VERSION "HNNBNNNYNNNNNNNNNNNNNNNNNNNNNNNNNNNNNNNNNN/4/%%%/4/'%**4NNN///"

NS_ :

BS_:

BU_: BMS_PlugIn CCU_VW526 GPM_PAG_PF Ladegeraet_PAG_PF LEH_PlugIn Motor_MED17_SIMOS8_PlugIn_PAG_PF Tester_DEV_PAG

BO_ 151 BMS_HYB_02: 8 BMS_PlugIn
 SG_ BMS_HYB_02_CHK : 0|8@1+ (1,0) [0|255] ""  Ladegeraet_PAG_PF,LEH_PlugIn,Motor_MED17_SIMOS8_PlugIn_PAG_PF
 SG_ BMS_HYB_02_BZ : 8|4@1+ (1,0) [0|15] ""  Ladegeraet_PAG_PF,LEH_PlugIn,Motor_MED17_SIMOS8_PlugIn_PAG_PF
 SG_ BMS_IstStrom : 12|12@1+ (0.25,-511) [-511|512.25] "Unit_Amper"  Ladegeraet_PAG_PF,LEH_PlugIn,Motor_MED17_SIMOS8_PlugIn_PAG_PF
 SG_ BMS_IstSpannung : 24|12@1+ (0.25,0) [0|1023.25] "Unit_Volt"  Ladegeraet_PAG_PF,LEH_PlugIn,Motor_MED17_SIMOS8_PlugIn_PAG_PF
 SG_ BMS_IstModus : 36|3@1+ (1,0) [0|7] ""  Ladegeraet_PAG_PF,LEH_PlugIn,Motor_MED17_SIMOS8_PlugIn_PAG_PF
 SG_ BMS_SleepInd : 39|1@1+ (1,0) [0|1] ""  Motor_MED17_SIMOS8_PlugIn_PAG_PF
 SG_ BMS_IsoMessungAktiv : 40|1@1+ (1,0) [0|1] ""  Ladegeraet_PAG_PF,LEH_PlugIn,Motor_MED17_SIMOS8_PlugIn_PAG_PF
 SG_ BMS_Init_abgeschlossen : 41|1@1+ (1,0) [0|1] ""  Ladegeraet_PAG_PF,LEH_PlugIn,Motor_MED17_SIMOS8_PlugIn_PAG_PF
 SG_ BMS_Status_Spgfreiheit : 42|2@1+ (1,0) [0|3] "" Vector__XXX
 SG_ BMS_Fehler_Notabschaltung_Crash : 49|1@1+ (1,0) [0|1] ""  Ladegeraet_PAG_PF,LEH_PlugIn,Motor_MED17_SIMOS8_PlugIn_PAG_PF
 SG_ BMS_Fehler_Notabschaltung_Pilot : 50|1@1+ (1,0) [0|1] ""  Ladegeraet_PAG_PF,LEH_PlugIn,Motor_MED17_SIMOS8_PlugIn_PAG_PF
 SG_ BMS_Fehler_HVBattAbschaltung_Anf : 51|1@1+ (1,0) [0|1] ""  Ladegeraet_PAG_PF,LEH_PlugIn,Motor_MED17_SIMOS8_PlugIn_PAG_PF
 SG_ BMS_Fehler_HVBattAbschaltung : 52|1@1+ (1,0) [0|1] ""  Ladegeraet_PAG_PF,LEH_PlugIn,Motor_MED17_SIMOS8_PlugIn_PAG_PF
 SG_ BMS_Fehler_HS_verschweisst : 53|1@1+ (1,0) [0|1] ""  Ladegeraet_PAG_PF,LEH_PlugIn,Motor_MED17_SIMOS8_PlugIn_PAG_PF
 SG_ BMS_Fehler_HS_offen : 54|1@1+ (1,0) [0|1] ""  Ladegeraet_PAG_PF
 SG_ BMS_Fehler_Leistungsred : 55|1@1+ (1,0) [0|1] ""  Ladegeraet_PAG_PF,LEH_PlugIn,Motor_MED17_SIMOS8_PlugIn_PAG_PF
 SG_ BMS_Fehler_Isolation : 56|1@1+ (1,0) [0|1] ""  Ladegeraet_PAG_PF,LEH_PlugIn,Motor_MED17_SIMOS8_PlugIn_PAG_PF
 SG_ BMS_Fehler_Kaltstartleistung : 57|1@1+ (1,0) [0|1] ""  Motor_MED17_SIMOS8_PlugIn_PAG_PF
 SG_ BMS_Fehler_Pilot : 58|1@1+ (1,0) [0|1] ""  Ladegeraet_PAG_PF
 SG_ BMS_Fehler_Sicherung : 59|1@1+ (1,0) [0|1] ""  Ladegeraet_PAG_PF
 SG_ BMS_Status_ServiceDisconnect : 60|1@1+ (1,0) [0|1] "" Vector__XXX
 SG_ BMS_Status_Spannungsfreiheit : 61|2@1+ (1,0) [0|3] "" Vector__XXX
 SG_ BMS_Notfallkuehlung : 63|1@1+ (1,0) [0|1] "" Vector__XXX

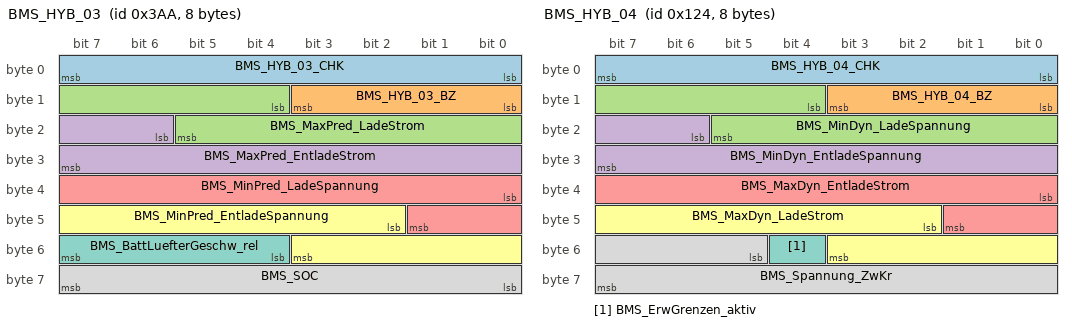
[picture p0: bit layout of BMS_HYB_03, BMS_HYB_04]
BO_ 938 BMS_HYB_03: 8 BMS_PlugIn
 SG_ BMS_HYB_03_CHK : 0|8@1+ (1,0) [0|255] ""  Ladegeraet_PAG_PF,LEH_PlugIn,Motor_MED17_SIMOS8_PlugIn_PAG_PF
 SG_ BMS_HYB_03_BZ : 8|4@1+ (1,0) [0|15] ""  Ladegeraet_PAG_PF,LEH_PlugIn,Motor_MED17_SIMOS8_PlugIn_PAG_PF
 SG_ BMS_MaxPred_LadeStrom : 12|10@1+ (1,0) [0|1022] "Unit_Amper"  Ladegeraet_PAG_PF,LEH_PlugIn,Motor_MED17_SIMOS8_PlugIn_PAG_PF
 SG_ BMS_MaxPred_EntladeStrom : 22|10@1+ (1,0) [0|1022] "Unit_Amper"  LEH_PlugIn,Motor_MED17_SIMOS8_PlugIn_PAG_PF
 SG_ BMS_MinPred_LadeSpannung : 32|10@1+ (1,0) [0|1022] "Unit_Volt"  LEH_PlugIn,Motor_MED17_SIMOS8_PlugIn_PAG_PF
 SG_ BMS_MinPred_EntladeSpannung : 42|10@1+ (1,0) [0|1022] "Unit_Volt"  LEH_PlugIn,Motor_MED17_SIMOS8_PlugIn_PAG_PF
 SG_ BMS_BattLuefterGeschw_rel : 52|4@1+ (10,0) [0|100] "Unit_PerCent"  LEH_PlugIn,Motor_MED17_SIMOS8_PlugIn_PAG_PF
 SG_ BMS_SOC : 56|8@1+ (0.4,0) [0|100] "Unit_PerCent"  Ladegeraet_PAG_PF,LEH_PlugIn,Motor_MED17_SIMOS8_PlugIn_PAG_PF

BO_ 292 BMS_HYB_04: 8 BMS_PlugIn
 SG_ BMS_HYB_04_CHK : 0|8@1+ (1,0) [0|255] ""  Ladegeraet_PAG_PF,LEH_PlugIn,Motor_MED17_SIMOS8_PlugIn_PAG_PF
 SG_ BMS_HYB_04_BZ : 8|4@1+ (1,0) [0|15] ""  Ladegeraet_PAG_PF,LEH_PlugIn,Motor_MED17_SIMOS8_PlugIn_PAG_PF
 SG_ BMS_MinDyn_LadeSpannung : 12|10@1+ (1,0) [0|1022] "Unit_Volt"  Ladegeraet_PAG_PF,LEH_PlugIn,Motor_MED17_SIMOS8_PlugIn_PAG_PF
 SG_ BMS_MinDyn_EntladeSpannung : 22|10@1+ (1,0) [0|1022] "Unit_Volt"  LEH_PlugIn,Motor_MED17_SIMOS8_PlugIn_PAG_PF
 SG_ BMS_MaxDyn_EntladeStrom : 32|10@1+ (1,0) [0|1022] "Unit_Amper"  LEH_PlugIn,Motor_MED17_SIMOS8_PlugIn_PAG_PF
 SG_ BMS_MaxDyn_LadeStrom : 42|10@1+ (1,0) [0|1022] "Unit_Amper"  Ladegeraet_PAG_PF,LEH_PlugIn,Motor_MED17_SIMOS8_PlugIn_PAG_PF
 SG_ BMS_ErwGrenzen_aktiv : 52|1@1+ (1,0) [0|1] ""  LEH_PlugIn,Motor_MED17_SIMOS8_PlugIn_PAG_PF
 SG_ BMS_Spannung_ZwKr : 53|11@1+ (0.5,0) [0|1022.5] "Unit_Volt" Vector__XXX

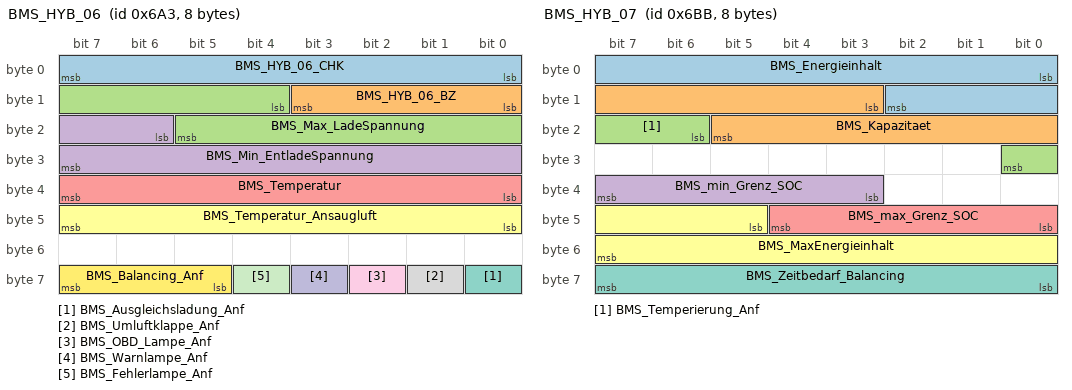
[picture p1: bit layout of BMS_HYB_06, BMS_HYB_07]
BO_ 1699 BMS_HYB_06: 8 BMS_PlugIn
 SG_ BMS_HYB_06_CHK : 0|8@1+ (1,0) [0|255] ""  Ladegeraet_PAG_PF,LEH_PlugIn,Motor_MED17_SIMOS8_PlugIn_PAG_PF
 SG_ BMS_HYB_06_BZ : 8|4@1+ (1,0) [0|15] ""  Ladegeraet_PAG_PF,LEH_PlugIn,Motor_MED17_SIMOS8_PlugIn_PAG_PF
 SG_ BMS_Max_LadeSpannung : 12|10@1+ (1,0) [0|1021] "Unit_Volt"  Ladegeraet_PAG_PF,LEH_PlugIn,Motor_MED17_SIMOS8_PlugIn_PAG_PF
 SG_ BMS_Min_EntladeSpannung : 22|10@1+ (1,0) [0|1021] "Unit_Volt"  Ladegeraet_PAG_PF,LEH_PlugIn,Motor_MED17_SIMOS8_PlugIn_PAG_PF
 SG_ BMS_Temperatur : 32|8@1+ (0.5,-40) [-40|86.5] "Unit_DegreCelsi"  Ladegeraet_PAG_PF,LEH_PlugIn,Motor_MED17_SIMOS8_PlugIn_PAG_PF
 SG_ BMS_Temperatur_Ansaugluft : 40|8@1+ (0.5,-40) [-40|86.5] "Unit_DegreCelsi"  LEH_PlugIn,Motor_MED17_SIMOS8_PlugIn_PAG_PF
 SG_ BMS_Ausgleichsladung_Anf : 56|1@1+ (1,0) [0|1] ""  Ladegeraet_PAG_PF,LEH_PlugIn,Motor_MED17_SIMOS8_PlugIn_PAG_PF
 SG_ BMS_Umluftklappe_Anf : 57|1@1+ (1,0) [0|1] ""  LEH_PlugIn,Motor_MED17_SIMOS8_PlugIn_PAG_PF
 SG_ BMS_OBD_Lampe_Anf : 58|1@1+ (1,0) [0|1] ""  LEH_PlugIn,Motor_MED17_SIMOS8_PlugIn_PAG_PF
 SG_ BMS_Warnlampe_Anf : 59|1@1+ (1,0) [0|1] ""  LEH_PlugIn,Motor_MED17_SIMOS8_PlugIn_PAG_PF
 SG_ BMS_Fehlerlampe_Anf : 60|1@1+ (1,0) [0|1] ""  LEH_PlugIn,Motor_MED17_SIMOS8_PlugIn_PAG_PF
 SG_ BMS_Balancing_Anf : 61|3@1+ (1,0) [0|7] "" Vector__XXX

BO_ 1723 BMS_HYB_07: 8 BMS_PlugIn
 SG_ BMS_Energieinhalt : 0|11@1+ (50,0) [0|102250] "Unit_WattHour"  Ladegeraet_PAG_PF,Motor_MED17_SIMOS8_PlugIn_PAG_PF
 SG_ BMS_Kapazitaet : 11|11@1+ (0.1,0) [0|204.6] "Unit_AmperHour"  Ladegeraet_PAG_PF,Motor_MED17_SIMOS8_PlugIn_PAG_PF
 SG_ BMS_Temperierung_Anf : 22|3@1+ (1,0) [0|7] ""  Ladegeraet_PAG_PF,Motor_MED17_SIMOS8_PlugIn_PAG_PF
 SG_ BMS_min_Grenz_SOC : 35|5@1+ (1,0) [0|30] "Unit_PerCent" Vector__XXX
 SG_ BMS_max_Grenz_SOC : 40|5@1+ (1,70) [70|100] "Unit_PerCent" Vector__XXX
 SG_ BMS_MaxEnergieinhalt : 45|11@1+ (50,0) [0|102250] "" Vector__XXX
 SG_ BMS_Zeitbedarf_Balancing : 56|8@1+ (1,0) [0|250] "Unit_Minut" Vector__XXX

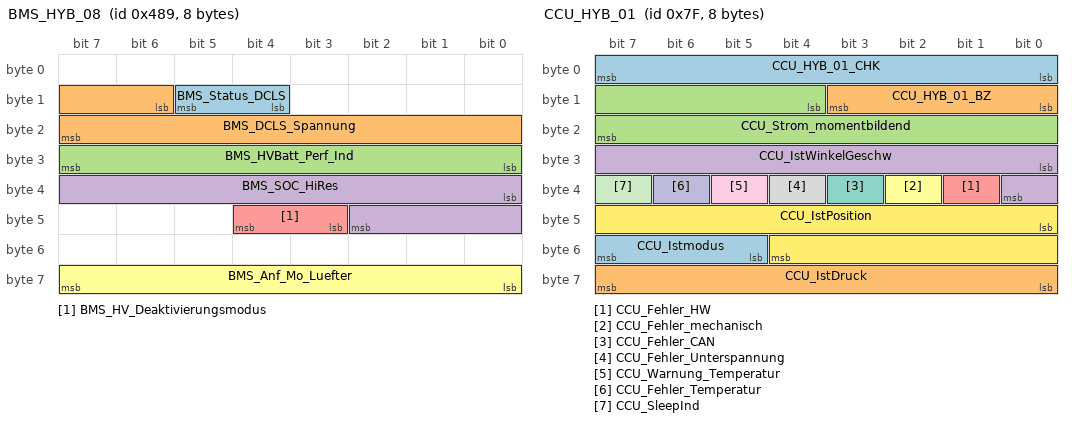
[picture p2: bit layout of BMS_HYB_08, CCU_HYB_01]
BO_ 1161 BMS_HYB_08: 8 BMS_PlugIn
 SG_ BMS_Status_DCLS : 12|2@1+ (1,0) [0|3] ""  Ladegeraet_PAG_PF
 SG_ BMS_DCLS_Spannung : 14|10@1+ (1,0) [0|1021] "Unit_Volt"  Ladegeraet_PAG_PF
 SG_ BMS_HVBatt_Perf_Ind : 24|8@1+ (0.4,0) [0|100] "Unit_PerCent"  Motor_MED17_SIMOS8_PlugIn_PAG_PF
 SG_ BMS_SOC_HiRes : 32|11@1+ (0.05,0) [0|100] "Unit_PerCent"  Motor_MED17_SIMOS8_PlugIn_PAG_PF
 SG_ BMS_HV_Deaktivierungsmodus : 43|2@1+ (1,0) [0|3] "" Vector__XXX
 SG_ BMS_Anf_Mo_Luefter : 56|8@1+ (0.4,0) [0|101.2] "Unit_PerCent"  Motor_MED17_SIMOS8_PlugIn_PAG_PF

BO_ 2617236992 CCP_BMS_CRO_01: 8 Tester_DEV_PAG
 SG_ CCP_BMS_CRO_01_Data : 0|64@1+ (1,0) [0|1] ""  BMS_PlugIn

BO_ 2281692672 CCP_BMS_CRO_02: 8 Tester_DEV_PAG
 SG_ CCP_BMS_CRO_02_Data : 0|64@1+ (1,0) [0|1] ""  BMS_PlugIn

BO_ 2617236993 CCP_BMS_DTO_01: 8 BMS_PlugIn
 SG_ CCP_BMS_DTO_01_Data : 0|64@1+ (1,0) [0|1] ""  Tester_DEV_PAG

BO_ 2281692673 CCP_BMS_DTO_02: 8 BMS_PlugIn
 SG_ CCP_BMS_DTO_02_Data : 0|64@1+ (1,0) [0|1] ""  Tester_DEV_PAG

BO_ 2617239041 CCP_EMotor_01_DTO_01: 8 LEH_PlugIn
 SG_ CCP_LE_DTO_01_Data : 0|64@1+ (1,0) [0|1] ""  Tester_DEV_PAG

BO_ 2566690560 CCP_GPM_CRO_01: 8 Tester_DEV_PAG
 SG_ CCP_GPM_CRO_01_Data : 0|64@1+ (1,0) [0|1] ""  GPM_PAG_PF

BO_ 2566690561 CCP_GPM_DTO_01: 8 GPM_PAG_PF
 SG_ CCP_GPM_DTO_01_Data : 0|64@1+ (1,0) [0|1] ""  Tester_DEV_PAG

BO_ 2617124352 CCP_Ladegeraet_CRO_01: 8 Tester_DEV_PAG
 SG_ CCP_Ladegeraet_CRO_01_Data : 0|64@1+ (1,0) [0|1.84467440737096E+019] ""  Ladegeraet_PAG_PF

BO_ 2617124353 CCP_Ladegeraet_DTO_01: 8 Ladegeraet_PAG_PF
 SG_ CCP_Ladegeraet_DTO_01_Data : 0|64@1+ (1,0) [0|1.84467440737096E+019] ""  Tester_DEV_PAG

BO_ 1666 CCP_LE_CRO_01: 8 Tester_DEV_PAG
 SG_ CCP_LE_CRO_01_Data : 0|64@1+ (1,0) [0|1] ""  LEH_PlugIn

BO_ 127 CCU_HYB_01: 8 CCU_VW526
 SG_ CCU_HYB_01_CHK : 0|8@1+ (1,0) [0|255] ""  Motor_MED17_SIMOS8_PlugIn_PAG_PF
 SG_ CCU_HYB_01_BZ : 8|4@1+ (1,0) [0|15] ""  Motor_MED17_SIMOS8_PlugIn_PAG_PF
 SG_ CCU_Strom_momentbildend : 12|12@1+ (0.25,-511) [-511|512.25] "Unit_Amper"  Motor_MED17_SIMOS8_PlugIn_PAG_PF
 SG_ CCU_IstWinkelGeschw : 24|9@1+ (200,-51000) [-51000|50800] "Unit_DegreOfArcPerSecon"  Motor_MED17_SIMOS8_PlugIn_PAG_PF
 SG_ CCU_Fehler_HW : 33|1@1+ (1,0) [0|1] ""  Motor_MED17_SIMOS8_PlugIn_PAG_PF
 SG_ CCU_Fehler_mechanisch : 34|1@1+ (1,0) [0|1] ""  Motor_MED17_SIMOS8_PlugIn_PAG_PF
 SG_ CCU_Fehler_CAN : 35|1@1+ (1,0) [0|1] ""  Motor_MED17_SIMOS8_PlugIn_PAG_PF
 SG_ CCU_Fehler_Unterspannung : 36|1@1+ (1,0) [0|1] ""  Motor_MED17_SIMOS8_PlugIn_PAG_PF
 SG_ CCU_Warnung_Temperatur : 37|1@1+ (1,0) [0|1] ""  Motor_MED17_SIMOS8_PlugIn_PAG_PF
 SG_ CCU_Fehler_Temperatur : 38|1@1+ (1,0) [0|1] ""  Motor_MED17_SIMOS8_PlugIn_PAG_PF
 SG_ CCU_SleepInd : 39|1@1+ (1,0) [0|1] ""  Motor_MED17_SIMOS8_PlugIn_PAG_PF
 SG_ CCU_IstPosition : 40|13@1+ (1,0) [0|6945] "Unit_DegreOfArc"  Motor_MED17_SIMOS8_PlugIn_PAG_PF
 SG_ CCU_Istmodus : 53|3@1+ (1,0) [0|7] ""  Motor_MED17_SIMOS8_PlugIn_PAG_PF
 SG_ CCU_IstDruck : 56|8@1+ (0.2,0) [0|50.6] "Unit_Bar"  Motor_MED17_SIMOS8_PlugIn_PAG_PF

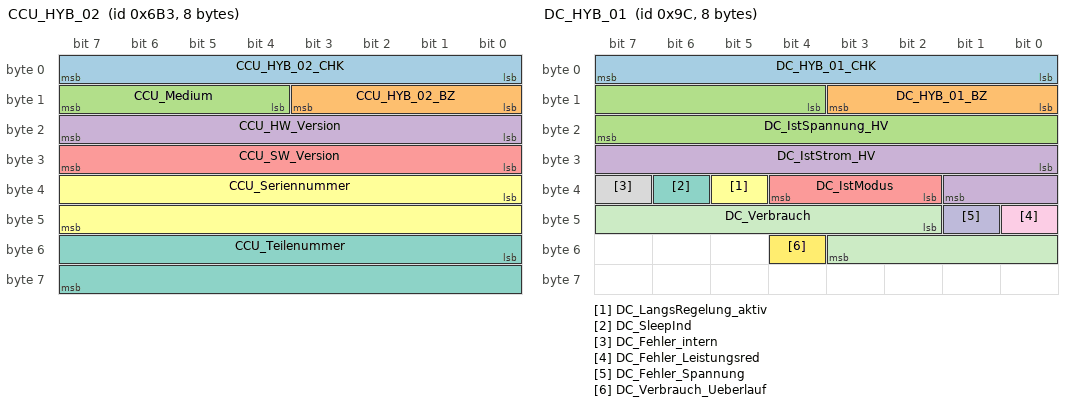
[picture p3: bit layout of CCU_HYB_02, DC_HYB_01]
BO_ 1715 CCU_HYB_02: 8 CCU_VW526
 SG_ CCU_HYB_02_CHK : 0|8@1+ (1,0) [0|255] ""  Motor_MED17_SIMOS8_PlugIn_PAG_PF
 SG_ CCU_HYB_02_BZ : 8|4@1+ (1,0) [0|15] ""  Motor_MED17_SIMOS8_PlugIn_PAG_PF
 SG_ CCU_Medium : 12|4@1+ (1,0) [0|15] ""  Motor_MED17_SIMOS8_PlugIn_PAG_PF
 SG_ CCU_HW_Version : 16|8@1+ (1,0) [0|255] ""  Motor_MED17_SIMOS8_PlugIn_PAG_PF
 SG_ CCU_SW_Version : 24|8@1+ (1,0) [0|255] ""  Motor_MED17_SIMOS8_PlugIn_PAG_PF
 SG_ CCU_Seriennummer : 32|16@1+ (1,0) [0|65535] ""  Motor_MED17_SIMOS8_PlugIn_PAG_PF
 SG_ CCU_Teilenummer : 48|16@1+ (1,0) [0|65535] ""  Motor_MED17_SIMOS8_PlugIn_PAG_PF

BO_ 156 DC_HYB_01: 8 LEH_PlugIn
 SG_ DC_HYB_01_CHK : 0|8@1+ (1,0) [0|255] ""  Motor_MED17_SIMOS8_PlugIn_PAG_PF
 SG_ DC_HYB_01_BZ : 8|4@1+ (1,0) [0|15] ""  Motor_MED17_SIMOS8_PlugIn_PAG_PF
 SG_ DC_IstSpannung_HV : 12|12@1+ (0.25,0) [0|1023.25] "Unit_Volt"  BMS_PlugIn,Motor_MED17_SIMOS8_PlugIn_PAG_PF
 SG_ DC_IstStrom_HV : 24|10@1+ (0.1,-51.1) [-51.1|51] "Unit_Amper"  BMS_PlugIn,Ladegeraet_PAG_PF,Motor_MED17_SIMOS8_PlugIn_PAG_PF
 SG_ DC_IstModus : 34|3@1+ (1,0) [0|7] ""  Motor_MED17_SIMOS8_PlugIn_PAG_PF
 SG_ DC_LangsRegelung_aktiv : 37|1@1+ (1,0) [0|1] ""  Motor_MED17_SIMOS8_PlugIn_PAG_PF
 SG_ DC_SleepInd : 38|1@1+ (1,0) [0|1] ""  Motor_MED17_SIMOS8_PlugIn_PAG_PF
 SG_ DC_Fehler_intern : 39|1@1+ (1,0) [0|1] ""  Motor_MED17_SIMOS8_PlugIn_PAG_PF
 SG_ DC_Fehler_Leistungsred : 40|1@1+ (1,0) [0|1] ""  Motor_MED17_SIMOS8_PlugIn_PAG_PF
 SG_ DC_Fehler_Spannung : 41|1@1+ (1,0) [0|1] ""  Motor_MED17_SIMOS8_PlugIn_PAG_PF
 SG_ DC_Verbrauch : 42|10@1+ (1,0) [0|1023] "Unit_WattSecond" Vector__XXX
 SG_ DC_Verbrauch_Ueberlauf : 52|1@1+ (1,0) [0|1] "" Vector__XXX

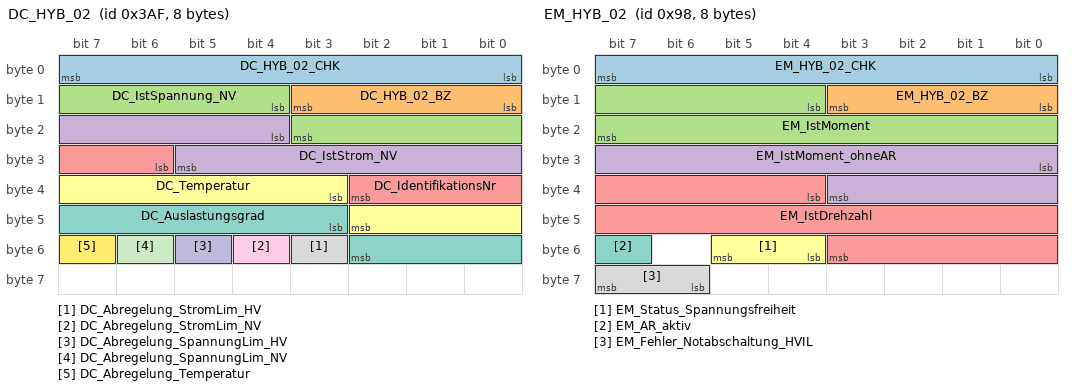
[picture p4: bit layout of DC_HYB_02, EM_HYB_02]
BO_ 943 DC_HYB_02: 8 LEH_PlugIn
 SG_ DC_HYB_02_CHK : 0|8@1+ (1,0) [0|255] ""  Motor_MED17_SIMOS8_PlugIn_PAG_PF
 SG_ DC_HYB_02_BZ : 8|4@1+ (1,0) [0|15] ""  Motor_MED17_SIMOS8_PlugIn_PAG_PF
 SG_ DC_IstSpannung_NV : 12|8@1+ (0.1,0) [0|25.3] "Unit_Volt"  Motor_MED17_SIMOS8_PlugIn_PAG_PF
 SG_ DC_IstStrom_NV : 20|10@1+ (1,-511) [-511|510] "Unit_Amper"  Motor_MED17_SIMOS8_PlugIn_PAG_PF
 SG_ DC_IdentifikationsNr : 30|5@1+ (1,0) [0|31] ""  Motor_MED17_SIMOS8_PlugIn_PAG_PF
 SG_ DC_Temperatur : 35|8@1+ (1,-40) [-40|213] "Unit_DegreCelsi"  Motor_MED17_SIMOS8_PlugIn_PAG_PF
 SG_ DC_Auslastungsgrad : 43|8@1+ (0.4,0) [0|101.6] "Unit_PerCent"  Motor_MED17_SIMOS8_PlugIn_PAG_PF
 SG_ DC_Abregelung_StromLim_HV : 51|1@1+ (1,0) [0|1] ""  Motor_MED17_SIMOS8_PlugIn_PAG_PF
 SG_ DC_Abregelung_StromLim_NV : 52|1@1+ (1,0) [0|1] ""  Motor_MED17_SIMOS8_PlugIn_PAG_PF
 SG_ DC_Abregelung_SpannungLim_HV : 53|1@1+ (1,0) [0|1] ""  Motor_MED17_SIMOS8_PlugIn_PAG_PF
 SG_ DC_Abregelung_SpannungLim_NV : 54|1@1+ (1,0) [0|1] ""  Motor_MED17_SIMOS8_PlugIn_PAG_PF
 SG_ DC_Abregelung_Temperatur : 55|1@1+ (1,0) [0|1] ""  Motor_MED17_SIMOS8_PlugIn_PAG_PF

BO_ 2617235968 DEV_BMS_Resp_00: 8 BMS_PlugIn
 SG_ DEV_BMS_Resp_00_Data : 0|64@1+ (1,0) [0|1.84467440737096E+019] ""  Tester_DEV_PAG

BO_ 2617235969 DEV_BMS_Resp_01: 8 BMS_PlugIn
 SG_ DEV_BMS_Resp_01_Data : 0|64@1+ (1,0) [0|1.84467440737096E+019] ""  Tester_DEV_PAG

BO_ 2617235970 DEV_BMS_Resp_02: 8 BMS_PlugIn
 SG_ DEV_BMS_Resp_02_Data : 0|64@1+ (1,0) [0|1.84467440737096E+019] ""  Tester_DEV_PAG

BO_ 2617235971 DEV_BMS_Resp_03: 8 BMS_PlugIn
 SG_ DEV_BMS_Resp_03_Data : 0|64@1+ (1,0) [0|1.84467440737096E+019] ""  Tester_DEV_PAG

BO_ 2617235972 DEV_BMS_Resp_04: 8 BMS_PlugIn
 SG_ DEV_BMS_Resp_04_Data : 0|64@1+ (1,0) [0|1.84467440737096E+019] ""  Tester_DEV_PAG

BO_ 2617235973 DEV_BMS_Resp_05: 8 BMS_PlugIn
 SG_ DEV_BMS_Resp_05_Data : 0|64@1+ (1,0) [0|1.84467440737096E+019] ""  Tester_DEV_PAG

BO_ 2617235974 DEV_BMS_Resp_06: 8 BMS_PlugIn
 SG_ DEV_BMS_Resp_06_Data : 0|64@1+ (1,0) [0|1.84467440737096E+019] ""  Tester_DEV_PAG

BO_ 2617235975 DEV_BMS_Resp_07: 8 BMS_PlugIn
 SG_ DEV_BMS_Resp_07_Data : 0|64@1+ (1,0) [0|1.84467440737096E+019] ""  Tester_DEV_PAG

BO_ 2566821632 DEV_GPM_Func_Req: 8 Tester_DEV_PAG
 SG_ DEV_GPM_Func_Req_Data : 0|64@1+ (1,0) [0|1.84467440737096E+019] ""  GPM_PAG_PF

BO_ 2566821633 DEV_GPM_Req_01: 8 Tester_DEV_PAG
 SG_ DEV_GPM_Req_01_Data : 0|64@1+ (1,0) [0|1.84467440737096E+019] ""  GPM_PAG_PF

BO_ 2566821634 DEV_GPM_Resp_01: 8 GPM_PAG_PF
 SG_ DEV_GPM_Resp_01_Data : 0|64@1+ (1,0) [0|1.84467440737096E+019] ""  Tester_DEV_PAG

BO_ 2617123328 DEV_Ladegeraet_Req_01: 8 Tester_DEV_PAG
 SG_ DEV_Ladegeraet_Req_01_Data : 0|64@1+ (1,0) [0|1.84467440737096E+019] ""  Ladegeraet_PAG_PF

BO_ 2617123329 DEV_Ladegeraet_Resp_01: 8 Ladegeraet_PAG_PF
 SG_ DEV_Ladegeraet_Resp_01_Data : 0|64@1+ (1,0) [0|1.84467440737096E+019] ""  Tester_DEV_PAG

BO_ 2617123330 DEV_Ladegeraet_Resp_02: 8 Ladegeraet_PAG_PF
 SG_ DEV_Ladegeraet_Resp_02_Data : 0|64@1+ (1,0) [0|1.84467440737096E+019] ""  Tester_DEV_PAG

BO_ 2617123331 DEV_Ladegeraet_Resp_03: 8 Ladegeraet_PAG_PF
 SG_ DEV_Ladegeraet_Resp_03_Data : 0|64@1+ (1,0) [0|1.84467440737096E+019] ""  Tester_DEV_PAG

BO_ 2617123332 DEV_Ladegeraet_Resp_04: 8 Ladegeraet_PAG_PF
 SG_ DEV_Ladegeraet_Resp_04_Data : 0|64@1+ (1,0) [0|1.84467440737096E+019] ""  Tester_DEV_PAG

BO_ 2617123333 DEV_Ladegeraet_Resp_05: 8 Ladegeraet_PAG_PF
 SG_ DEV_Ladegeraet_Resp_05_Data : 0|64@1+ (1,0) [0|1.84467440737096E+019] ""  Tester_DEV_PAG

BO_ 2617123334 DEV_Ladegeraet_Resp_06: 8 Ladegeraet_PAG_PF
 SG_ DEV_Ladegeraet_Resp_06_Data : 0|64@1+ (1,0) [0|1.84467440737096E+019] ""  Tester_DEV_PAG

BO_ 152 EM_HYB_02: 8 LEH_PlugIn
 SG_ EM_HYB_02_CHK : 0|8@1+ (1,0) [0|255] ""  Motor_MED17_SIMOS8_PlugIn_PAG_PF
 SG_ EM_HYB_02_BZ : 8|4@1+ (1,0) [0|15] ""  Motor_MED17_SIMOS8_PlugIn_PAG_PF
 SG_ EM_IstMoment : 12|12@1+ (0.25,-511) [-511|512.25] "Unit_NewtoMeter"  Motor_MED17_SIMOS8_PlugIn_PAG_PF
 SG_ EM_IstMoment_ohneAR : 24|12@1+ (0.25,-511) [-511|512.25] "Unit_NewtoMeter"  Motor_MED17_SIMOS8_PlugIn_PAG_PF
 SG_ EM_IstDrehzahl : 36|16@1+ (0.5,-10000) [-10000|22766.5] "Unit_MinutInver"  Motor_MED17_SIMOS8_PlugIn_PAG_PF
 SG_ EM_Status_Spannungsfreiheit : 52|2@1+ (1,0) [0|3] "" Vector__XXX
 SG_ EM_AR_aktiv : 55|1@1+ (1,0) [0|1] ""  Motor_MED17_SIMOS8_PlugIn_PAG_PF
 SG_ EM_Fehler_Notabschaltung_HVIL : 62|2@1+ (1,0) [0|3] "" Vector__XXX

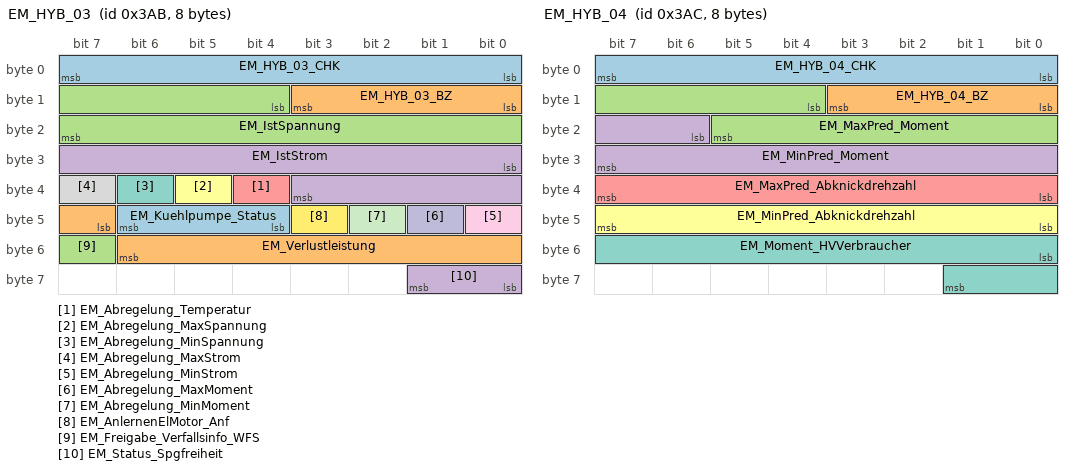
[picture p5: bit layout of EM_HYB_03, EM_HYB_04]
BO_ 939 EM_HYB_03: 8 LEH_PlugIn
 SG_ EM_HYB_03_CHK : 0|8@1+ (1,0) [0|255] ""  BMS_PlugIn,Motor_MED17_SIMOS8_PlugIn_PAG_PF
 SG_ EM_HYB_03_BZ : 8|4@1+ (1,0) [0|15] ""  BMS_PlugIn,Motor_MED17_SIMOS8_PlugIn_PAG_PF
 SG_ EM_IstSpannung : 12|12@1+ (0.25,0) [0|1023.25] "Unit_Volt"  BMS_PlugIn,Motor_MED17_SIMOS8_PlugIn_PAG_PF
 SG_ EM_IstStrom : 24|12@1+ (0.25,-511) [-511|512.25] "Unit_Amper"  Motor_MED17_SIMOS8_PlugIn_PAG_PF
 SG_ EM_Abregelung_Temperatur : 36|1@1+ (1,0) [0|1] ""  Motor_MED17_SIMOS8_PlugIn_PAG_PF
 SG_ EM_Abregelung_MaxSpannung : 37|1@1+ (1,0) [0|1] ""  Motor_MED17_SIMOS8_PlugIn_PAG_PF
 SG_ EM_Abregelung_MinSpannung : 38|1@1+ (1,0) [0|1] ""  Motor_MED17_SIMOS8_PlugIn_PAG_PF
 SG_ EM_Abregelung_MaxStrom : 39|1@1+ (1,0) [0|1] ""  Motor_MED17_SIMOS8_PlugIn_PAG_PF
 SG_ EM_Abregelung_MinStrom : 40|1@1+ (1,0) [0|1] ""  Motor_MED17_SIMOS8_PlugIn_PAG_PF
 SG_ EM_Abregelung_MaxMoment : 41|1@1+ (1,0) [0|1] ""  Motor_MED17_SIMOS8_PlugIn_PAG_PF
 SG_ EM_Abregelung_MinMoment : 42|1@1+ (1,0) [0|1] ""  Motor_MED17_SIMOS8_PlugIn_PAG_PF
 SG_ EM_AnlernenElMotor_Anf : 43|1@1+ (1,0) [0|1] ""  Motor_MED17_SIMOS8_PlugIn_PAG_PF
 SG_ EM_Kuehlpumpe_Status : 44|3@1+ (1,0) [0|7] "" Vector__XXX
 SG_ EM_Verlustleistung : 47|8@1+ (20,0) [0|5000] "Unit_Watt" Vector__XXX
 SG_ EM_Freigabe_Verfallsinfo_WFS : 55|1@1+ (1,0) [0|1] "" Vector__XXX
 SG_ EM_Status_Spgfreiheit : 56|2@1+ (1,0) [0|3] ""  BMS_PlugIn

BO_ 940 EM_HYB_04: 8 LEH_PlugIn
 SG_ EM_HYB_04_CHK : 0|8@1+ (1,0) [0|255] ""  Motor_MED17_SIMOS8_PlugIn_PAG_PF
 SG_ EM_HYB_04_BZ : 8|4@1+ (1,0) [0|15] ""  Motor_MED17_SIMOS8_PlugIn_PAG_PF
 SG_ EM_MaxPred_Moment : 12|10@1+ (1,-511) [-511|511] "Unit_NewtoMeter"  Motor_MED17_SIMOS8_PlugIn_PAG_PF
 SG_ EM_MinPred_Moment : 22|10@1+ (1,-511) [-511|511] "Unit_NewtoMeter"  Motor_MED17_SIMOS8_PlugIn_PAG_PF
 SG_ EM_MaxPred_Abknickdrehzahl : 32|8@1+ (50,0) [0|12700] "Unit_MinutInver"  Motor_MED17_SIMOS8_PlugIn_PAG_PF
 SG_ EM_MinPred_Abknickdrehzahl : 40|8@1+ (50,0) [0|12700] "Unit_MinutInver"  Motor_MED17_SIMOS8_PlugIn_PAG_PF
 SG_ EM_Moment_HVVerbraucher : 48|10@1+ (1,-511) [-511|511] "Unit_NewtoMeter"  Motor_MED17_SIMOS8_PlugIn_PAG_PF

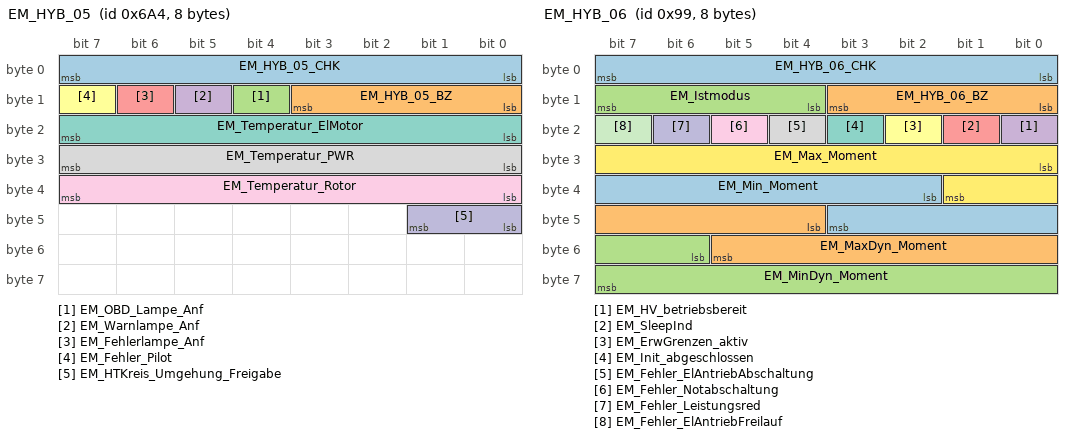
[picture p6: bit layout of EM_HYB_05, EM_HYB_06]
BO_ 1700 EM_HYB_05: 8 LEH_PlugIn
 SG_ EM_HYB_05_CHK : 0|8@1+ (1,0) [0|255] ""  Motor_MED17_SIMOS8_PlugIn_PAG_PF
 SG_ EM_HYB_05_BZ : 8|4@1+ (1,0) [0|15] ""  Motor_MED17_SIMOS8_PlugIn_PAG_PF
 SG_ EM_OBD_Lampe_Anf : 12|1@1+ (1,0) [0|1] ""  Motor_MED17_SIMOS8_PlugIn_PAG_PF
 SG_ EM_Warnlampe_Anf : 13|1@1+ (1,0) [0|1] ""  Motor_MED17_SIMOS8_PlugIn_PAG_PF
 SG_ EM_Fehlerlampe_Anf : 14|1@1+ (1,0) [0|1] ""  Motor_MED17_SIMOS8_PlugIn_PAG_PF
 SG_ EM_Fehler_Pilot : 15|1@1+ (1,0) [0|1] "" Vector__XXX
 SG_ EM_Temperatur_ElMotor : 16|8@1+ (1,-40) [-40|213] "Unit_DegreCelsi"  Motor_MED17_SIMOS8_PlugIn_PAG_PF
 SG_ EM_Temperatur_PWR : 24|8@1+ (1,-40) [-40|213] "Unit_DegreCelsi"  Motor_MED17_SIMOS8_PlugIn_PAG_PF
 SG_ EM_Temperatur_Rotor : 32|8@1+ (1,-40) [-40|213] "Unit_DegreCelsi"  Motor_MED17_SIMOS8_PlugIn_PAG_PF
 SG_ EM_HTKreis_Umgehung_Freigabe : 40|2@1+ (1,0) [0|3] ""  Motor_MED17_SIMOS8_PlugIn_PAG_PF

BO_ 153 EM_HYB_06: 8 LEH_PlugIn
 SG_ EM_HYB_06_CHK : 0|8@1+ (1,0) [0|255] ""  Motor_MED17_SIMOS8_PlugIn_PAG_PF
 SG_ EM_HYB_06_BZ : 8|4@1+ (1,0) [0|15] ""  Motor_MED17_SIMOS8_PlugIn_PAG_PF
 SG_ EM_Istmodus : 12|4@1+ (1,0) [0|15] ""  Motor_MED17_SIMOS8_PlugIn_PAG_PF
 SG_ EM_HV_betriebsbereit : 16|1@1+ (1,0) [0|1] ""  Motor_MED17_SIMOS8_PlugIn_PAG_PF
 SG_ EM_SleepInd : 17|1@1+ (1,0) [0|1] ""  Motor_MED17_SIMOS8_PlugIn_PAG_PF
 SG_ EM_ErwGrenzen_aktiv : 18|1@1+ (1,0) [0|1] ""  Motor_MED17_SIMOS8_PlugIn_PAG_PF
 SG_ EM_Init_abgeschlossen : 19|1@1+ (1,0) [0|1] ""  Motor_MED17_SIMOS8_PlugIn_PAG_PF
 SG_ EM_Fehler_ElAntriebAbschaltung : 20|1@1+ (1,0) [0|1] ""  Motor_MED17_SIMOS8_PlugIn_PAG_PF
 SG_ EM_Fehler_Notabschaltung : 21|1@1+ (1,0) [0|1] ""  Motor_MED17_SIMOS8_PlugIn_PAG_PF
 SG_ EM_Fehler_Leistungsred : 22|1@1+ (1,0) [0|1] ""  Motor_MED17_SIMOS8_PlugIn_PAG_PF
 SG_ EM_Fehler_ElAntriebFreilauf : 23|1@1+ (1,0) [0|1] ""  Motor_MED17_SIMOS8_PlugIn_PAG_PF
 SG_ EM_Max_Moment : 24|10@1+ (1,-511) [-511|511] "Unit_NewtoMeter"  Motor_MED17_SIMOS8_PlugIn_PAG_PF
 SG_ EM_Min_Moment : 34|10@1+ (1,-511) [-511|511] "Unit_NewtoMeter"  Motor_MED17_SIMOS8_PlugIn_PAG_PF
 SG_ EM_MaxDyn_Moment : 44|10@1+ (1,-511) [-511|511] "Unit_NewtoMeter"  Motor_MED17_SIMOS8_PlugIn_PAG_PF
 SG_ EM_MinDyn_Moment : 54|10@1+ (1,-511) [-511|511] "Unit_NewtoMeter"  Motor_MED17_SIMOS8_PlugIn_PAG_PF

BO_ 81 EM_HYB_07: 2 LEH_PlugIn
 SG_ EM_IstDrehzahl : 0|16@1+ (0.5,-10000) [-10000|22766.5] "Unit_MinutInver"  Motor_MED17_SIMOS8_PlugIn_PAG_PF

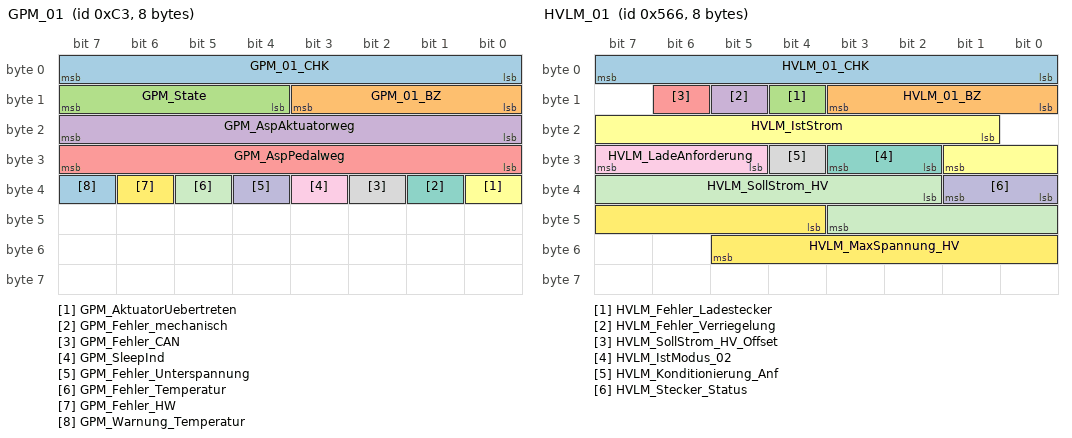
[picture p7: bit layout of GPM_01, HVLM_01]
BO_ 195 GPM_01: 8 GPM_PAG_PF
 SG_ GPM_01_CHK : 0|8@1+ (1,0) [0|255] ""  Motor_MED17_SIMOS8_PlugIn_PAG_PF
 SG_ GPM_01_BZ : 8|4@1+ (1,0) [0|15] ""  Motor_MED17_SIMOS8_PlugIn_PAG_PF
 SG_ GPM_State : 12|4@1+ (1,0) [0|15] ""  Motor_MED17_SIMOS8_PlugIn_PAG_PF
 SG_ GPM_AspAktuatorweg : 16|8@1+ (1,0) [0|100] "Unit_PerCent"  Motor_MED17_SIMOS8_PlugIn_PAG_PF
 SG_ GPM_AspPedalweg : 24|8@1+ (1,0) [0|100] "Unit_PerCent"  Motor_MED17_SIMOS8_PlugIn_PAG_PF
 SG_ GPM_AktuatorUebertreten : 32|1@1+ (1,0) [0|1] ""  Motor_MED17_SIMOS8_PlugIn_PAG_PF
 SG_ GPM_Fehler_mechanisch : 33|1@1+ (1,0) [0|1] ""  Motor_MED17_SIMOS8_PlugIn_PAG_PF
 SG_ GPM_Fehler_CAN : 34|1@1+ (1,0) [0|1] ""  Motor_MED17_SIMOS8_PlugIn_PAG_PF
 SG_ GPM_SleepInd : 35|1@1+ (1,0) [0|1] ""  Motor_MED17_SIMOS8_PlugIn_PAG_PF
 SG_ GPM_Fehler_Unterspannung : 36|1@1+ (1,0) [0|1] ""  Motor_MED17_SIMOS8_PlugIn_PAG_PF
 SG_ GPM_Fehler_Temperatur : 37|1@1+ (1,0) [0|1] ""  Motor_MED17_SIMOS8_PlugIn_PAG_PF
 SG_ GPM_Fehler_HW : 38|1@1+ (1,0) [0|1] ""  Motor_MED17_SIMOS8_PlugIn_PAG_PF
 SG_ GPM_Warnung_Temperatur : 39|1@1+ (1,0) [0|1] ""  Motor_MED17_SIMOS8_PlugIn_PAG_PF

BO_ 1705 GPM_02: 8 GPM_PAG_PF
 SG_ GPM_TeileNr_Mux M : 0|4@1+ (1,0) [0|15] ""  Motor_MED17_SIMOS8_PlugIn_PAG_PF
 SG_ GPM_TeileNr_Word_01 m0 : 16|16@1+ (1,0) [0|65535] ""  Motor_MED17_SIMOS8_PlugIn_PAG_PF
 SG_ GPM_TeileNr_Word_02 m1 : 16|16@1+ (1,0) [0|65535] ""  Motor_MED17_SIMOS8_PlugIn_PAG_PF
 SG_ GPM_TeileNr_Word_03 m2 : 16|16@1+ (1,0) [0|65535] ""  Motor_MED17_SIMOS8_PlugIn_PAG_PF
 SG_ GPM_TeileNr_Word_04 m3 : 16|16@1+ (1,0) [0|65535] ""  Motor_MED17_SIMOS8_PlugIn_PAG_PF
 SG_ GPM_TeileNr_Word_05 m4 : 16|16@1+ (1,0) [0|65535] ""  Motor_MED17_SIMOS8_PlugIn_PAG_PF
 SG_ GPM_TeileNr_Word_06 m5 : 16|16@1+ (1,0) [0|65535] ""  Motor_MED17_SIMOS8_PlugIn_PAG_PF
 SG_ GPM_TeileNr_Word_07 m6 : 16|16@1+ (1,0) [0|65535] ""  Motor_MED17_SIMOS8_PlugIn_PAG_PF
 SG_ GPM_TeileNr_Word_08 m7 : 16|16@1+ (1,0) [0|65535] ""  Motor_MED17_SIMOS8_PlugIn_PAG_PF
 SG_ GPM_TeileNr_Word_09 m8 : 16|16@1+ (1,0) [0|65535] ""  Motor_MED17_SIMOS8_PlugIn_PAG_PF
 SG_ GPM_TeileNr_Word_10 m9 : 16|16@1+ (1,0) [0|65535] ""  Motor_MED17_SIMOS8_PlugIn_PAG_PF
 SG_ GPM_TeileNr_Word_11 m10 : 16|16@1+ (1,0) [0|65535] ""  Motor_MED17_SIMOS8_PlugIn_PAG_PF
 SG_ GPM_TeileNr_Word_12 m11 : 16|16@1+ (1,0) [0|65535] ""  Motor_MED17_SIMOS8_PlugIn_PAG_PF
 SG_ GPM_TeileNr_Word_13 m12 : 16|16@1+ (1,0) [0|65535] ""  Motor_MED17_SIMOS8_PlugIn_PAG_PF
 SG_ GPM_TeileNr_Word_14 m13 : 16|16@1+ (1,0) [0|65535] ""  Motor_MED17_SIMOS8_PlugIn_PAG_PF
 SG_ GPM_TeileNr_Word_15 m14 : 16|16@1+ (1,0) [0|65535] ""  Motor_MED17_SIMOS8_PlugIn_PAG_PF
 SG_ GPM_TeileNr_Word_16 m15 : 16|16@1+ (1,0) [0|65535] ""  Motor_MED17_SIMOS8_PlugIn_PAG_PF
 SG_ GPM_Seriennummer : 32|16@1+ (1,0) [0|65535] ""  Motor_MED17_SIMOS8_PlugIn_PAG_PF
 SG_ GPM_HW_Version : 48|8@1+ (1,0) [0|255] ""  Motor_MED17_SIMOS8_PlugIn_PAG_PF
 SG_ GPM_SW_Version : 56|8@1+ (1,0) [0|255] ""  Motor_MED17_SIMOS8_PlugIn_PAG_PF

BO_ 1382 HVLM_01: 8 Ladegeraet_PAG_PF
 SG_ HVLM_01_CHK : 0|8@1+ (1,0) [0|255] ""  BMS_PlugIn,Motor_MED17_SIMOS8_PlugIn_PAG_PF
 SG_ HVLM_01_BZ : 8|4@1+ (1,0) [0|15] ""  BMS_PlugIn,Motor_MED17_SIMOS8_PlugIn_PAG_PF
 SG_ HVLM_Fehler_Ladestecker : 12|1@1+ (1,0) [0|1] "" Vector__XXX
 SG_ HVLM_Fehler_Verriegelung : 13|1@1+ (1,0) [0|1] "" Vector__XXX
 SG_ HVLM_SollStrom_HV_Offset : 14|1@1+ (1,0) [0|1] "" Vector__XXX
 SG_ HVLM_IstStrom : 17|9@1+ (1,-255) [-255|254] "Unit_Amper"  Motor_MED17_SIMOS8_PlugIn_PAG_PF
 SG_ HVLM_IstModus_02 : 26|2@1+ (1,0) [0|3] ""  Motor_MED17_SIMOS8_PlugIn_PAG_PF
 SG_ HVLM_Konditionierung_Anf : 28|1@1+ (1,0) [0|1] ""  Motor_MED17_SIMOS8_PlugIn_PAG_PF
 SG_ HVLM_LadeAnforderung : 29|3@1+ (1,0) [0|7] ""  Motor_MED17_SIMOS8_PlugIn_PAG_PF
 SG_ HVLM_Stecker_Status : 32|2@1+ (1,0) [0|3] ""  BMS_PlugIn,Motor_MED17_SIMOS8_PlugIn_PAG_PF
 SG_ HVLM_SollStrom_HV : 34|10@1+ (0.2,-102) [-102|102.2] "Unit_Amper" Vector__XXX
 SG_ HVLM_MaxSpannung_HV : 44|10@1+ (1,0) [0|1021] "Unit_Volt" Vector__XXX

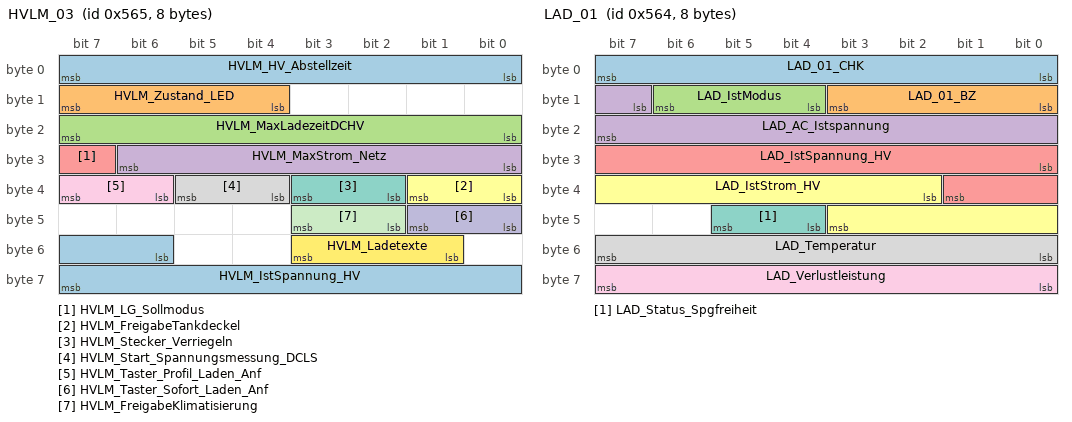
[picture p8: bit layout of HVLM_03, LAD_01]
BO_ 1381 HVLM_03: 8 Ladegeraet_PAG_PF
 SG_ HVLM_HV_Abstellzeit : 0|8@1+ (4,0) [0|1012] "Unit_Minut" Vector__XXX
 SG_ HVLM_Zustand_LED : 12|4@1+ (1,0) [0|15] "" Vector__XXX
 SG_ HVLM_MaxLadezeitDCHV : 16|8@1+ (10,0) [0|2530] "Unit_Minut" Vector__XXX
 SG_ HVLM_MaxStrom_Netz : 24|7@1+ (0.5,0) [0|62.5] "Unit_Amper" Vector__XXX
 SG_ HVLM_LG_Sollmodus : 31|1@1+ (1,0) [0|1] "" Vector__XXX
 SG_ HVLM_FreigabeTankdeckel : 32|2@1+ (1,0) [0|3] "" Vector__XXX
 SG_ HVLM_Stecker_Verriegeln : 34|2@1+ (1,0) [0|3] "" Vector__XXX
 SG_ HVLM_Start_Spannungsmessung_DCLS : 36|2@1+ (1,0) [0|3] ""  BMS_PlugIn
 SG_ HVLM_Taster_Profil_Laden_Anf : 38|2@1+ (1,0) [0|3] "" Vector__XXX
 SG_ HVLM_Taster_Sofort_Laden_Anf : 40|2@1+ (1,0) [0|3] "" Vector__XXX
 SG_ HVLM_FreigabeKlimatisierung : 42|2@1+ (1,0) [0|3] "" Vector__XXX
 SG_ HVLM_Ladetexte : 49|3@1+ (1,0) [0|7] "" Vector__XXX
 SG_ HVLM_IstSpannung_HV : 54|10@1+ (1,0) [0|1021] "Unit_Volt" Vector__XXX

BO_ 1380 LAD_01: 8 Ladegeraet_PAG_PF
 SG_ LAD_01_CHK : 0|8@1+ (1,0) [0|255] ""  BMS_PlugIn
 SG_ LAD_01_BZ : 8|4@1+ (1,0) [0|15] ""  BMS_PlugIn
 SG_ LAD_IstModus : 12|3@1+ (1,0) [0|7] "" Vector__XXX
 SG_ LAD_AC_Istspannung : 15|9@1+ (1,0) [0|509] "Unit_Volt" Vector__XXX
 SG_ LAD_IstSpannung_HV : 24|10@1+ (1,0) [0|1021] "Unit_Volt"  BMS_PlugIn
 SG_ LAD_IstStrom_HV : 34|10@1+ (0.2,-102) [-102|102.2] "Unit_Amper" Vector__XXX
 SG_ LAD_Status_Spgfreiheit : 44|2@1+ (1,0) [0|3] ""  BMS_PlugIn
 SG_ LAD_Temperatur : 48|8@1+ (1,-40) [-40|213] "Unit_DegreCelsi" Vector__XXX
 SG_ LAD_Verlustleistung : 56|8@1+ (20,0) [0|5060] "Unit_Watt" Vector__XXX

BO_ 1662 LAD_02: 8 Ladegeraet_PAG_PF
 SG_ LAD_02_CHK : 0|8@1+ (1,0) [0|255] "" Vector__XXX
 SG_ LAD_02_BZ : 8|4@1+ (1,0) [0|15] "" Vector__XXX
 SG_ LAD_Abregelung_Temperatur : 12|1@1+ (1,0) [0|1] "" Vector__XXX
 SG_ LAD_Abregelung_IU_Ein_Aus : 13|1@1+ (1,0) [0|1] "" Vector__XXX
 SG_ LAD_Abregelung_BuchseTemp : 14|1@1+ (1,0) [0|1] "" Vector__XXX
 SG_ LAD_Warnlampe_Anf : 15|1@1+ (1,0) [0|1] "" Vector__XXX
 SG_ LAD_MaxLadLeistung_HV : 16|9@1+ (100,0) [0|50900] "Unit_Watt" Vector__XXX
 SG_ LAD_CP_Stromlimit : 25|7@1+ (0.5,0) [0|62.5] "Unit_Amper" Vector__XXX
 SG_ LAD_PRX_Stromlimit : 32|3@1+ (1,0) [0|7] "" Vector__XXX
 SG_ LAD_CP_Erkennung : 35|1@1+ (1,0) [0|1] "" Vector__XXX
 SG_ LAD_Stecker_Verriegelt : 36|1@1+ (1,0) [0|1] "" Vector__XXX
 SG_ LAD_Stecker_Gesteckt : 37|1@1+ (1,0) [0|1] "" Vector__XXX
 SG_ LAD_Kuehlbedarf : 38|2@1+ (1,0) [0|3] ""  BMS_PlugIn
 SG_ LAD_MaxLadLeistung_HV_Offset : 57|2@1+ (1,0) [0|3] "" Vector__XXX
 SG_ LAD_Fehlerstatus : 59|3@1+ (1,0) [0|7] "" Vector__XXX
 SG_ LAD_Warnzustand : 62|1@1+ (1,0) [0|1] "" Vector__XXX
 SG_ LAD_Fehlerzustand : 63|1@1+ (1,0) [0|1] "" Vector__XXX

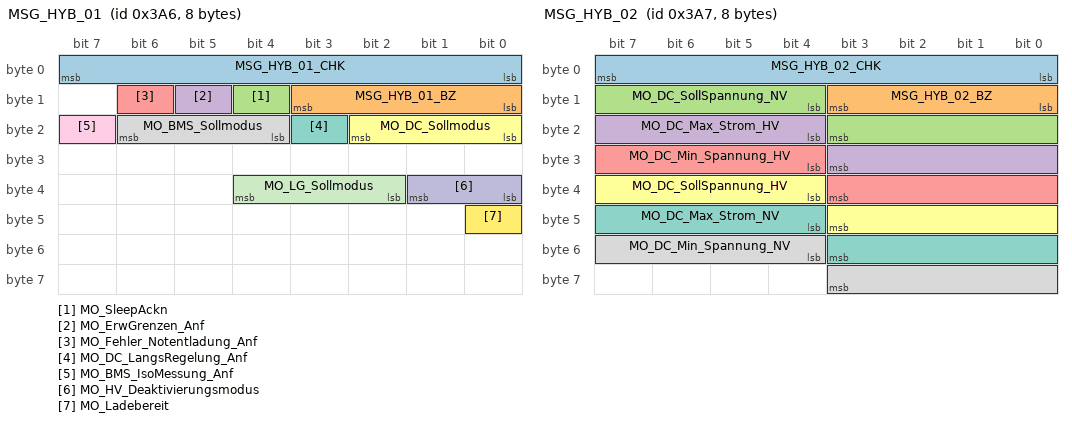
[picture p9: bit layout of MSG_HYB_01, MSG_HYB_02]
BO_ 934 MSG_HYB_01: 8 Motor_MED17_SIMOS8_PlugIn_PAG_PF
 SG_ MSG_HYB_01_CHK : 0|8@1+ (1,0) [0|255] ""  BMS_PlugIn,CCU_VW526,Ladegeraet_PAG_PF,LEH_PlugIn
 SG_ MSG_HYB_01_BZ : 8|4@1+ (1,0) [0|15] ""  BMS_PlugIn,CCU_VW526,Ladegeraet_PAG_PF,LEH_PlugIn
 SG_ MO_SleepAckn : 12|1@1+ (1,0) [0|1] ""  CCU_VW526,LEH_PlugIn
 SG_ MO_ErwGrenzen_Anf : 13|1@1+ (1,0) [0|1] ""  BMS_PlugIn,LEH_PlugIn
 SG_ MO_Fehler_Notentladung_Anf : 14|1@1+ (1,0) [0|1] ""  BMS_PlugIn,Ladegeraet_PAG_PF,LEH_PlugIn
 SG_ MO_DC_Sollmodus : 16|3@1+ (1,0) [0|7] ""  LEH_PlugIn
 SG_ MO_DC_LangsRegelung_Anf : 19|1@1+ (1,0) [0|1] ""  LEH_PlugIn
 SG_ MO_BMS_Sollmodus : 20|3@1+ (1,0) [0|7] ""  BMS_PlugIn
 SG_ MO_BMS_IsoMessung_Anf : 23|1@1+ (1,0) [0|1] ""  BMS_PlugIn
 SG_ MO_HV_Deaktivierungsmodus : 32|2@1+ (1,0) [0|3] "" Vector__XXX
 SG_ MO_LG_Sollmodus : 34|3@1+ (1,0) [0|7] ""  Ladegeraet_PAG_PF
 SG_ MO_Ladebereit : 40|1@1+ (1,0) [0|1] ""  Ladegeraet_PAG_PF

BO_ 935 MSG_HYB_02: 8 Motor_MED17_SIMOS8_PlugIn_PAG_PF
 SG_ MSG_HYB_02_CHK : 0|8@1+ (1,0) [0|255] ""  LEH_PlugIn
 SG_ MSG_HYB_02_BZ : 8|4@1+ (1,0) [0|15] ""  LEH_PlugIn
 SG_ MO_DC_SollSpannung_NV : 12|8@1+ (0.1,0) [0|25.4] "Unit_Volt"  LEH_PlugIn
 SG_ MO_DC_Max_Strom_HV : 20|8@1+ (0.2,0) [0|50.8] "Unit_Amper"  LEH_PlugIn
 SG_ MO_DC_Min_Spannung_HV : 28|8@1+ (2,0) [0|508] "Unit_Volt"  LEH_PlugIn
 SG_ MO_DC_SollSpannung_HV : 36|8@1+ (2,0) [0|508] "Unit_Volt"  LEH_PlugIn
 SG_ MO_DC_Max_Strom_NV : 44|8@1+ (2,0) [0|508] "Unit_Amper"  LEH_PlugIn
 SG_ MO_DC_Min_Spannung_NV : 52|8@1+ (0.1,0) [0|25.4] "Unit_Volt"  LEH_PlugIn

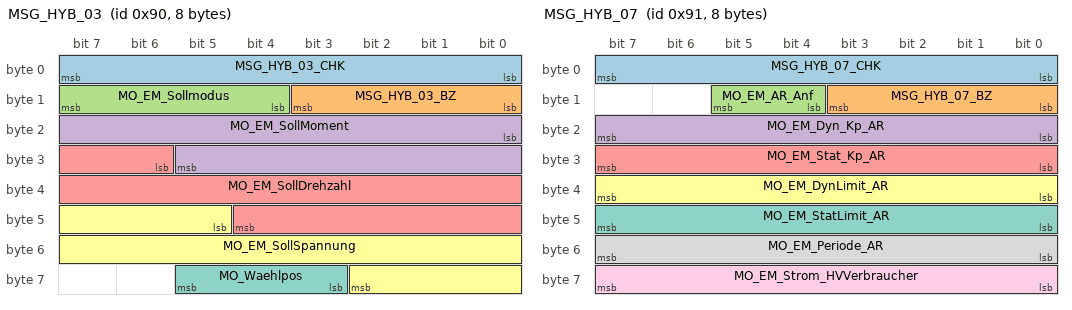
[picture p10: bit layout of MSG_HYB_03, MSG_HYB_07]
BO_ 144 MSG_HYB_03: 8 Motor_MED17_SIMOS8_PlugIn_PAG_PF
 SG_ MSG_HYB_03_CHK : 0|8@1+ (1,0) [0|255] ""  LEH_PlugIn
 SG_ MSG_HYB_03_BZ : 8|4@1+ (1,0) [0|15] ""  LEH_PlugIn
 SG_ MO_EM_Sollmodus : 12|4@1+ (1,0) [0|15] ""  LEH_PlugIn
 SG_ MO_EM_SollMoment : 16|14@1+ (0.1,-819.1) [-819.1|819.1] "Unit_NewtoMeter"  LEH_PlugIn
 SG_ MO_EM_SollDrehzahl : 30|15@1+ (1,-10000) [-10000|22766] "Unit_MinutInver"  LEH_PlugIn
 SG_ MO_EM_SollSpannung : 45|14@1+ (0.1,0) [0|1638.2] "Unit_Volt"  LEH_PlugIn
 SG_ MO_Waehlpos : 59|3@1+ (1,0) [0|7] "" Vector__XXX

BO_ 145 MSG_HYB_07: 8 Motor_MED17_SIMOS8_PlugIn_PAG_PF
 SG_ MSG_HYB_07_CHK : 0|8@1+ (1,0) [0|255] ""  LEH_PlugIn
 SG_ MSG_HYB_07_BZ : 8|4@1+ (1,0) [0|15] ""  LEH_PlugIn
 SG_ MO_EM_AR_Anf : 12|2@1+ (1,0) [0|3] ""  LEH_PlugIn
 SG_ MO_EM_Dyn_Kp_AR : 16|8@1+ (0.03125,0) [0|7.9375] "Unit_NewtoMeterPerRPM"  LEH_PlugIn
 SG_ MO_EM_Stat_Kp_AR : 24|8@1+ (0.03125,0) [0|7.9375] "Unit_NewtoMeterPerRPM"  LEH_PlugIn
 SG_ MO_EM_DynLimit_AR : 32|8@1+ (1,0) [0|254] "Unit_NewtoMeter"  LEH_PlugIn
 SG_ MO_EM_StatLimit_AR : 40|8@1+ (1,0) [0|254] "Unit_NewtoMeter"  LEH_PlugIn
 SG_ MO_EM_Periode_AR : 48|8@1+ (0.001953125,0) [0|0.49609375] "Unit_Secon"  LEH_PlugIn
 SG_ MO_EM_Strom_HVVerbraucher : 56|8@1+ (0.5,-63.5) [-63.5|63.5] "Unit_Amper"  LEH_PlugIn

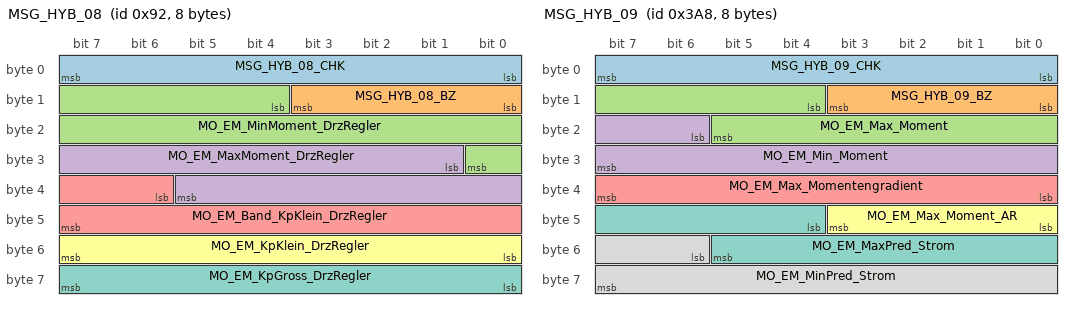
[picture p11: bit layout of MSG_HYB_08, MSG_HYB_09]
BO_ 146 MSG_HYB_08: 8 Motor_MED17_SIMOS8_PlugIn_PAG_PF
 SG_ MSG_HYB_08_CHK : 0|8@1+ (1,0) [0|255] ""  LEH_PlugIn
 SG_ MSG_HYB_08_BZ : 8|4@1+ (1,0) [0|15] ""  LEH_PlugIn
 SG_ MO_EM_MinMoment_DrzRegler : 12|13@1+ (0.2,-819) [-819|818.8] "Unit_NewtoMeter"  LEH_PlugIn
 SG_ MO_EM_MaxMoment_DrzRegler : 25|13@1+ (0.2,-819) [-819|818.8] "Unit_NewtoMeter"  LEH_PlugIn
 SG_ MO_EM_Band_KpKlein_DrzRegler : 38|10@1+ (1,0) [0|1022] "Unit_MinutInver"  LEH_PlugIn
 SG_ MO_EM_KpKlein_DrzRegler : 48|8@1+ (0.04,0) [0|10] "Unit_None"  LEH_PlugIn
 SG_ MO_EM_KpGross_DrzRegler : 56|8@1+ (0.04,0) [0|10] "Unit_None"  LEH_PlugIn

BO_ 936 MSG_HYB_09: 8 Motor_MED17_SIMOS8_PlugIn_PAG_PF
 SG_ MSG_HYB_09_CHK : 0|8@1+ (1,0) [0|255] ""  LEH_PlugIn
 SG_ MSG_HYB_09_BZ : 8|4@1+ (1,0) [0|15] ""  LEH_PlugIn
 SG_ MO_EM_Max_Moment : 12|10@1+ (1,-511) [-511|511] "Unit_NewtoMeter"  LEH_PlugIn
 SG_ MO_EM_Min_Moment : 22|10@1+ (1,-511) [-511|511] "Unit_NewtoMeter"  LEH_PlugIn
 SG_ MO_EM_Max_Momentengradient : 32|8@1+ (100,0) [0|25400] "Unit_NewtoMeterPerSecon"  LEH_PlugIn
 SG_ MO_EM_Max_Moment_AR : 40|4@1+ (15,0) [0|225] "Unit_NewtoMeter"  LEH_PlugIn
 SG_ MO_EM_MaxPred_Strom : 44|10@1+ (1,-511) [-511|511] "Unit_Amper" Vector__XXX
 SG_ MO_EM_MinPred_Strom : 54|10@1+ (1,-511) [-511|511] "Unit_Amper" Vector__XXX

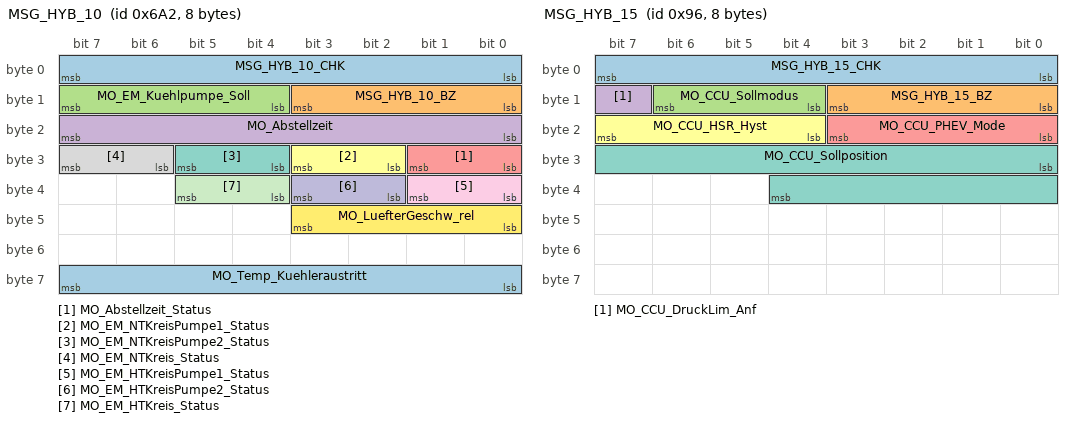
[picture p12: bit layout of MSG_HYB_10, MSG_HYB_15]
BO_ 1698 MSG_HYB_10: 8 Motor_MED17_SIMOS8_PlugIn_PAG_PF
 SG_ MSG_HYB_10_CHK : 0|8@1+ (1,0) [0|255] ""  BMS_PlugIn,LEH_PlugIn
 SG_ MSG_HYB_10_BZ : 8|4@1+ (1,0) [0|15] ""  BMS_PlugIn,LEH_PlugIn
 SG_ MO_EM_Kuehlpumpe_Soll : 12|4@1+ (10,0) [0|100] "Unit_PerCent" Vector__XXX
 SG_ MO_Abstellzeit : 16|8@1+ (8,0) [0|2024] "Unit_Minut"  BMS_PlugIn,LEH_PlugIn
 SG_ MO_Abstellzeit_Status : 24|2@1+ (1,0) [0|3] ""  BMS_PlugIn,LEH_PlugIn
 SG_ MO_EM_NTKreisPumpe1_Status : 26|2@1+ (1,0) [0|3] ""  LEH_PlugIn
 SG_ MO_EM_NTKreisPumpe2_Status : 28|2@1+ (1,0) [0|3] ""  LEH_PlugIn
 SG_ MO_EM_NTKreis_Status : 30|2@1+ (1,0) [0|3] ""  LEH_PlugIn
 SG_ MO_EM_HTKreisPumpe1_Status : 32|2@1+ (1,0) [0|3] ""  LEH_PlugIn
 SG_ MO_EM_HTKreisPumpe2_Status : 34|2@1+ (1,0) [0|3] ""  LEH_PlugIn
 SG_ MO_EM_HTKreis_Status : 36|2@1+ (1,0) [0|3] ""  LEH_PlugIn
 SG_ MO_LuefterGeschw_rel : 40|4@1+ (10,0) [0|100] "Unit_PerCent"  LEH_PlugIn
 SG_ MO_Temp_Kuehleraustritt : 56|8@1+ (0.75,-48) [-47.25|141.75] "Unit_DegreCelsi"  LEH_PlugIn

BO_ 150 MSG_HYB_15: 8 Motor_MED17_SIMOS8_PlugIn_PAG_PF
 SG_ MSG_HYB_15_CHK : 0|8@1+ (1,0) [0|255] ""  CCU_VW526
 SG_ MSG_HYB_15_BZ : 8|4@1+ (1,0) [0|15] ""  CCU_VW526
 SG_ MO_CCU_Sollmodus : 12|3@1+ (1,0) [0|7] ""  CCU_VW526
 SG_ MO_CCU_DruckLim_Anf : 15|1@1+ (1,0) [0|1] ""  CCU_VW526
 SG_ MO_CCU_PHEV_Mode : 16|4@1+ (1,0) [0|15] ""  CCU_VW526
 SG_ MO_CCU_HSR_Hyst : 20|4@1+ (1,0) [0|15] "Unit_DegreOfArc"  CCU_VW526
 SG_ MO_CCU_Sollposition : 24|13@1+ (1,0) [0|6945] "Unit_DegreOfArc"  CCU_VW526

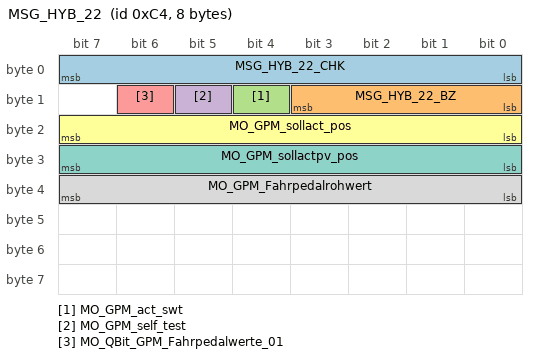
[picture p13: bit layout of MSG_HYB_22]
BO_ 196 MSG_HYB_22: 8 Motor_MED17_SIMOS8_PlugIn_PAG_PF
 SG_ MSG_HYB_22_CHK : 0|8@1+ (1,0) [0|255] ""  GPM_PAG_PF
 SG_ MSG_HYB_22_BZ : 8|4@1+ (1,0) [0|15] ""  GPM_PAG_PF
 SG_ MO_GPM_act_swt : 12|1@1+ (1,0) [0|1] ""  GPM_PAG_PF
 SG_ MO_GPM_self_test : 13|1@1+ (1,0) [0|1] ""  GPM_PAG_PF
 SG_ MO_QBit_GPM_Fahrpedalwerte_01 : 14|1@1+ (1,0) [0|1] ""  GPM_PAG_PF
 SG_ MO_GPM_sollact_pos : 16|8@1+ (1,0) [0|100] "Unit_PerCent"  GPM_PAG_PF
 SG_ MO_GPM_sollactpv_pos : 24|8@1+ (1,0) [0|100] "Unit_PerCent"  GPM_PAG_PF
 SG_ MO_GPM_Fahrpedalrohwert : 32|8@1+ (0.4,0) [0|101.6] "Unit_PerCent"  GPM_PAG_PF

CM_ "PAG_Plattform_CAN_Hybrid_0.0.1 Generated by BUSNETNG 8.4.2";
CM_ BU_ CCU_VW526 "Colorado NF";
CM_ BU_ LEH_PlugIn "Leistungselektronik Hybrid
Antriebs-CAN:	LEH_Hybrid
Hybrid-SubCAN:	DC_Hybrid + EM_Hybrid

Das Steuergerät fasst die beiden Komponenten DC/DC-Wandler (DC) und Elektromotor (EM) zusammen. Zur größeren Transparenz der Sender-Empfänger Beziehungen auf dem";
CM_ BU_ Motor_MED17_SIMOS8_PlugIn_PAG_PF "PlugIn Motoren";
CM_ SG_ 151 BMS_HYB_02_CHK "Berechnung siehe Konzern-Lastenheft A-CAN V4.2a
Checksummenendwert = 0x00";
CM_ SG_ 151 BMS_HYB_02_BZ "freilaufender Botschaftszähler";
CM_ SG_ 151 BMS_IstStrom "actual current of the battery / Momentanwert: Batteriestrom
Stromrichtung: ein Ladestrom wird mit positiven, ein Entladestrom mit negativen Werten angegeben";
CM_ SG_ 151 BMS_IstSpannung "actual voltage of the battery / Momentanwert: Batteriespannung";
CM_ SG_ 151 BMS_IstModus "actual state of the battery / momentaner Status der Batterie
0: Standby; Kommunikation aktiv
1: Hauptschütze geschlossen / HV-Netz aktiviert / normaler Fahrbetrieb
2: Hauptschütze geschlossen / Balancing-Modus aktiviert
3: externes Laden über Ladegerä";
CM_ SG_ 151 BMS_SleepInd "Die Sleep-Bereitschaft des BMS wird nach Rücknahme Klemme 15 durch Setzen dieses Bits signalisiert";
CM_ SG_ 151 BMS_IsoMessungAktiv "Isolationsmessung
0: inaktiv
1: aktiv";
CM_ SG_ 151 BMS_Init_abgeschlossen "Status BMS:
0: BMS befindet sich in Init- oder Nachlaufphase; CAN-Signalwerte entsprechen den Init-Werten (während Init-Phase), den physikalischen Werten (während Nachlauf-Phase)
1: BMS befindet sich im aktiven Zustand außerhalb Init- oder Nachlaufphase";
CM_ SG_ 151 BMS_Status_Spgfreiheit "0=Init (ohne Funktion)
1=BMS Zwischenkreis spannungsfrei (U_Zwkr < 20V)
2=BMS Zwischenkreis nicht spannungsfrei (U_Zwkr >/= 25V, Hysterese)
3=Fehler (z.B. Fehler in der Sensorik)";
CM_ SG_ 151 BMS_Fehler_Notabschaltung_Crash "Fehler: Sicherheitskritischer Fehler (Crash-Erkennung)
Batterieschütze sind bereits geöffnet / werden sofort geöffnet
Signal wird direkt vom EMS gelesen und initiiert einen AKS des PWR und eine aktive Entladung des Zwischenkreises";
CM_ SG_ 151 BMS_Fehler_Notabschaltung_Pilot "Fehler: Sicherheitskritischer Fehler (Abriss Pilotlinie / Deckel offen)
Batterieschütze sind bereits geöffnet / werden sofort geöffnet
Signal wird direkt vom EMS gelesen und initiiert einen AKS des PWR und eine aktive Entladung des Zwischenkreises";
CM_ SG_ 151 BMS_Fehler_HVBattAbschaltung_Anf "Fehler: Fehlerzustand, erfordert das Öffnen der Batterieschütze
interner Batteriefehler; Vorankündigung eines bevorstehenden Öffnens der Batterieschütze durch das BMS";
CM_ SG_ 151 BMS_Fehler_HVBattAbschaltung "Fehler: Fehlerzustand, erfordert das Öffnen der Batterieschütze
interner Batteriefehler, Batterieschütze ohne Vorankündigung durch das BMS geöffnet";
CM_ SG_ 151 BMS_Fehler_HS_verschweisst "Fehler: Hauptschütz(e) verschweißt";
CM_ SG_ 151 BMS_Fehler_HS_offen "Fehler: Hauptschütze schließen nicht / HV-Batterie nicht verfügbar
kann HV-Netz nicht aktivieren (z.B. defekte Schütze, Sicherung, Vorlade-Fehler)";
CM_ SG_ 151 BMS_Fehler_Leistungsred "Fehler: Leistungsfähigkeit der Batterie ist eingeschränkt (z.B. aufgrund des Ausfalls von Sensoren oder des Lüfters)";
CM_ SG_ 151 BMS_Fehler_Isolation "Fehler: Isolationsüberwachung";
CM_ SG_ 151 BMS_Fehler_Kaltstartleistung "Signalisiert, dass die Leistungsreserve der HV-Batterie für Kaltstart erschöpft ist, Indiz für Aktivierung Fremdladung";
CM_ SG_ 151 BMS_Fehler_Pilot "Signalisiert den Status der Pilotlinie BMS.";
CM_ SG_ 151 BMS_Fehler_Sicherung "Signalisiert den Zustand der im Service-Plug integrierten Hochvolt-Sicherung im BMS";
CM_ SG_ 151 BMS_Status_ServiceDisconnect "Status des Service Disconnect, ob dieser gesteckt oder gezogen ist.
Abhängigkeiten zu anderen Signalen: BMS_Fehler_Sicherung und BMS_Fehler_Pilot";
CM_ SG_ 151 BMS_Status_Spannungsfreiheit "Status der Spannungsfreiheit des BMS im Zwischenkreis. 
Abhängigkeiten zu anderen Signalen: BMS_Spannung_Zwkr";
CM_ SG_ 151 BMS_Notfallkuehlung "Anforderung der maximalen Kühlleistung im Notfall.";
CM_ SG_ 938 BMS_HYB_03_CHK "Berechnung siehe Konzern-Lastenheft A-CAN V4.2a
Checksummenendwert = 0x00";
CM_ SG_ 938 BMS_HYB_03_BZ "freilaufender Botschaftszähler";
CM_ SG_ 938 BMS_MaxPred_LadeStrom "dynamic el. limit, max. current (charge) for the specified time (~10s), and the voltage limit (only for prediction)  / rechnerischer Wert: quasistationärer, für eine Dauer von ~10s garantierter maximaler Ladestrom,
EV / PlugIn:
externes Laden (BMS_IstMo";
CM_ SG_ 938 BMS_MaxPred_EntladeStrom "dynamic el. limit, max. current (discharge) for the specified time (~10s): and the voltage limit (only for prediction) / rechnerischer Wert: quasistationärer, für eine Dauer von ~10s garantierter maximaler Entladestrom";
CM_ SG_ 938 BMS_MinPred_LadeSpannung "static el. limit, min. battery voltage (~10s) during current MaxPred_LadeStrom resp. iChPredMax / rechnerischer Wert: minimales, für eine Dauer von ~10s garantiertes Spannungsniveau, das unter Belastung mit MaxPred_LadeStrom bzw. iChPredMax nicht untersch";
CM_ SG_ 938 BMS_MinPred_EntladeSpannung "static el. limit, min. battery voltage (~10s) during current MaxPred_EntladeStrom resp iDisChPredMax / rechnerischer Wert: minimales, für eine Dauer von 10s garantiertes Spannungsniveau, das unter Belastung mit MaxPred_EntladeStrom bzw. iDisChPredMax nich";
CM_ SG_ 938 BMS_BattLuefterGeschw_rel "Relativwert der Batterielüfter-Ansteuerung bezogen auf Maximalwert";
CM_ SG_ 938 BMS_SOC "State of Charge / aktueller Ladezustand der Batterie";
CM_ SG_ 292 BMS_HYB_04_CHK "Berechnung siehe Konzern-Lastenheft A-CAN V4.2a
Checksummenendwert = 0x00";
CM_ SG_ 292 BMS_HYB_04_BZ "freilaufender Botschaftszähler";
CM_ SG_ 292 BMS_MinDyn_LadeSpannung "min. voltage during charge with current MaxDyn_LadeStrom resp. iChMax / rechnerischer Wert: minimales, für eine Dauer von ~1s garantiertes Spannungsniveau, das unter Belastung mit MaxDyn_LadeStrom bzw. iChMax nicht unterschritten werden würde
";
CM_ SG_ 292 BMS_MinDyn_EntladeSpannung "min. voltage during discharge with current MaxDyn_EntladeStrom resp. iDisChMax / rechnerischer Wert: minimales, für eine Dauer von ~1s garantiertes Spannungsniveau, das unter Belastung mit MaxDyn_EntladeStrom bzw. iDisChMax nicht unterschritten werden wür";
CM_ SG_ 292 BMS_MaxDyn_EntladeStrom "max current (discharge)  / maximal zulässiger Entladestrom (zwingend einzuhaltender Grenzwert); Wert ist für eine Dauer von 1s garantiert
";
CM_ SG_ 292 BMS_MaxDyn_LadeStrom "max current (charge) / maximal zulässiger Ladestrom (zwingend einzuhaltender Grenzwert); Wert ist für eine Dauer von 1s garantiert
(Im Balancing-Mode wird über diesen Wert der Ladestrom-Sollwert angegeben)
";
CM_ SG_ 292 BMS_ErwGrenzen_aktiv "die aktuellen Stromgrenzen der HV-Batterie sind zum Start des Verbrennungsmotors aufgeweitet / Bestätigung der Anforderung";
CM_ SG_ 292 BMS_Spannung_ZwKr "Momentanwert: 
Spannung an den Batterie-HV-Anschlüssen";
CM_ BO_ 1699 "MLB";
CM_ SG_ 1699 BMS_HYB_06_CHK "Berechnung siehe Konzern-Lastenheft A-CAN V4.2a
Checksummenendwert = 0x00";
CM_ SG_ 1699 BMS_HYB_06_BZ "freilaufender Botschaftszähler";
CM_ SG_ 1699 BMS_Max_LadeSpannung "max. voltage / maximal erlaubte Batteriespannung (zwingend einzuhaltender Grenzwert)";
CM_ SG_ 1699 BMS_Min_EntladeSpannung "min. voltage / minimal erlaubte Batteriespannung (zwingend einzuhaltender Grenzwert)";
CM_ SG_ 1699 BMS_Temperatur "battery temperature / Momentanwert: Temperatur der Traktionsbatterie";
CM_ SG_ 1699 BMS_Temperatur_Ansaugluft "Temperature of inlet air / Momentanwert: Ansauglufttemperatur der Batteriekühlung";
CM_ SG_ 1699 BMS_Ausgleichsladung_Anf "BMS wünscht eine Ausgleichsladung
Flag derzeit ungenutzt, da BalancingModus im Detail noch nicht geklärt.";
CM_ SG_ 1699 BMS_Umluftklappe_Anf "BMS fordert bei Climatronic die Öffnung der Umluftklappe an; Signal muss vom MSG auf den A-CAN gegated werden";
CM_ SG_ 1699 BMS_OBD_Lampe_Anf "Anforderung MIL (MalfunctionIndicationLamp) von BMS (Motorsteuergerät reicht diese Info an Kombi weiter).";
CM_ SG_ 1699 BMS_Warnlampe_Anf "Anforderung der gelben Hybrid-Warnlampe im Kombi";
CM_ SG_ 1699 BMS_Fehlerlampe_Anf "Anforderung der roten Hybrid-Warnlampe im Kombi";
CM_ SG_ 1699 BMS_Balancing_Anf "Mitteilung des BMS an den Lademanager/(Gateway) in welchem Balancing Status sich das BMS befindet.";
CM_ SG_ 1723 BMS_Energieinhalt "aktuell nutzbarer Energieinhalt der HV-Batterie
(bezogen auf ein definiertes mittleres Belastungsprofil)";
CM_ SG_ 1723 BMS_Kapazitaet "Gesamtenergiekapazitaet der HV-Batterie unter Berücksichtigung der Alterung";
CM_ SG_ 1723 BMS_Temperierung_Anf "Temperierungsbedarf der HV-Batterie";
CM_ SG_ 1723 BMS_min_Grenz_SOC "unterer Grenz SOC - Betriebsstrategie";
CM_ SG_ 1723 BMS_max_Grenz_SOC "oberer Grenz SOC - Betriebsstrategie";
CM_ SG_ 1723 BMS_MaxEnergieinhalt "maximaler nutzbarer Energieinhalt der HV-Batterie (bezogen auf Last KBI_RWDS_Lastprofil bei SOC=100%)
Abhängig von KBI_RWDS_Lastprofil";
CM_ SG_ 1723 BMS_Zeitbedarf_Balancing "Enthält die geschätzte Restzeitdauer um Ladungsdifferenzen zwischen den Zellen auszugleichen.";
CM_ SG_ 1161 BMS_Status_DCLS "Status der Spannungsüberwachung an der DC-Ladeschnittstelle";
CM_ SG_ 1161 BMS_DCLS_Spannung "DC-Spannung der Ladesäule.
Messung zwischen den DC HV-Leitungen.";
CM_ SG_ 1161 BMS_HVBatt_Perf_Ind "Leistungsindikation (Leistungsabgabe).
Prozentualer Wert der unter Berücksichtigung der Belastungshistorie und des Betriebspunktes die über die Dauerleistung der Batterie hinausgehende Leistungsreserve angibt (z. B. für Überholvorgänge).";
CM_ SG_ 1161 BMS_SOC_HiRes "State of Charge / aktueller Ladezustand der Batterie (höhere Auflösung)";
CM_ SG_ 1161 BMS_HV_Deaktivierungsmodus "Das Signal beschreibt ob das BMS mittels VAS-Tester deaktiviert wurde. In diesem Fall ist kein Zuschalten der Schütze mehr möglich.";
CM_ SG_ 1161 BMS_Anf_Mo_Luefter "Anforderung des Motorluefters bie Kuehlung ueber den NT-Kuehler";
CM_ BO_ 1666 "CCP in Serie mit 11Bit - Empfangskanal";
CM_ BO_ 127 "MLB";
CM_ SG_ 127 CCU_HYB_01_CHK "Berechnung siehe Konzern-Lastenheft A-CAN V4.2a
Checksummenendwert = 0x00";
CM_ SG_ 127 CCU_HYB_01_BZ "freilaufender Botschaftszaehler";
CM_ SG_ 127 CCU_Strom_momentbildend "Drehmomentbildender Strom Aktuator";
CM_ SG_ 127 CCU_IstWinkelGeschw "Winkelgeschwindigkeit Aktuator";
CM_ SG_ 127 CCU_Fehler_HW "HW Fehler im Aktuator festgestellt";
CM_ SG_ 127 CCU_Fehler_mechanisch "Systemdruckniveau Aktuator in Nullposition > erlaubter Schwelle";
CM_ SG_ 127 CCU_Fehler_CAN "CAN Fehler Aktuator festgestellt";
CM_ SG_ 127 CCU_Fehler_Unterspannung "Unterspannung Aktuator festgestellt";
CM_ SG_ 127 CCU_Warnung_Temperatur "Erhoehte CPU Temperatur bzw. erhoehtes Motor Stromintegral Aktuator festgestellt";
CM_ SG_ 127 CCU_Fehler_Temperatur "Kritische CPU Temperatur bzw. kritisches Motor Stromintegral Aktuator festgestellt";
CM_ SG_ 127 CCU_SleepInd "Die Sleep-Bereitschaft wird nach Rücknahme von Klemme 15 durch Setzen dieses Bits signalisiert";
CM_ SG_ 127 CCU_IstPosition "Position Aktuator";
CM_ SG_ 127 CCU_Istmodus "Modus Aktuator
0: Init Mode
1: Secure_Mode 
2: Operation_Mode
3: RemovingAir_Mode
4: Filling_Mode
5...6: reserve
7: Initialisierung
Anmerkung: bei PL71 initialisiert die CCU noch mit '0'";
CM_ SG_ 127 CCU_IstDruck "Systemdruck Aktuator";
CM_ BO_ 1715 "MLB";
CM_ SG_ 1715 CCU_HYB_02_CHK "Berechnung siehe Konzern-Lastenheft A-CAN V4.2a
Checksummenendwert = 0x00";
CM_ SG_ 1715 CCU_HYB_02_BZ "freilaufender Botschaftszaehler";
CM_ SG_ 1715 CCU_Medium "Verwendetes Medium Aktuator
4: Mineraloel_Pentosin
7: Bremsfluessigkeit";
CM_ SG_ 1715 CCU_HW_Version "Hardware Stand Aktuator
0: A0_Muster
1: A1_Muster
2: A2_Muster
3: B0_Muster
4: B1_Muster
5: B2_Muster
6: B3_Muster
7: C0_Muster
8: C1_Muster
9: C2_Muster
10: Nullserie
255: Zwischenstand";
CM_ SG_ 1715 CCU_SW_Version "Software Stand Aktuator
105: v105
106: v106
107: v107
108: v108
109: v109";
CM_ SG_ 1715 CCU_Seriennummer "Laufende Nummer Aktuator";
CM_ SG_ 1715 CCU_Teilenummer "OEM spezifische Teilenummer Aktuator";
CM_ BO_ 156 "MLB
Berechnung siehe Konzern-Lastenheft A-CAN V4.2a
Checksummenendwert = 0x00";
CM_ SG_ 156 DC_HYB_01_CHK "Berechnung siehe Konzern-Lastenheft A-CAN V4.2a
Checksummenendwert = 0x00";
CM_ SG_ 156 DC_HYB_01_BZ "freilaufender Botschaftszähler";
CM_ SG_ 156 DC_IstSpannung_HV "Momentanwert:  Hochspannung am DC/DC Wandler";
CM_ SG_ 156 DC_IstStrom_HV "Momentanwert:  Strom aus dem Traktionsnetz in den DC/DC Wandler";
CM_ SG_ 156 DC_IstModus "aktuelle Betriebsart des DC/DC Wandlers;
0: Standby; Kommunikation aktiv
1: Tiefsetzen_1 (HV --> BN 14,4V)
    Sollwertvorgabe projektabhängig vom BSG/BCM über Lin/BSS oder vom MSG über 'MO_DC_SollSpannung_NV' bzw. 'MY2_DC_uSetPLV'
    (PQ35/PL71: Sol";
CM_ SG_ 156 DC_LangsRegelung_aktiv "aktueller Regelmode des DC/DC-Wandlers:
1: langsame Regelung
0: normale Regelung";
CM_ SG_ 156 DC_SleepInd "Die Sleep-Bereitschaft wird nach Rücknahme von Klemme 15 durch Setzen dieses Bits signalisiert";
CM_ SG_ 156 DC_Fehler_intern "Fehler: DC/DC-Wandler ist aufgrund eines internen Hardware-Fehlers abgeschaltet";
CM_ SG_ 156 DC_Fehler_Leistungsred "Fehler: eingeschränkte Leistungsfähigkeit des DC/DC-Wandlers aufgrund eines internen Fehlers";
CM_ SG_ 156 DC_Fehler_Spannung "Abschaltung aufgrund Unter-/Überspannung auf der Ein- / Ausgangsseite";
CM_ SG_ 156 DC_Verbrauch "Energieverbrauch vom DCDC für Versorgung 12V-Bordnetz inkl. seines eigenen Wirkungsgrads (bspw.: HV_Strom*HV_Spannung*t)";
CM_ SG_ 156 DC_Verbrauch_Ueberlauf "Überlauf-Bit für das Signal DC_Verbrauch";
CM_ BO_ 943 "MLB
Berechnung siehe Konzern-Lastenheft A-CAN V4.2a
Checksummenendwert = 0x00";
CM_ SG_ 943 DC_HYB_02_CHK "Berechnung siehe Konzern-Lastenheft A-CAN V4.2a
Checksummenendwert = 0x00";
CM_ SG_ 943 DC_HYB_02_BZ "freilaufender Botschaftszähler";
CM_ SG_ 943 DC_IstSpannung_NV "Momentanwert: Bordnetzspannung am DC/DC Wandler";
CM_ SG_ 943 DC_IstStrom_NV "Momentanwert: Strom vom DC/DC in das Bordnetz
Tiefsetzen - positiv
Hochsetzen - negativ";
CM_ SG_ 943 DC_IdentifikationsNr "Code Nr. zur Kennzeichnung der Leistungsfähigkeit der Komponente";
CM_ SG_ 943 DC_Temperatur "Momentanwert: Temperatur des DC/DC Wandlers";
CM_ SG_ 943 DC_Auslastungsgrad "Momentanwert: Auslastung DC/DC (DFM Signal), entspricht I_akt / I_max";
CM_ SG_ 943 DC_Abregelung_StromLim_HV "Abregelung aufgrund Überschreitung der Strombegrenzung auf der Hochvoltseite (Tiefsetzbetrieb)
(Signal wird in PQ35/PL71 nicht bedient)";
CM_ SG_ 943 DC_Abregelung_StromLim_NV "Abregelung aufgrund Überschreitung der Strombegrenzung auf der Bordnetzseite (Hochsetzbetrieb)
(Signal wird in PQ35/PL71 nicht bedient)";
CM_ SG_ 943 DC_Abregelung_SpannungLim_HV "Abregelung aufgrund Unterschreitung der Spannungsbegrenzung auf der Hochvoltseite (Tiefsetzbetrieb)
(Signal wird in PQ35/PL71 nicht bedient)";
CM_ SG_ 943 DC_Abregelung_SpannungLim_NV "Abregelung aufgrund Unterschreitung der Spannungsbegrenzung auf der Bordnetzseite (Hochsetzbetrieb)
(Signal wird in PQ35/PL71 nicht bedient)";
CM_ SG_ 943 DC_Abregelung_Temperatur "Abregelung aufgrund Übertemperatur im Leistungsteil (Hochtemperatur-Abregelung)";
CM_ SG_ 152 EM_HYB_02_CHK "Berechnung siehe Konzern-Lastenheft A-CAN V4.2a
Checksummenendwert = 0x00";
CM_ SG_ 152 EM_HYB_02_BZ "freilaufender Botschaftszähler";
CM_ SG_ 152 EM_IstMoment "Momentanwert: E-Maschinen Moment";
CM_ SG_ 152 EM_IstMoment_ohneAR "Momentanwert: E-Maschinen Moment ohne Anteil der Ruckeldämpfung";
CM_ SG_ 152 EM_IstDrehzahl "Momentanwert: E-Maschinen Drehzahl";
CM_ SG_ 152 EM_Status_Spannungsfreiheit "Status der Spannungsfreiheit der LE im Zwischenkreis.
Abhängigkeiten zu anderen Signalen: EM_Spannung_Zwkr";
CM_ SG_ 152 EM_AR_aktiv "Ruckeldämpfer aktiv";
CM_ SG_ 152 EM_Fehler_Notabschaltung_HVIL "Fehler: Sicherheitskritischer Fehler Pilotkontakt / Deckel offen";
CM_ SG_ 939 EM_HYB_03_CHK "Berechnung siehe Konzern-Lastenheft A-CAN V4.2a
Checksummenendwert = 0x00";
CM_ SG_ 939 EM_HYB_03_BZ "freilaufender Botschaftszähler";
CM_ SG_ 939 EM_IstSpannung "Momentanwert: HV-Spannung am PWR";
CM_ SG_ 939 EM_IstStrom "Momentanwert: Strom über PWR";
CM_ SG_ 939 EM_Abregelung_Temperatur "Leistungsbegrenzung aufgrund Übertemperatur der E-Maschine / des PWR";
CM_ SG_ 939 EM_Abregelung_MaxSpannung "Begrenzung aufgrund Überschreitung der zulässigen Maximalspannung im HV-Zwischenkreis";
CM_ SG_ 939 EM_Abregelung_MinSpannung "Begrenzung aufgrund Unterschreitung der zulässigen Minimalspannung  im HV-Zwischenkreis";
CM_ SG_ 939 EM_Abregelung_MaxStrom "Begrenzung aufgrund Überschreitung des maximal zulässigen Stroms (motorisch)
aus interner Strombegrenzung (PWR/EM) oder Überwachung des zulässigen Stroms der Traktionsbatterie";
CM_ SG_ 939 EM_Abregelung_MinStrom "Begrenzung aufgrund Überschreitung des maximal zulässigen Stroms (generatorisch)
aus interner Strombegrenzung (PWR/EM) oder Überwachung des zulässigen Stroms der Traktionsbatterie";
CM_ SG_ 939 EM_Abregelung_MaxMoment "Begrenzung aufgrund Überschreitung des maximal zulässigen Moments (motorisch)
aus interner Momentenbegrenzung (PWR/EM) oder externer durch das MSG (Spannungs- oder Drehzahlmodus)";
CM_ SG_ 939 EM_Abregelung_MinMoment "Begrenzung aufgrund Überschreitung des maximal zulässigen Moments (generatorisch)
aus interner Momentenbegrenzung (PWR/EM) oder externer durch das MSG (Spannungs- oder Drehzahlmodus)";
CM_ SG_ 939 EM_AnlernenElMotor_Anf "Diagnoseanforderung von E-Maschine/PWR: Hybrid-Controller schaltet über MO_EM_Sollmodus=6 bzw. MY3_EM_modeReq=6 E-Maschine/PWR aktiv in den Kalibriermodus (Strategie muss sicherstellen, dass kein Moment bei der EM angefordert wird.)";
CM_ SG_ 939 EM_Kuehlpumpe_Status "Interne Diagnose Kühlwasserpumpe Niedertemperaturkreis Leistungselektronik";
CM_ SG_ 939 EM_Verlustleistung "Momentane Verlustleistung Pulswechselrichter und DCDC-Wandler";
CM_ SG_ 939 EM_Freigabe_Verfallsinfo_WFS "WFS";
CM_ SG_ 939 EM_Status_Spgfreiheit "0 = Init (ohne Funktion)
1 = Leistungselektronik HV-Komponenten spannungsfrei (U_Zwkr < 20V)
2 = Leistungselektronik HV_Komponenten nicht spannungsfrei (U_Zwkr >= 20V)
3 = Fehler (z. B. Fehler in der Sensorik)";
CM_ SG_ 940 EM_HYB_04_CHK "Berechnung siehe Konzern-Lastenheft A-CAN V4.2a
Checksummenendwert = 0x00";
CM_ SG_ 940 EM_HYB_04_BZ "freilaufender Botschaftszähler";
CM_ SG_ 940 EM_MaxPred_Moment "rechnerischer Wert: maximales quasistationäres, für eine Dauer von ~10s verfügbares Moment (maximales positives Moment; drehzahlunabhängig; i.A. positiv, daher Max)";
CM_ SG_ 940 EM_MinPred_Moment "rechnerischer Wert: minimales quasistationäres, für eine Dauer von ~10s verfügbares Moment (maximales negatives Moment; drehzahlunabhängig; i.A. negativ, daher Min)";
CM_ SG_ 940 EM_MaxPred_Abknickdrehzahl "rechnerischer Wert: Abknickdrehzahl (für maximales quasistationäres (~10s) motorisches Moment) unter Berücksichtigung der Spannungsvorgaben der Batterie";
CM_ SG_ 940 EM_MinPred_Abknickdrehzahl "rechnerischer Wert: Abknickdrehzahl (für minimales quasistationäres (~10s) generatorisches Moment) unter Berücksichtigung der Spannungsvorgaben der Batterie";
CM_ SG_ 940 EM_Moment_HVVerbraucher "rechnerisch benötigtes Generator-Moment, um den Bedarf der el. Nebenverbraucher incl. Batterieladung abzudecken";
CM_ SG_ 1700 EM_HYB_05_CHK "Berechnung siehe Konzern-Lastenheft A-CAN V4.2a
Checksummenendwert = 0x00";
CM_ SG_ 1700 EM_HYB_05_BZ "freilaufender Botschaftszähler";
CM_ SG_ 1700 EM_OBD_Lampe_Anf "Anforderung MIL (MalfunctionIndicationLamp) von LEH (Motorsteuergerät reicht diese Info an Kombi weiter).";
CM_ SG_ 1700 EM_Warnlampe_Anf "Anforderung der gelben Hybrid-Warnlampe im Kombi";
CM_ SG_ 1700 EM_Fehlerlampe_Anf "Anforderung der roten Hybrid-Warnlampe im Kombi";
CM_ SG_ 1700 EM_Fehler_Pilot "Signalisiert den Status der Pilotlinie in der Leistungselektronik";
CM_ SG_ 1700 EM_Temperatur_ElMotor "temperature of EM / Momentanwert: Temperatur der E-Maschine";
CM_ SG_ 1700 EM_Temperatur_PWR "temperature of inverter / Momentanwert: Temperatur des PWR";
CM_ SG_ 1700 EM_Temperatur_Rotor "temperature of rotor / Momentanwert: Temperatur des Rotors";
CM_ SG_ 1700 EM_HTKreis_Umgehung_Freigabe "Freigabe zur Umgehung des Kühlkreislaufs der elektr. Maschine (Das Motorsteuergerät 
steuert bei Bedarf ein Ventil zur Umgehung des Kühlkreislaufs der elektr. Maschine an, um zu Beginn eines Fahrzyklus genügend Heizleistung erzeugen zu können.)

(Init ";
CM_ SG_ 153 EM_HYB_06_CHK "Berechnung siehe Konzern-Lastenheft A-CAN V4.2a
Checksummenendwert = 0x00";
CM_ SG_ 153 EM_HYB_06_BZ "freilaufender Botschaftszähler";
CM_ SG_ 153 EM_Istmodus "aktuelle Betriebsart der E-Maschine...
0: Standby; Kommunikation aktiv; aktiver Kurzschluss
1: Momentenreglung
2: Drezahlregeung (interner Regelkreis)
3: Spannungsregelung
4: Drehzahlregelung (externer Regelkreis)
5: interner Inverter Fehler; angefo";
CM_ SG_ 153 EM_HV_betriebsbereit "1: Ready_HV / 1: HV-Netz Spannung im Betriebsbereich";
CM_ SG_ 153 EM_SleepInd "Die Sleep-Bereitschaft wird nach Rücknahme von Klemme 15 durch Setzen dieses Bits signalisiert";
CM_ SG_ 153 EM_ErwGrenzen_aktiv "Die absoluten Momentengrenzen sind für die Durchführung eines VKM-Starts ggf. aufgeweitet";
CM_ SG_ 153 EM_Init_abgeschlossen "Status PWR-SG:
0: PWR-SG befindet sich in Init- oder Nachlaufphase; CAN-Signalwerte entsprechen den Init-Werten (Init), den physikalischen Werten (Nachlauf)
1: PWR-SG befindet sich im aktiven Zustand außerhalb Init oder Nachlauf; CAN-Signalwerte sind ph";
CM_ SG_ 153 EM_Fehler_ElAntriebAbschaltung "Fehler: PWR befindet sich im aktiven Kurzschluss
alle vom EMS gesendeten Max- und Min-Momente und das aktuelle EM-Moment nehmen in diesem Zustand den Wert des für die aktuelle Drehzahl entsprechenden Schleppmoments der E-Maschine an";
CM_ SG_ 153 EM_Fehler_Notabschaltung "Fehler: Leistungselektronik fordert Abschaltung des HV-Netzes wegen eines sicherheitskritischen Fehlers an";
CM_ SG_ 153 EM_Fehler_Leistungsred "Fehler: eingeschränkte Leistungsfähigkeit aufgrund eines internen Fehlers";
CM_ SG_ 153 EM_Fehler_ElAntriebFreilauf "Fehler: EM im Freilauf; Leistungselektronik fordert Begrenzung der maximalen Drehzahl an, um Überspannung im HV-Zwischenkreis zu vermeiden";
CM_ SG_ 153 EM_Max_Moment "maximal darstellbares Moment (maximal motorisch; incl. kurzzeitiger Überlastfähigkeit), unter Berücksichtigung der Leistungsfähigkeit von Batterie, PWR und E-Motor (i.A. positiv, daher Max)";
CM_ SG_ 153 EM_Min_Moment "minimal darstellbares Moment (maximal generatorisch; incl. kurzzeitiger Überlastfähigkeit), unter Berücksichtigung der Leistungsfähigkeit von Batterie, PWR und E-Motor (i.A. negativ, daher Min)";
CM_ SG_ 153 EM_MaxDyn_Moment "rechnerischer Wert: maximales dynamisches, für eine Dauer von ~1s verfügbares E-Maschinenmoment (maximales motorisches Moment; i.A. positiv, daher Max) unter Berücksichtigung von Batterie, PWR und EM Grenzen";
CM_ SG_ 153 EM_MinDyn_Moment "rechnerischer Wert: minimales dynamisches, für eine Dauer von ~1s verfügbares E-Maschinenmoment (maximales generatorisches Moment; i.A. negativ, daher Min) unter Berücksichtigung von Batterie, PWR und EM Grenzen";
CM_ SG_ 81 EM_IstDrehzahl "Momentanwert: E-Maschinen Drehzahl";
CM_ SG_ 195 GPM_01_CHK "Berechnung siehe Konzern-Lastenheft A-CAN V4.2a
Checksummenendwert = 0x00";
CM_ SG_ 195 GPM_01_BZ "freilaufender Botschaftszähler";
CM_ SG_ 195 GPM_State "Status aktives Gaspedal (ersetzt GPM_Fault_state)";
CM_ SG_ 195 GPM_AspAktuatorweg "Aktuelle Aktuatorschaltposition auf Aktuatorweg bezogen";
CM_ SG_ 195 GPM_AspPedalweg "Aktuelle Aktuatorschaltposition auf Pedalweg bezogen";
CM_ SG_ 195 GPM_AktuatorUebertreten "Status Aktuatorposition";
CM_ SG_ 195 GPM_Fehler_mechanisch "Gaspedalaktuator (GPM) meldet intern erkannten mechanischen Fehler (z. B. Blockieren) (Diagnosekonzept analog CCU über Motorsteuerung)";
CM_ SG_ 195 GPM_Fehler_CAN "Gaspedalaktuator (GPM) meldet erkannten CAN Kommunikation-Fehler (z. B. Timeout, BZ, CHK, DLC Fehler) (Diagnosekonzept analog CCU über Motorsteuerung)";
CM_ SG_ 195 GPM_SleepInd "Vorhalt für Weckkonzept Gaspedalaktuator (GPM): Die Sleep-Bereitschaft wird nach Rücknahme von Klemme 15 durch Setzen dieses Bits signalisiert (Konzept analog CCU)";
CM_ SG_ 195 GPM_Fehler_Unterspannung "Gaspedalaktuator (GPM) meldet erkannten Unterspannungs-Fehler (Diagnosekonzept analog CCU über Motorsteuerung)";
CM_ SG_ 195 GPM_Fehler_Temperatur "Gaspedalaktuator (GPM) meldet überkritische Betriebstemperatur (Diagnosekonzept analog CCU über Motorsteuerung)";
CM_ SG_ 195 GPM_Fehler_HW "Gaspedalaktuator (GPM) meldet intern erkannten Hardware Fehler (Diagnosekonzept analog CCU über Motorsteuerung)";
CM_ SG_ 195 GPM_Warnung_Temperatur "Gaspedalaktuator (GPM) meldet kritische Betriebstemperatur (Diagnosekonzept analog CCU über Motorsteuerung)";
CM_ SG_ 1705 GPM_TeileNr_Mux "Signalkommentar: Multiplexor zur Übertragung der Teilenummer

";
CM_ SG_ 1705 GPM_TeileNr_Word_01 "Word (2 Byte) 1 der GPM-Teilenummer in ASCII

";
CM_ SG_ 1705 GPM_TeileNr_Word_02 "Word (2 Byte) 2 der GPM-Teilenummer in ASCII

";
CM_ SG_ 1705 GPM_TeileNr_Word_03 "Word (2 Byte) 3 der GPM-Teilenummer in ASCII";
CM_ SG_ 1705 GPM_TeileNr_Word_04 "Word (2 Byte) 4 der GPM-Teilenummer in ASCII

";
CM_ SG_ 1705 GPM_TeileNr_Word_05 "Word (2 Byte) 5 der GPM-Teilenummer in ASCII

";
CM_ SG_ 1705 GPM_TeileNr_Word_06 "Word (2 Byte) 6 der GPM-Teilenummer in ASCII";
CM_ SG_ 1705 GPM_TeileNr_Word_07 "Word (2 Byte) 7 der GPM-Teilenummer in ASCII

";
CM_ SG_ 1705 GPM_TeileNr_Word_08 "Word (2 Byte) 8 der GPM-Teilenummer in ASCII";
CM_ SG_ 1705 GPM_TeileNr_Word_09 "Word (2 Byte) 9 der GPM-Teilenummer in ASCII

";
CM_ SG_ 1705 GPM_TeileNr_Word_10 "Word (2 Byte) 10 der GPM-Teilenummer in ASCII

";
CM_ SG_ 1705 GPM_TeileNr_Word_11 "Word (2 Byte) 11 der GPM-Teilenummer in ASCII

";
CM_ SG_ 1705 GPM_TeileNr_Word_12 "Word (2 Byte) 12 der GPM-Teilenummer in ASCII

";
CM_ SG_ 1705 GPM_TeileNr_Word_13 "Word (2 Byte) 13 der GPM-Teilenummer in ASCII

";
CM_ SG_ 1705 GPM_TeileNr_Word_14 "Word (2 Byte) 14 der GPM-Teilenummer in ASCII
";
CM_ SG_ 1705 GPM_TeileNr_Word_15 "Word (2 Byte) 15 der GPM-Teilenummer in ASCII


";
CM_ SG_ 1705 GPM_TeileNr_Word_16 "Word (2 Byte) 16 der GPM-Teilenummer in ASCII";
CM_ SG_ 1705 GPM_Seriennummer "GPM_Seriennummer (GPM): Laufende Nummer Aktuator (Konzept analog CCU)";
CM_ SG_ 1705 GPM_HW_Version "Hardware Version Gaspedalaktuator (GPM): Musterstand (Konzept analog CCU)";
CM_ SG_ 1705 GPM_SW_Version "Software Version Gaspedalaktuator (GPM): ausgerüsteter Softwarestand (Konzept analog CCU)";
CM_ SG_ 1382 HVLM_01_CHK "Berechnung siehe Konzern-Lastenheft A-CAN V4.2a
Checksummenendwert = 0x00";
CM_ SG_ 1382 HVLM_Fehler_Ladestecker "Fehler am Ladestecker erkannt";
CM_ SG_ 1382 HVLM_Fehler_Verriegelung "Fehler bei der Steckerverriegelung erkannt";
CM_ SG_ 1382 HVLM_SollStrom_HV_Offset "Das Signal HVLM_SollStrom_HV_Offset dient zur Ergänzung des Signals HVLM_SollStrom_HV und ermöglicht eine Auflösegenauigkeit von 0,1A anstatt 0,2A";
CM_ SG_ 1382 HVLM_IstStrom "Momentaner Ladestrom unabhängig vom Lademodus (AC oder DC)";
CM_ SG_ 1382 HVLM_IstModus_02 "aktueller Modus";
CM_ SG_ 1382 HVLM_Konditionierung_Anf "Anforderung HV-Netz für Batteriekonditionierung (Motorsteuergerät aktiviert HV-Netz).";
CM_ SG_ 1382 HVLM_LadeAnforderung "Mitteilung des Lademanagements an das MSG ob Stecker erkannt wurde, Laden gestartet, ein autonomer Betriebszustand aktiviert, eine Relaxing Phase für die Batterie angefordert werden soll";
CM_ SG_ 1382 HVLM_Stecker_Status "Status der Steckererkennung unabhängig vom Lademodus (AC oder DC)";
CM_ SG_ 1382 HVLM_SollStrom_HV "Sollstrom Ladegerät auf der HV-Seite";
CM_ SG_ 1382 HVLM_MaxSpannung_HV "maximale Ladespannung an das Ladegerät bzw. DC-Ladestation";
CM_ SG_ 1381 HVLM_HV_Abstellzeit "Zeitraum zwischen HV-Deaktiviert und HV-Aktiviert";
CM_ SG_ 1381 HVLM_Zustand_LED "Zustand der Lade-LED im Kombi und Dosenbeleuchtung";
CM_ SG_ 1381 HVLM_MaxLadezeitDCHV "maximale Ladezeit in Minuten für die Ladesäule";
CM_ SG_ 1381 HVLM_MaxStrom_Netz "maximal zulässiger Strom auf Primärseite (AC) des Ladegerätes
Minima aus
Vorgabe z.B. über
- intelligente Kommunikation
- Control Pilot Duty Cycle
- Widerstandskodierung Kabel (Proximity)
- Vorgabe MMI, o.ä.";
CM_ SG_ 1381 HVLM_LG_Sollmodus "Sollmodus AC Ladegerät";
CM_ SG_ 1381 HVLM_FreigabeTankdeckel "Tankdeckelfreigabe";
CM_ SG_ 1381 HVLM_Stecker_Verriegeln "Anforderung Steckerverriegelung";
CM_ SG_ 1381 HVLM_Start_Spannungsmessung_DCLS "Meldung an das BMS, dass an der DC-Ladesäule eine Messspannung aufgeschaltet wird.";
CM_ SG_ 1381 HVLM_Taster_Profil_Laden_Anf "SollZustand der Profil-Laden-Taste; LED an der Ladedose";
CM_ SG_ 1381 HVLM_Taster_Sofort_Laden_Anf "Sollzustand der Sofort-Laden-Taste; LED an der Ladedose";
CM_ SG_ 1381 HVLM_FreigabeKlimatisierung "Klimatisierung freigeben";
CM_ SG_ 1381 HVLM_Ladetexte "Anzeige, ob AC- oder DC-Laden nicht möglich ist";
CM_ SG_ 1381 HVLM_IstSpannung_HV "Ausgangsspannung des Ladegerätes und DC-Spannung der Ladesäule. Messung zwischen den DC HV-Leitungen. ";
CM_ SG_ 1380 LAD_01_CHK "Berechnung siehe Konzern-Lastenheft A-CAN V4.2a
Checksummenendwert = 0x00";
CM_ SG_ 1380 LAD_01_BZ "freilaufender Botschaftszähler";
CM_ SG_ 1380 LAD_IstModus "Betriebsmodus des Ladegerätes";
CM_ SG_ 1380 LAD_AC_Istspannung "Istwert AC-Netzspannung (RMS) ";
CM_ SG_ 1380 LAD_IstSpannung_HV "Ausgangsspannung Lader";
CM_ SG_ 1380 LAD_IstStrom_HV "Ausgangsstrom Lader";
CM_ SG_ 1380 LAD_Status_Spgfreiheit "0 = Init (ohne Funktion)
1 = Ladegerät HV-Komponenten spannungsfrei (U_Zwkr < 20V)
2 = Ladegerät HV_Komponenten nicht spannungsfrei (U_Zwkr >= 20V)
3 = Fehler (z. B. Fehler in der Sensorik)";
CM_ SG_ 1380 LAD_Temperatur "Momentanwert: Temperatur Ladegerät";
CM_ SG_ 1380 LAD_Verlustleistung "Momentanwert: Verlustleistung Ladegerät";
CM_ SG_ 1662 LAD_02_CHK "Berechnung siehe Konzern-Lastenheft A-CAN V4.2a
Checksummenendwert = 0x00";
CM_ SG_ 1662 LAD_02_BZ "freilaufender Botschaftszähler";
CM_ SG_ 1662 LAD_Abregelung_Temperatur "Abregelung aufgrund interner Übertemperatur im Ladegerät";
CM_ SG_ 1662 LAD_Abregelung_IU_Ein_Aus "Abregelung aufgrund Strom oder Spannung am Eingang oder Ausgang";
CM_ SG_ 1662 LAD_Abregelung_BuchseTemp "Reduzierung aufgrund zu hoher Temperatur der Ladebuchse";
CM_ SG_ 1662 LAD_Warnlampe_Anf "Anforderung der gelben Hybrid-Warnlampe im Kombi (Motorsteuergerät reicht diese Info an Kombi weiter).";
CM_ SG_ 1662 LAD_MaxLadLeistung_HV "Maximale Leistung Ladegerät bezogen auf die maximale Leistung Infrastruktur (Kabel, Ladestation) und Berücksichtigung des Ladegerät-Wirkungsgrades";
CM_ SG_ 1662 LAD_CP_Stromlimit "AC-Stromlimit aufgrund des CP Duty Cycles";
CM_ SG_ 1662 LAD_PRX_Stromlimit "AC-Stromlimit aufgrund der PRX Kabelkodierung";
CM_ SG_ 1662 LAD_CP_Erkennung "Status Control Pilot Überwachung (Erkennung des Control Pilot Duty-Cycles)";
CM_ SG_ 1662 LAD_Stecker_Verriegelt "Status Steckerverriegelung (Rücklesekontakt des Verrieglungsaktors)";
CM_ SG_ 1662 LAD_Stecker_Gesteckt "Status Steckererkennung";
CM_ SG_ 1662 LAD_Kuehlbedarf "Kühlbedarf des Ladegerätes";
CM_ SG_ 1662 LAD_MaxLadLeistung_HV_Offset "Signal kann in Ergänzung zu LAD_MaxLadLeistung_HV (100W Skalierung) genutzt werden, um die Auflösegenauigkeit auf 25W zu erweitern.";
CM_ SG_ 1662 LAD_Fehlerstatus "aktueller Fehlerstatus des Ladegerätes
0: Komponente IO (keine HVK relevanter Fehler)
1: Eingeschränkte_Komponentenfunktion AC Laden nicht möglich
2: Eingeschränkte_Komponentenfunktion DC Laden nicht möglich
3: Eingeschr_Komponentenfunktion aufgrund H";
CM_ SG_ 1662 LAD_Warnzustand "Sammelwarnung Ladegerät
0 keine Warnbedingung aktiv
1 Warnbedingung aktiv, evtl. eingeschränkte Leistungsfähigkeit";
CM_ SG_ 1662 LAD_Fehlerzustand "Sammelfehler Ladegerät - kein Laden möglich";
CM_ SG_ 934 MSG_HYB_01_CHK "Berechnung siehe Konzern-Lastenheft A-CAN V4.2a
Checksummenendwert = 0x00";
CM_ SG_ 934 MSG_HYB_01_BZ "freilaufender Botschaftszähler";
CM_ SG_ 934 MO_SleepAckn "Nach Empfang des 'Sleep Acknowledge' muss der Sendebetrieb sofort eingestellt werden; die CAN-Schnittstelle (empfangseitig) wird nach der Wartezeit (750 ms) komplett abgeschaltet";
CM_ SG_ 934 MO_ErwGrenzen_Anf "temporäre Anforderung erweiterter Leistungsgrenzen
0 = normaler Betrieb angefordert
1 = erweiterte Leistungsgrenzen angefordert
BMS und EMS liefern ggf. erweiterte Leistungsgrenzen, um VKM-Start auch unter schwierigen Bedingungen gewährleisten zu könne";
CM_ SG_ 934 MO_Fehler_Notentladung_Anf "Aufforderung zur schnellstmöglichen Entladeung des HV-Zwischenkreises aufgrund Crash-Erkennung / Abriss Pilotlinie";
CM_ SG_ 934 MO_DC_Sollmodus "angeforderte Soll-Betriebsart des DC/DC-Wandlers: 
0: Standby; Kommunikation aktiv
1: Tiefsetzen (HV --> BN 14,4V)
    Sollwertvorgabe projektabhängig vom BSG/BCM über Lin/BSS oder vom MSG über 'MO_DC_SollSpannung_NV' bzw. 'MY2_DC_uSetPLV'
    (PQ35/P";
CM_ SG_ 934 MO_DC_LangsRegelung_Anf "Anforderung Regelmodus für den DC/DC-Wandlers: 
0: normale Regelung
1: langsame Regelung";
CM_ SG_ 934 MO_BMS_Sollmodus "angeforderte Soll-Betriebsart der Batterie: 
0: Standby; Kommunikation aktiv
1: HV-Netz aktivieren / normaler Fahrbetrieb
2: Balancing-Modus
3:  HV-Netz aktivieren / externes_Laden_Fremdstart
4:  HV-Netz aktivieren / externes Laden_EV_PlugIn
5: nich";
CM_ SG_ 934 MO_BMS_IsoMessung_Anf "Anforderung einer Isolationsmessung. Das BMS prüft auf Anforderung das HV-Netz auf Isolationsfehler.";
CM_ SG_ 934 MO_HV_Deaktivierungsmodus "Das Signal beschreibt ob der HV-Koordinator das HV-System für den Werkstatt-Service aktiviert oder deaktiviert hat.
Der angezeigte Status bezieht sich nur auf die mittels VAS-Tester ausgelöste Aktivierung/Deaktivierung.";
CM_ SG_ 934 MO_LG_Sollmodus "Sollmodus Ladegerät
0: Standby
1: AC-Netzladung (gesteuert durch EV-Lademanagement)
2: Reserve
3: DC-Netzladung
4..6: Reserve
7: Init";
CM_ SG_ 934 MO_Ladebereit "Statusflag, ob Fahrzeug sicher abgestellt ist (Wählhebel in P, EPB / Handbremse, v <=0), erst dann darf Tankdeckel und/oder Steckerverriegelung aufgehoben werden.";
CM_ SG_ 935 MSG_HYB_02_CHK "Berechnung siehe Konzern-Lastenheft A-CAN V4.2a
Checksummenendwert = 0x00";
CM_ SG_ 935 MSG_HYB_02_BZ "freilaufender Botschaftszähler";
CM_ SG_ 935 MO_DC_SollSpannung_NV "Sollwert für die Bordnetzspannung im Tiefsetzbetrieb vom Traktionsnetz ins Bordnetz
vorgehaltenes Signal; wird derzeit in PQ35/PL71 nicht berücksichtigt";
CM_ SG_ 935 MO_DC_Max_Strom_HV "Abregelgrenze: maximal freigegebener Strom auf der Hochvolt-Seite im Tiefsetzbetrieb (Strom aus dem Traktionsnetz ins Bordnetz)";
CM_ SG_ 935 MO_DC_Min_Spannung_HV "Abregelgrenze: minimal erlaubte Spannung im Hochvoltnetz im Tiefsetzbetrieb
vorgehaltenes Signal; wird in PQ35/PL71 nicht berücksichtigt";
CM_ SG_ 935 MO_DC_SollSpannung_HV "Sollwert für die Traktionsnetzspannung im Hochsetzbetrieb vom Bordnetz ins Traktionsnetz
vorgehaltenes Signal; wird in PQ35/PL71 nicht berücksichtigt";
CM_ SG_ 935 MO_DC_Max_Strom_NV "Abregelgrenze: maximal freigegebener Strom auf der Bordnetzseite im Hochsetzbetrieb
vorgehaltenes Signal; wird in PQ35/PL71 nicht berücksichtigt";
CM_ SG_ 935 MO_DC_Min_Spannung_NV "Abregelgrenze: minimal erlaubte Bordnetzspannung im Hochsetzbetrieb
vorgehaltenes Signal; wird in PQ35/PL71 nicht berücksichtigt";
CM_ SG_ 144 MSG_HYB_03_CHK "Berechnung siehe Konzern-Lastenheft A-CAN V4.2a
Checksummenendwert = 0x00";
CM_ SG_ 144 MSG_HYB_03_BZ "freilaufender Botschaftszähler";
CM_ SG_ 144 MO_EM_Sollmodus "Werte:
  Anforderung der Betriebsart der E-Maschine
0: Standby; Kommunikation aktiv; aktiver Kurzschluss
1: Momentenregelung
2: Drehzahlregelung (interner Regelkreis)
3: Spannungsregelung
4: Drehzahlregelung (externer Regelkreis)
5: nicht verfügbar";
CM_ SG_ 144 MO_EM_SollMoment "E-Maschinen Soll-Moment vom Hybridcontroller";
CM_ SG_ 144 MO_EM_SollDrehzahl "E-Maschinen Soll-Drehzahl";
CM_ SG_ 144 MO_EM_SollSpannung "E-Maschinen Soll-Spannung";
CM_ SG_ 144 MO_Waehlpos "Wählhebelposition (im VW120/7 und MQB BEV ist der Wählhebel am HCAN mit Master Motor-SG angeschlossen)

(wenn das Signal zusätzlich in Botschaft MSG_HYB_03 verortet ist, gilt: Signal nur in der CAN-Welt PQ35/25 zu verwenden, da dort am ACAN die Wählhebe";
CM_ SG_ 145 MSG_HYB_07_CHK "Berechnung siehe Konzern-Lastenheft A-CAN V4.2a
Checksummenendwert = 0x00";
CM_ SG_ 145 MSG_HYB_07_BZ "freilaufender Botschaftszähler";
CM_ SG_ 145 MO_EM_AR_Anf "Anforderung der Anti-Ruckel Funktion auf der E-Maschine
0: aus
1: extern (nur externe Eingriffe vom Getriebe (PQ35))
2: ein (interne Regelung anhand Regelparameter (MSG_HYB_07) und externe Eingriffe vom Getriebe (PQ35))
    Getriebe-Eingriffe haben Pr";
CM_ SG_ 145 MO_EM_Dyn_Kp_AR "dynamischer Verstärkungsfaktor zur Umrechnung Drehzahlschwingung in Deltamoment";
CM_ SG_ 145 MO_EM_Stat_Kp_AR "stationärer Verstärkungsfaktor zur Umrechnung Drehzahlschwingung in Deltamoment";
CM_ SG_ 145 MO_EM_DynLimit_AR "Auslöseschwelle für dynamische Ruckeldämpfung";
CM_ SG_ 145 MO_EM_StatLimit_AR "Auslöseschwelle für stationäre Ruckeldämpfung";
CM_ SG_ 145 MO_EM_Periode_AR "Zeitkonstante (Periodendauer) der Ruckelschwingung (abhängig vom Gang und ggf. elektrischem/hybridischem Fahren) ";
CM_ SG_ 145 MO_EM_Strom_HVVerbraucher "aktueller Strombedarf der elektrischen Verbraucher im Hochspannungsnetz";
CM_ SG_ 146 MSG_HYB_08_CHK "Berechnung siehe Konzern-Lastenheft A-CAN V4.2a
Checksummenendwert = 0x00";
CM_ SG_ 146 MSG_HYB_08_BZ "freilaufender Botschaftszähler";
CM_ SG_ 146 MO_EM_MinMoment_DrzRegler "maximal erlaubtes negatives Moment für Eingriffe des Drehzahlreglers";
CM_ SG_ 146 MO_EM_MaxMoment_DrzRegler "maximal erlaubtes positives Moment für Eingriffe des Drehzahlreglers";
CM_ SG_ 146 MO_EM_Band_KpKlein_DrzRegler "Drehzahlgrenze";
CM_ SG_ 146 MO_EM_KpKlein_DrzRegler "P-Anteil Kleinsignalverstärkung";
CM_ SG_ 146 MO_EM_KpGross_DrzRegler "P-Anteil Großsignalverstärkung";
CM_ SG_ 936 MSG_HYB_09_CHK "Berechnung siehe Konzern-Lastenheft A-CAN V4.2a
Checksummenendwert = 0x00";
CM_ SG_ 936 MSG_HYB_09_BZ "freilaufender Botschaftszähler";
CM_ SG_ 936 MO_EM_Max_Moment "maximal erlaubtes positives (motorisches) Moment der E-Maschine aus Hybridstrategie
Anmerkung: Signal wird in der PL71/PQ35 zyklisch im 100ms-Raster gesendet, Sendemodus 'bei Änderung sofort' wird hier nicht unterstützt";
CM_ SG_ 936 MO_EM_Min_Moment "maximal erlaubtes negatives (generatorisches) Moment der E-Maschine aus Hybridstrategie
Anmerkung: Signal wird in der PL71/PQ35 zyklisch im 100ms-Raster gesendet, Sendemodus 'bei Änderung sofort' wird hier nicht unterstützt";
CM_ SG_ 936 MO_EM_Max_Momentengradient "maximale Änderung des E-Maschinen Moments (0xFF bedeutet keine Begrenzung)
Anmerkung: Signal wird in der PL71/PQ35 zyklisch im 100ms-Raster gesendet, Sendemodus 'bei Änderung sofort' wird hier nicht unterstützt";
CM_ SG_ 936 MO_EM_Max_Moment_AR "maximal zur Verfügung gestelltes Moment für eine aktive Triebstrang-Schwingungsdämpfung über die E-Maschine
Anmerkung: Signal wird in der PL71/PQ35 zyklisch im 100ms-Raster gesendet, Sendemodus 'bei Änderung sofort' wird hier nicht unterstützt";
CM_ SG_ 936 MO_EM_MaxPred_Strom "rechnerischer Wert für Momentenprädiktion: maximaler, für die Dauer von ~10s verfügbarer quasistationärer Strom (für maximales positives Moment; i.A. positiv, daher Max)";
CM_ SG_ 936 MO_EM_MinPred_Strom "rechnerischer Wert für Momentenprädiktion: minimaler, für die Dauer von ~10s verfügbarer quasistationärer Strom (für maximales negatives Moment; i.A. negativ, daher Min)";
CM_ SG_ 1698 MSG_HYB_10_CHK "Berechnung siehe Konzern-Lastenheft A-CAN V4.2a
Checksummenendwert = 0x00";
CM_ SG_ 1698 MSG_HYB_10_BZ "freilaufender Botschaftszähler";
CM_ SG_ 1698 MO_EM_Kuehlpumpe_Soll "Sollansteuerung Kühlwasserpumpe Niedertemperaturkreis Leistungselektronik";
CM_ SG_ 1698 MO_Abstellzeit "Abstelldauer nach letztem KL15 aus";
CM_ SG_ 1698 MO_Abstellzeit_Status "Statusinformation zur Abstellzeit
0: Die dem Status zugeordnete Variable konnte noch nicht berechnet werden. 
1: Die dem Status zugehörige Variable wurde korrekt berechnet. 
2: Der Wert der zugehörigen Variablen ist nur ein Minimalwert. 
3: Der Wert d";
CM_ SG_ 1698 MO_EM_NTKreisPumpe1_Status "Status Pumpe_1 Niedertemperatur-Kühlkreislauf:
0: Pumpe nicht angesteuert;
1: Pumpe geregelt angesteuert (Pumpleistung <100%)
2: Pumpe voll angesteuert (Pumpleistung 100%)
3: Pumpe angesteuert; keine Pumpleistung, da Pumpe defekt";
CM_ SG_ 1698 MO_EM_NTKreisPumpe2_Status "Status Pumpe_2 Niedertemperatur-Kühlkreislauf:
0: Pumpe nicht angesteuert;
1: Pumpe geregelt angesteuert (Pumpleistung <100%)
2: Pumpe voll angesteuert (Pumpleistung 100%)
3: Pumpe angesteuert; keine Pumpleistung, da Pumpe defekt";
CM_ SG_ 1698 MO_EM_NTKreis_Status "Status Kühlmittelfluss im Niedertemperatur-Kühlkreislauf:
0: kein Kühlmittelfluss; entspricht Sollvorgabe
1: normaler Kühlmittelfluss; entspricht Sollvorgabe
2: reduzierter Kühlmittelfluss; entspricht nicht Sollvorgabe; Fehler im Kühlkreislauf
3: kein";
CM_ SG_ 1698 MO_EM_HTKreisPumpe1_Status "Status Pumpe_1 Hochtemperatur-Kühlkreislauf:
0: Pumpe nicht angesteuert;
1: Pumpe geregelt angesteuert (Pumpleistung <100%)
2: Pumpe voll angesteuert (Pumpleistung 100%)
3: Pumpe angesteuert; keine Pumpleistung, da Pumpe defekt";
CM_ SG_ 1698 MO_EM_HTKreisPumpe2_Status "Status Pumpe_2 Hochtemperatur-Kühlkreislauf:
0: Pumpe nicht angesteuert;
1: Pumpe geregelt angesteuert (Pumpleistung <100%)
2: Pumpe voll angesteuert (Pumpleistung 100%)
3: Pumpe angesteuert; keine Pumpleistung, da Pumpe defekt";
CM_ SG_ 1698 MO_EM_HTKreis_Status "Status Kühlmittelfluss im Hochtemperatur-Kühlkreislauf:
0: kein Kühlmittelfluss; entspricht Sollvorgabe
1: normaler Kühlmittelfluss; entspricht Sollvorgabe
2: reduzierter Kühlmittelfluss; entspricht nicht Sollvorgabe; Fehler im Kühlkreislauf
3: kein K";
CM_ SG_ 1698 MO_LuefterGeschw_rel "Relativwert der Ansteuerung der Kühlerlüfter bezogen auf Maximalwert";
CM_ SG_ 1698 MO_Temp_Kuehleraustritt "Kühlmitteltemperatur nach Kühlerausgang (wird von LE zur Berechnung Rotortemperaturmodell benötigt)";
CM_ SG_ 150 MSG_HYB_15_CHK "Berechnung siehe Konzern-Lastenheft A-CAN V4.2a
Checksummenendwert = 0x00";
CM_ SG_ 150 MSG_HYB_15_BZ "Freilaufender Botschaftszaehler";
CM_ SG_ 150 MO_CCU_Sollmodus "Sollmodus Aktuator
1: Secure_Mode 
2: Operation_Mode
3: RemovingAir_Mode
4: Filling_Mode
5: Info_Mode (Ueber Info_Mode kann die zusaetzliche Botschaft CCU_HYB_02 angefordert werden)
6: reserve
7: MSG befindet sich in der Init-Phase; aktuelle Signal";
CM_ SG_ 150 MO_CCU_DruckLim_Anf "Druckbegrenzung aktivieren";
CM_ SG_ 150 MO_CCU_PHEV_Mode "Aktivierung Sonderfunktion Spindelaktuator";
CM_ SG_ 150 MO_CCU_HSR_Hyst "Vorgabe Lagereglerhysterese in Winkelgrad [°]";
CM_ SG_ 150 MO_CCU_Sollposition "Sollposition";
CM_ SG_ 196 MSG_HYB_22_CHK "Berechnung siehe Konzern-Lastenheft A-CAN V4.2a
Checksummenendwert = 0x00";
CM_ SG_ 196 MSG_HYB_22_BZ "freilaufender Botschaftszähler";
CM_ SG_ 196 MO_GPM_act_swt "Anforderung an Aktuatorposition";
CM_ SG_ 196 MO_GPM_self_test "Anforderung an Aktuator zur Durchführung eines Selbsttests";
CM_ SG_ 196 MO_QBit_GPM_Fahrpedalwerte_01 "QBit für beide Fahrpedalwerte des Motors (Fahrpedalrohsignal für GPM)";
CM_ SG_ 196 MO_GPM_sollact_pos "Vorgabe Sollaktuatorposition auf Aktuatorweg bezogen";
CM_ SG_ 196 MO_GPM_sollactpv_pos "Vorgabe Sollaktuatorposition auf Pedalweg bezogen";
CM_ SG_ 196 MO_GPM_Fahrpedalrohwert "Stellung des Fahrpedales (Rohwert, ohne Überlagerung durch GRA-Eingriffe etc.) für Gaspedalaktuator";
BA_DEF_  "DBName" STRING ;
BA_DEF_  "GenNWMApBusSleep" STRING ;
BA_DEF_  "GenNWMApCanNormal" STRING ;
BA_DEF_  "GenNWMApCanOff" STRING ;
BA_DEF_  "GenNWMApCanOn" STRING ;
BA_DEF_  "GenNWMApCanSleep" STRING ;
BA_DEF_  "GenNWMApCanWakeUp" STRING ;
BA_DEF_  "GenNWMGotoMode_Awake" STRING ;
BA_DEF_  "GenNWMGotoMode_BusSleep" STRING ;
BA_DEF_  "GenNWMSleepTime" INT 0 1000000;
BA_DEF_  "GenNWMTalkNM" STRING ;
BA_DEF_  "Manufacturer" STRING ;
BA_DEF_  "NmType" STRING ;
BA_DEF_  "VAGTP20_SetupMessageCount" INT 0 255;
BA_DEF_  "VAGTP20_SetupStartAddress" HEX 0 2047;
BA_DEF_  "VersionDay" INT 1 31;
BA_DEF_  "VersionMonth" INT 1 12;
BA_DEF_  "VersionWeek" INT 1 52;
BA_DEF_  "VersionYear" INT 0 99;
BA_DEF_  "VersionNumber" INT 0 65535;
BA_DEF_  "Baudrate" INT 0 1000000;
BA_DEF_  "SamplePointMin" INT 1 100;
BA_DEF_  "SamplePointMax" INT 1 100;
BA_DEF_  "SyncJumpWidthMin" INT 1 4;
BA_DEF_  "SyncJumpWidthMax" INT 1 4;
BA_DEF_ BU_  "GenNodAutoGenDsp" ENUM  "No","Yes";
BA_DEF_ BU_  "GenNodAutoGenSnd" ENUM  "No","Yes";
BA_DEF_ BU_  "GenNodSleepTime" INT 0 1000000;
BA_DEF_ BU_  "ILUsed" ENUM  "No","Yes";
BA_DEF_ BU_  "ECUVariantDefault" ENUM  "No","Yes";
BA_DEF_ BU_  "NodeLayerModules" STRING ;
BA_DEF_ BU_  "NmhNode" ENUM  "No","Yes";
BA_DEF_ BU_  "NmNode" ENUM  "No","Yes";
BA_DEF_ BO_  "DiagRequest" ENUM  "No","Yes";
BA_DEF_ BO_  "DiagResponse" ENUM  "No","Yes";
BA_DEF_ BO_  "DiagState" ENUM  "No","Yes";
BA_DEF_ BO_  "GenMsgChkConstant" HEX 0 4095;
BA_DEF_ BO_  "GenMsgCycleTime" INT 0 65535;
BA_DEF_ BO_  "GenMsgCycleTimeFast" INT 0 65535;
BA_DEF_ BO_  "GenMsgDelayTime" INT 0 100000;
BA_DEF_ BO_  "GenMsgILSupport" ENUM  "No","Yes";
BA_DEF_ BO_  "GenMsgNrOfRepetition" INT 0 100;
BA_DEF_ BO_  "GenMsgPDUConstants" STRING ;
BA_DEF_ BO_  "GenMsgSendType" ENUM  "Cyclic","not_used","not_used","not_used","not_used","not_used","not_used","IfActive","NoMsgSendType";
BA_DEF_ BO_  "GenMsgStartDelayTime" INT 0 100000;
BA_DEF_ BO_  "NmMessage" ENUM  "No","Yes";
BA_DEF_ BO_  "NmhMessage" ENUM  "No","Yes";
BA_DEF_ BO_  "MsgType" ENUM  "Application","NM ","NMH","TP2.0","ISO-TP ","BAP","EID";
BA_DEF_ BO_  "VAGTP20_API" HEX 0 255;
BA_DEF_ BO_  "VAGTP20_DynConnection" ENUM  "No","Yes";
BA_DEF_ BO_  "VAGTP20_DynSetup" ENUM  "No","Yes";
BA_DEF_ BO_  "VAGTP20_StatConnection" ENUM  "No","Yes";
BA_DEF_ SG_  "GenSigActiveRepetitions" INT -2147483648 2147483647;
BA_DEF_ SG_  "GenSigInactiveValue" INT -2147483648 2147483647;
BA_DEF_ SG_  "GenSigSendType" ENUM  "Cyclic","OnWrite","OnWriteWithRepetition","OnChange","OnChangeWithRepetition","IfActive","IfActiveWithRepetition","NoSigSendType","OnChangeAndIfActive","OnChangeAndIfActiveWithRepetition";
BA_DEF_ SG_  "GenSigStartValue" INT -2147483648 2147483647;
BA_DEF_ SG_  "NWM-WakeupAllowed" ENUM  "No","Yes";
BA_DEF_ SG_  "GenSigFuncType" ENUM  "NoFunction","MsgCounter","CRC-8","XOR","XOR-2","DatedBit","SW-Kl15","CHK","Constant","Protocol","CRC-8-SAE_J1850";
BA_DEF_ SG_  "GenSigSwitchedByIgnition" ENUM  "No","Yes";
BA_DEF_ SG_  "Fehlerwert" HEX 0 2147483647;
BA_DEF_ SG_  "GenSigMissingSourceValue" HEX 0 2147483647;
BA_DEF_REL_ BU_SG_REL_  "GenSigTimeoutTime" INT 0 65535;
BA_DEF_DEF_  "DBName" "";
BA_DEF_DEF_  "GenNWMApBusSleep" "";
BA_DEF_DEF_  "GenNWMApCanNormal" "";
BA_DEF_DEF_  "GenNWMApCanOff" "";
BA_DEF_DEF_  "GenNWMApCanOn" "";
BA_DEF_DEF_  "GenNWMApCanSleep" "";
BA_DEF_DEF_  "GenNWMApCanWakeUp" "";
BA_DEF_DEF_  "GenNWMGotoMode_Awake" "";
BA_DEF_DEF_  "GenNWMGotoMode_BusSleep" "";
BA_DEF_DEF_  "GenNWMSleepTime" 0;
BA_DEF_DEF_  "GenNWMTalkNM" "";
BA_DEF_DEF_  "Manufacturer" "";
BA_DEF_DEF_  "NmType" "None";
BA_DEF_DEF_  "VAGTP20_SetupMessageCount" 0;
BA_DEF_DEF_  "VAGTP20_SetupStartAddress" 0;
BA_DEF_DEF_  "VersionDay" 13;
BA_DEF_DEF_  "VersionMonth" 8;
BA_DEF_DEF_  "VersionWeek" 33;
BA_DEF_DEF_  "VersionYear" 12;
BA_DEF_DEF_  "VersionNumber" 0;
BA_DEF_DEF_  "Baudrate" 0;
BA_DEF_DEF_  "SamplePointMin" 1;
BA_DEF_DEF_  "SamplePointMax" 1;
BA_DEF_DEF_  "SyncJumpWidthMin" 1;
BA_DEF_DEF_  "SyncJumpWidthMax" 1;
BA_DEF_DEF_  "GenNodAutoGenDsp" "Yes";
BA_DEF_DEF_  "GenNodAutoGenSnd" "Yes";
BA_DEF_DEF_  "GenNodSleepTime" 0;
BA_DEF_DEF_  "ILUsed" "Yes";
BA_DEF_DEF_  "ECUVariantDefault" "Yes";
BA_DEF_DEF_  "NodeLayerModules" "";
BA_DEF_DEF_  "NmhNode" "Yes";
BA_DEF_DEF_  "NmNode" "No";
BA_DEF_DEF_  "DiagRequest" "No";
BA_DEF_DEF_  "DiagResponse" "No";
BA_DEF_DEF_  "DiagState" "No";
BA_DEF_DEF_  "GenMsgChkConstant" 0;
BA_DEF_DEF_  "GenMsgCycleTime" 0;
BA_DEF_DEF_  "GenMsgCycleTimeFast" 0;
BA_DEF_DEF_  "GenMsgDelayTime" 0;
BA_DEF_DEF_  "GenMsgILSupport" "No";
BA_DEF_DEF_  "GenMsgNrOfRepetition" 0;
BA_DEF_DEF_  "GenMsgPDUConstants" "";
BA_DEF_DEF_  "GenMsgSendType" "NoMsgSendType";
BA_DEF_DEF_  "GenMsgStartDelayTime" 0;
BA_DEF_DEF_  "NmMessage" "No";
BA_DEF_DEF_  "NmhMessage" "No";
BA_DEF_DEF_  "MsgType" "Application";
BA_DEF_DEF_  "VAGTP20_API" 0;
BA_DEF_DEF_  "VAGTP20_DynConnection" "No";
BA_DEF_DEF_  "VAGTP20_DynSetup" "No";
BA_DEF_DEF_  "VAGTP20_StatConnection" "No";
BA_DEF_DEF_  "GenSigActiveRepetitions" 0;
BA_DEF_DEF_  "GenSigInactiveValue" 0;
BA_DEF_DEF_  "GenSigSendType" "NoSigSendType";
BA_DEF_DEF_  "GenSigStartValue" 0;
BA_DEF_DEF_  "NWM-WakeupAllowed" "No";
BA_DEF_DEF_  "GenSigFuncType" "NoFunction";
BA_DEF_DEF_  "GenSigSwitchedByIgnition" "Yes";
BA_DEF_DEF_  "Fehlerwert" 0;
BA_DEF_DEF_  "GenSigMissingSourceValue" 0;
BA_DEF_DEF_REL_ "GenSigTimeoutTime" 0;
BA_ "SyncJumpWidthMax" 4;
BA_ "SyncJumpWidthMin" 2;
BA_ "SamplePointMax" 84;
BA_ "SamplePointMin" 80;
BA_ "Baudrate" 500000;
BA_ "VersionNumber" 1201;
BA_ "VersionWeek" 30;
BA_ "VersionMonth" 7;
BA_ "VersionDay" 27;
BA_ "VAGTP20_SetupStartAddress" 512;
BA_ "VAGTP20_SetupMessageCount" 128;
BA_ "Manufacturer" "PAG";
BA_ "GenNWMSleepTime" 4000;
BA_ "DBName" "PAG_Plattform_CAN_Hybrid";
BA_ "NmhNode" BU_ BMS_PlugIn 0;
BA_ "GenNodSleepTime" BU_ BMS_PlugIn 4000;
BA_ "NmhNode" BU_ CCU_VW526 0;
BA_ "GenNodSleepTime" BU_ CCU_VW526 4000;
BA_ "NmhNode" BU_ GPM_PAG_PF 0;
BA_ "GenNodSleepTime" BU_ GPM_PAG_PF 4000;
BA_ "NmhNode" BU_ Ladegeraet_PAG_PF 0;
BA_ "GenNodSleepTime" BU_ Ladegeraet_PAG_PF 4000;
BA_ "NmhNode" BU_ LEH_PlugIn 0;
BA_ "GenNodSleepTime" BU_ LEH_PlugIn 4000;
BA_ "NmhNode" BU_ Motor_MED17_SIMOS8_PlugIn_PAG_PF 0;
BA_ "GenNodSleepTime" BU_ Motor_MED17_SIMOS8_PlugIn_PAG_PF 4000;
BA_ "NmhNode" BU_ Tester_DEV_PAG 0;
BA_ "GenNodSleepTime" BU_ Tester_DEV_PAG 4000;
BA_ "GenMsgSendType" BO_ 151 0;
BA_ "GenMsgILSupport" BO_ 151 1;
BA_ "GenMsgCycleTime" BO_ 151 10;
BA_ "GenMsgSendType" BO_ 938 0;
BA_ "GenMsgILSupport" BO_ 938 1;
BA_ "GenMsgCycleTime" BO_ 938 100;
BA_ "GenMsgSendType" BO_ 292 0;
BA_ "GenMsgILSupport" BO_ 292 1;
BA_ "GenMsgCycleTime" BO_ 292 20;
BA_ "GenMsgSendType" BO_ 1699 0;
BA_ "GenMsgILSupport" BO_ 1699 1;
BA_ "GenMsgCycleTime" BO_ 1699 500;
BA_ "GenMsgSendType" BO_ 1723 0;
BA_ "GenMsgILSupport" BO_ 1723 1;
BA_ "GenMsgCycleTime" BO_ 1723 1000;
BA_ "GenMsgSendType" BO_ 1161 0;
BA_ "GenMsgILSupport" BO_ 1161 1;
BA_ "GenMsgCycleTime" BO_ 1161 100;
BA_ "MsgType" BO_ 2617236992 6;
BA_ "MsgType" BO_ 2281692672 6;
BA_ "MsgType" BO_ 2617236993 6;
BA_ "MsgType" BO_ 2281692673 6;
BA_ "MsgType" BO_ 2617239041 6;
BA_ "MsgType" BO_ 2566690560 6;
BA_ "MsgType" BO_ 2566690561 6;
BA_ "MsgType" BO_ 2617124352 6;
BA_ "MsgType" BO_ 2617124353 6;
BA_ "MsgType" BO_ 1666 6;
BA_ "GenMsgSendType" BO_ 127 0;
BA_ "GenMsgILSupport" BO_ 127 1;
BA_ "GenMsgCycleTime" BO_ 127 5;
BA_ "GenMsgILSupport" BO_ 1715 1;
BA_ "GenMsgDelayTime" BO_ 1715 1000;
BA_ "GenMsgSendType" BO_ 156 0;
BA_ "GenMsgILSupport" BO_ 156 1;
BA_ "GenMsgCycleTime" BO_ 156 10;
BA_ "GenMsgSendType" BO_ 943 0;
BA_ "GenMsgILSupport" BO_ 943 1;
BA_ "GenMsgCycleTime" BO_ 943 100;
BA_ "MsgType" BO_ 2617235968 6;
BA_ "MsgType" BO_ 2617235969 6;
BA_ "MsgType" BO_ 2617235970 6;
BA_ "MsgType" BO_ 2617235971 6;
BA_ "MsgType" BO_ 2617235972 6;
BA_ "MsgType" BO_ 2617235973 6;
BA_ "MsgType" BO_ 2617235974 6;
BA_ "MsgType" BO_ 2617235975 6;
BA_ "MsgType" BO_ 2566821632 6;
BA_ "MsgType" BO_ 2566821633 6;
BA_ "MsgType" BO_ 2566821634 6;
BA_ "MsgType" BO_ 2617123328 6;
BA_ "MsgType" BO_ 2617123329 6;
BA_ "MsgType" BO_ 2617123330 6;
BA_ "MsgType" BO_ 2617123331 6;
BA_ "MsgType" BO_ 2617123332 6;
BA_ "MsgType" BO_ 2617123333 6;
BA_ "MsgType" BO_ 2617123334 6;
BA_ "GenMsgSendType" BO_ 152 0;
BA_ "GenMsgILSupport" BO_ 152 1;
BA_ "GenMsgCycleTime" BO_ 152 10;
BA_ "GenMsgSendType" BO_ 939 0;
BA_ "GenMsgILSupport" BO_ 939 1;
BA_ "GenMsgDelayTime" BO_ 939 10;
BA_ "GenMsgCycleTime" BO_ 939 100;
BA_ "GenMsgSendType" BO_ 940 0;
BA_ "GenMsgILSupport" BO_ 940 1;
BA_ "GenMsgCycleTime" BO_ 940 100;
BA_ "GenMsgSendType" BO_ 1700 0;
BA_ "GenMsgILSupport" BO_ 1700 1;
BA_ "GenMsgCycleTime" BO_ 1700 500;
BA_ "GenMsgSendType" BO_ 153 0;
BA_ "GenMsgILSupport" BO_ 153 1;
BA_ "GenMsgCycleTime" BO_ 153 10;
BA_ "GenMsgSendType" BO_ 81 0;
BA_ "GenMsgILSupport" BO_ 81 1;
BA_ "GenMsgCycleTime" BO_ 81 2;
BA_ "GenMsgSendType" BO_ 195 0;
BA_ "GenMsgPDUConstants" BO_ 195 "0xc3,0xc3,0xc3,0xc3,0xc3,0xc3,0xc3,0xc3,0xc3,0xc3,0xc3,0xc3,0xc3,0xc3,0xc3,0xc3";
BA_ "GenMsgILSupport" BO_ 195 1;
BA_ "GenMsgCycleTime" BO_ 195 10;
BA_ "GenMsgChkConstant" BO_ 195 195;
BA_ "GenMsgSendType" BO_ 1705 0;
BA_ "GenMsgILSupport" BO_ 1705 1;
BA_ "GenMsgCycleTime" BO_ 1705 1000;
BA_ "GenMsgSendType" BO_ 1382 0;
BA_ "GenMsgILSupport" BO_ 1382 1;
BA_ "GenMsgCycleTime" BO_ 1382 100;
BA_ "GenMsgSendType" BO_ 1381 0;
BA_ "GenMsgILSupport" BO_ 1381 1;
BA_ "GenMsgDelayTime" BO_ 1381 50;
BA_ "GenMsgCycleTime" BO_ 1381 500;
BA_ "GenMsgSendType" BO_ 1380 0;
BA_ "GenMsgPDUConstants" BO_ 1380 "0x24,0x24,0x24,0x24,0x24,0x24,0x24,0x24,0x24,0x24,0x24,0x24,0x24,0x24,0x24,0x24";
BA_ "GenMsgNrOfRepetition" BO_ 1380 5;
BA_ "GenMsgILSupport" BO_ 1380 1;
BA_ "GenMsgDelayTime" BO_ 1380 100;
BA_ "GenMsgCycleTimeFast" BO_ 1380 100;
BA_ "GenMsgCycleTime" BO_ 1380 1000;
BA_ "GenMsgChkConstant" BO_ 1380 36;
BA_ "GenMsgSendType" BO_ 1662 0;
BA_ "GenMsgPDUConstants" BO_ 1662 "0x25,0x25,0x25,0x25,0x25,0x25,0x25,0x25,0x25,0x25,0x25,0x25,0x25,0x25,0x25,0x25";
BA_ "GenMsgILSupport" BO_ 1662 1;
BA_ "GenMsgDelayTime" BO_ 1662 50;
BA_ "GenMsgCycleTime" BO_ 1662 1000;
BA_ "GenMsgChkConstant" BO_ 1662 37;
BA_ "GenMsgSendType" BO_ 934 0;
BA_ "GenMsgILSupport" BO_ 934 1;
BA_ "GenMsgDelayTime" BO_ 934 10;
BA_ "GenMsgCycleTime" BO_ 934 100;
BA_ "GenMsgSendType" BO_ 935 0;
BA_ "GenMsgILSupport" BO_ 935 1;
BA_ "GenMsgCycleTime" BO_ 935 100;
BA_ "GenMsgSendType" BO_ 144 0;
BA_ "GenMsgILSupport" BO_ 144 1;
BA_ "GenMsgCycleTime" BO_ 144 10;
BA_ "GenMsgSendType" BO_ 145 0;
BA_ "GenMsgILSupport" BO_ 145 1;
BA_ "GenMsgCycleTime" BO_ 145 10;
BA_ "GenMsgSendType" BO_ 146 0;
BA_ "GenMsgILSupport" BO_ 146 1;
BA_ "GenMsgCycleTime" BO_ 146 10;
BA_ "GenMsgSendType" BO_ 936 0;
BA_ "GenMsgILSupport" BO_ 936 1;
BA_ "GenMsgDelayTime" BO_ 936 10;
BA_ "GenMsgCycleTime" BO_ 936 100;
BA_ "GenMsgSendType" BO_ 1698 0;
BA_ "GenMsgILSupport" BO_ 1698 1;
BA_ "GenMsgCycleTime" BO_ 1698 500;
BA_ "GenMsgSendType" BO_ 150 0;
BA_ "GenMsgILSupport" BO_ 150 1;
BA_ "GenMsgCycleTime" BO_ 150 10;
BA_ "GenMsgSendType" BO_ 196 0;
BA_ "GenMsgILSupport" BO_ 196 1;
BA_ "GenMsgCycleTime" BO_ 196 10;
BA_ "GenSigSwitchedByIgnition" SG_ 151 BMS_HYB_02_CHK 0;
BA_ "GenSigFuncType" SG_ 151 BMS_HYB_02_CHK 4;
BA_ "GenSigSendType" SG_ 151 BMS_HYB_02_CHK 0;
BA_ "GenSigSwitchedByIgnition" SG_ 151 BMS_HYB_02_BZ 0;
BA_ "GenSigFuncType" SG_ 151 BMS_HYB_02_BZ 1;
BA_ "GenSigSendType" SG_ 151 BMS_HYB_02_BZ 0;
BA_ "Fehlerwert" SG_ 151 BMS_IstStrom 4095;
BA_ "GenSigSwitchedByIgnition" SG_ 151 BMS_IstStrom 0;
BA_ "GenSigStartValue" SG_ 151 BMS_IstStrom 4094;
BA_ "GenSigSendType" SG_ 151 BMS_IstStrom 0;
BA_ "Fehlerwert" SG_ 151 BMS_IstSpannung 4095;
BA_ "GenSigSwitchedByIgnition" SG_ 151 BMS_IstSpannung 0;
BA_ "GenSigStartValue" SG_ 151 BMS_IstSpannung 4094;
BA_ "GenSigSendType" SG_ 151 BMS_IstSpannung 0;
BA_ "GenSigSwitchedByIgnition" SG_ 151 BMS_IstModus 0;
BA_ "GenSigStartValue" SG_ 151 BMS_IstModus 7;
BA_ "GenSigSendType" SG_ 151 BMS_IstModus 0;
BA_ "GenSigSwitchedByIgnition" SG_ 151 BMS_SleepInd 0;
BA_ "GenSigSendType" SG_ 151 BMS_SleepInd 0;
BA_ "GenSigSwitchedByIgnition" SG_ 151 BMS_IsoMessungAktiv 0;
BA_ "GenSigSendType" SG_ 151 BMS_IsoMessungAktiv 0;
BA_ "GenSigSwitchedByIgnition" SG_ 151 BMS_Init_abgeschlossen 0;
BA_ "GenSigSendType" SG_ 151 BMS_Init_abgeschlossen 0;
BA_ "GenSigSwitchedByIgnition" SG_ 151 BMS_Status_Spgfreiheit 0;
BA_ "GenSigSendType" SG_ 151 BMS_Status_Spgfreiheit 0;
BA_ "GenSigSwitchedByIgnition" SG_ 151 BMS_Fehler_Notabschaltung_Crash 0;
BA_ "GenSigSendType" SG_ 151 BMS_Fehler_Notabschaltung_Crash 0;
BA_ "GenSigSwitchedByIgnition" SG_ 151 BMS_Fehler_Notabschaltung_Pilot 0;
BA_ "GenSigSendType" SG_ 151 BMS_Fehler_Notabschaltung_Pilot 0;
BA_ "GenSigSwitchedByIgnition" SG_ 151 BMS_Fehler_HVBattAbschaltung_Anf 0;
BA_ "GenSigSendType" SG_ 151 BMS_Fehler_HVBattAbschaltung_Anf 0;
BA_ "GenSigSwitchedByIgnition" SG_ 151 BMS_Fehler_HVBattAbschaltung 0;
BA_ "GenSigSendType" SG_ 151 BMS_Fehler_HVBattAbschaltung 0;
BA_ "GenSigSwitchedByIgnition" SG_ 151 BMS_Fehler_HS_verschweisst 0;
BA_ "GenSigSendType" SG_ 151 BMS_Fehler_HS_verschweisst 0;
BA_ "GenSigSwitchedByIgnition" SG_ 151 BMS_Fehler_HS_offen 0;
BA_ "GenSigSendType" SG_ 151 BMS_Fehler_HS_offen 0;
BA_ "GenSigSwitchedByIgnition" SG_ 151 BMS_Fehler_Leistungsred 0;
BA_ "GenSigSendType" SG_ 151 BMS_Fehler_Leistungsred 0;
BA_ "GenSigSwitchedByIgnition" SG_ 151 BMS_Fehler_Isolation 0;
BA_ "GenSigSendType" SG_ 151 BMS_Fehler_Isolation 0;
BA_ "GenSigSwitchedByIgnition" SG_ 151 BMS_Fehler_Kaltstartleistung 0;
BA_ "GenSigSendType" SG_ 151 BMS_Fehler_Kaltstartleistung 0;
BA_ "GenSigSwitchedByIgnition" SG_ 151 BMS_Fehler_Pilot 0;
BA_ "GenSigSendType" SG_ 151 BMS_Fehler_Pilot 0;
BA_ "GenSigSwitchedByIgnition" SG_ 151 BMS_Fehler_Sicherung 0;
BA_ "GenSigSendType" SG_ 151 BMS_Fehler_Sicherung 0;
BA_ "GenSigSwitchedByIgnition" SG_ 151 BMS_Status_ServiceDisconnect 0;
BA_ "GenSigSendType" SG_ 151 BMS_Status_ServiceDisconnect 0;
BA_ "Fehlerwert" SG_ 151 BMS_Status_Spannungsfreiheit 1;
BA_ "GenSigSwitchedByIgnition" SG_ 151 BMS_Status_Spannungsfreiheit 0;
BA_ "GenSigSendType" SG_ 151 BMS_Status_Spannungsfreiheit 0;
BA_ "GenSigSwitchedByIgnition" SG_ 151 BMS_Notfallkuehlung 0;
BA_ "GenSigSendType" SG_ 151 BMS_Notfallkuehlung 0;
BA_ "GenSigSwitchedByIgnition" SG_ 938 BMS_HYB_03_CHK 0;
BA_ "GenSigFuncType" SG_ 938 BMS_HYB_03_CHK 4;
BA_ "GenSigSendType" SG_ 938 BMS_HYB_03_CHK 0;
BA_ "GenSigSwitchedByIgnition" SG_ 938 BMS_HYB_03_BZ 0;
BA_ "GenSigFuncType" SG_ 938 BMS_HYB_03_BZ 1;
BA_ "GenSigSendType" SG_ 938 BMS_HYB_03_BZ 0;
BA_ "GenSigSwitchedByIgnition" SG_ 938 BMS_MaxPred_LadeStrom 0;
BA_ "GenSigStartValue" SG_ 938 BMS_MaxPred_LadeStrom 1023;
BA_ "GenSigSendType" SG_ 938 BMS_MaxPred_LadeStrom 0;
BA_ "GenSigSwitchedByIgnition" SG_ 938 BMS_MaxPred_EntladeStrom 0;
BA_ "GenSigStartValue" SG_ 938 BMS_MaxPred_EntladeStrom 1023;
BA_ "GenSigSendType" SG_ 938 BMS_MaxPred_EntladeStrom 0;
BA_ "GenSigSwitchedByIgnition" SG_ 938 BMS_MinPred_LadeSpannung 0;
BA_ "GenSigStartValue" SG_ 938 BMS_MinPred_LadeSpannung 1023;
BA_ "GenSigSendType" SG_ 938 BMS_MinPred_LadeSpannung 0;
BA_ "GenSigSwitchedByIgnition" SG_ 938 BMS_MinPred_EntladeSpannung 0;
BA_ "GenSigStartValue" SG_ 938 BMS_MinPred_EntladeSpannung 1023;
BA_ "GenSigSendType" SG_ 938 BMS_MinPred_EntladeSpannung 0;
BA_ "Fehlerwert" SG_ 938 BMS_BattLuefterGeschw_rel 15;
BA_ "GenSigSwitchedByIgnition" SG_ 938 BMS_BattLuefterGeschw_rel 0;
BA_ "GenSigStartValue" SG_ 938 BMS_BattLuefterGeschw_rel 14;
BA_ "GenSigSendType" SG_ 938 BMS_BattLuefterGeschw_rel 0;
BA_ "Fehlerwert" SG_ 938 BMS_SOC 255;
BA_ "GenSigSwitchedByIgnition" SG_ 938 BMS_SOC 0;
BA_ "GenSigStartValue" SG_ 938 BMS_SOC 254;
BA_ "GenSigSendType" SG_ 938 BMS_SOC 0;
BA_ "GenSigSwitchedByIgnition" SG_ 292 BMS_HYB_04_CHK 0;
BA_ "GenSigFuncType" SG_ 292 BMS_HYB_04_CHK 4;
BA_ "GenSigSendType" SG_ 292 BMS_HYB_04_CHK 0;
BA_ "GenSigSwitchedByIgnition" SG_ 292 BMS_HYB_04_BZ 0;
BA_ "GenSigFuncType" SG_ 292 BMS_HYB_04_BZ 1;
BA_ "GenSigSendType" SG_ 292 BMS_HYB_04_BZ 0;
BA_ "GenSigSwitchedByIgnition" SG_ 292 BMS_MinDyn_LadeSpannung 0;
BA_ "GenSigStartValue" SG_ 292 BMS_MinDyn_LadeSpannung 1023;
BA_ "GenSigSendType" SG_ 292 BMS_MinDyn_LadeSpannung 0;
BA_ "GenSigSwitchedByIgnition" SG_ 292 BMS_MinDyn_EntladeSpannung 0;
BA_ "GenSigStartValue" SG_ 292 BMS_MinDyn_EntladeSpannung 1023;
BA_ "GenSigSendType" SG_ 292 BMS_MinDyn_EntladeSpannung 0;
BA_ "GenSigSwitchedByIgnition" SG_ 292 BMS_MaxDyn_EntladeStrom 0;
BA_ "GenSigStartValue" SG_ 292 BMS_MaxDyn_EntladeStrom 1023;
BA_ "GenSigSendType" SG_ 292 BMS_MaxDyn_EntladeStrom 0;
BA_ "GenSigSwitchedByIgnition" SG_ 292 BMS_MaxDyn_LadeStrom 0;
BA_ "GenSigStartValue" SG_ 292 BMS_MaxDyn_LadeStrom 1023;
BA_ "GenSigSendType" SG_ 292 BMS_MaxDyn_LadeStrom 0;
BA_ "GenSigSwitchedByIgnition" SG_ 292 BMS_ErwGrenzen_aktiv 0;
BA_ "GenSigSendType" SG_ 292 BMS_ErwGrenzen_aktiv 0;
BA_ "Fehlerwert" SG_ 292 BMS_Spannung_ZwKr 2047;
BA_ "GenSigSwitchedByIgnition" SG_ 292 BMS_Spannung_ZwKr 0;
BA_ "GenSigStartValue" SG_ 292 BMS_Spannung_ZwKr 2046;
BA_ "GenSigSendType" SG_ 292 BMS_Spannung_ZwKr 0;
BA_ "GenSigSwitchedByIgnition" SG_ 1699 BMS_HYB_06_CHK 0;
BA_ "GenSigFuncType" SG_ 1699 BMS_HYB_06_CHK 4;
BA_ "GenSigSendType" SG_ 1699 BMS_HYB_06_CHK 0;
BA_ "GenSigSwitchedByIgnition" SG_ 1699 BMS_HYB_06_BZ 0;
BA_ "GenSigFuncType" SG_ 1699 BMS_HYB_06_BZ 1;
BA_ "GenSigSendType" SG_ 1699 BMS_HYB_06_BZ 0;
BA_ "Fehlerwert" SG_ 1699 BMS_Max_LadeSpannung 1023;
BA_ "GenSigSwitchedByIgnition" SG_ 1699 BMS_Max_LadeSpannung 0;
BA_ "GenSigStartValue" SG_ 1699 BMS_Max_LadeSpannung 1022;
BA_ "GenSigSendType" SG_ 1699 BMS_Max_LadeSpannung 0;
BA_ "Fehlerwert" SG_ 1699 BMS_Min_EntladeSpannung 1023;
BA_ "GenSigSwitchedByIgnition" SG_ 1699 BMS_Min_EntladeSpannung 0;
BA_ "GenSigStartValue" SG_ 1699 BMS_Min_EntladeSpannung 1022;
BA_ "GenSigSendType" SG_ 1699 BMS_Min_EntladeSpannung 0;
BA_ "Fehlerwert" SG_ 1699 BMS_Temperatur 255;
BA_ "GenSigSwitchedByIgnition" SG_ 1699 BMS_Temperatur 0;
BA_ "GenSigStartValue" SG_ 1699 BMS_Temperatur 254;
BA_ "GenSigSendType" SG_ 1699 BMS_Temperatur 0;
BA_ "Fehlerwert" SG_ 1699 BMS_Temperatur_Ansaugluft 255;
BA_ "GenSigSwitchedByIgnition" SG_ 1699 BMS_Temperatur_Ansaugluft 0;
BA_ "GenSigStartValue" SG_ 1699 BMS_Temperatur_Ansaugluft 254;
BA_ "GenSigSendType" SG_ 1699 BMS_Temperatur_Ansaugluft 0;
BA_ "GenSigSwitchedByIgnition" SG_ 1699 BMS_Ausgleichsladung_Anf 0;
BA_ "GenSigSendType" SG_ 1699 BMS_Ausgleichsladung_Anf 0;
BA_ "GenSigSwitchedByIgnition" SG_ 1699 BMS_Umluftklappe_Anf 0;
BA_ "GenSigSendType" SG_ 1699 BMS_Umluftklappe_Anf 0;
BA_ "GenSigSwitchedByIgnition" SG_ 1699 BMS_OBD_Lampe_Anf 0;
BA_ "GenSigSendType" SG_ 1699 BMS_OBD_Lampe_Anf 0;
BA_ "GenSigSwitchedByIgnition" SG_ 1699 BMS_Warnlampe_Anf 0;
BA_ "GenSigSendType" SG_ 1699 BMS_Warnlampe_Anf 0;
BA_ "GenSigSwitchedByIgnition" SG_ 1699 BMS_Fehlerlampe_Anf 0;
BA_ "GenSigSendType" SG_ 1699 BMS_Fehlerlampe_Anf 0;
BA_ "GenSigSwitchedByIgnition" SG_ 1699 BMS_Balancing_Anf 0;
BA_ "GenSigSendType" SG_ 1699 BMS_Balancing_Anf 0;
BA_ "Fehlerwert" SG_ 1723 BMS_Energieinhalt 2047;
BA_ "GenSigSwitchedByIgnition" SG_ 1723 BMS_Energieinhalt 0;
BA_ "GenSigStartValue" SG_ 1723 BMS_Energieinhalt 2046;
BA_ "GenSigSendType" SG_ 1723 BMS_Energieinhalt 0;
BA_ "GenSigSwitchedByIgnition" SG_ 1723 BMS_Kapazitaet 0;
BA_ "GenSigStartValue" SG_ 1723 BMS_Kapazitaet 2047;
BA_ "GenSigSendType" SG_ 1723 BMS_Kapazitaet 0;
BA_ "GenSigSwitchedByIgnition" SG_ 1723 BMS_Temperierung_Anf 0;
BA_ "GenSigStartValue" SG_ 1723 BMS_Temperierung_Anf 3;
BA_ "GenSigSendType" SG_ 1723 BMS_Temperierung_Anf 0;
BA_ "GenSigSwitchedByIgnition" SG_ 1723 BMS_min_Grenz_SOC 0;
BA_ "GenSigStartValue" SG_ 1723 BMS_min_Grenz_SOC 31;
BA_ "GenSigSendType" SG_ 1723 BMS_min_Grenz_SOC 0;
BA_ "GenSigSwitchedByIgnition" SG_ 1723 BMS_max_Grenz_SOC 0;
BA_ "GenSigStartValue" SG_ 1723 BMS_max_Grenz_SOC 31;
BA_ "GenSigSendType" SG_ 1723 BMS_max_Grenz_SOC 0;
BA_ "Fehlerwert" SG_ 1723 BMS_MaxEnergieinhalt 2047;
BA_ "GenSigSwitchedByIgnition" SG_ 1723 BMS_MaxEnergieinhalt 0;
BA_ "GenSigStartValue" SG_ 1723 BMS_MaxEnergieinhalt 2046;
BA_ "GenSigSendType" SG_ 1723 BMS_MaxEnergieinhalt 0;
BA_ "GenSigSwitchedByIgnition" SG_ 1723 BMS_Zeitbedarf_Balancing 0;
BA_ "GenSigStartValue" SG_ 1723 BMS_Zeitbedarf_Balancing 254;
BA_ "GenSigSendType" SG_ 1723 BMS_Zeitbedarf_Balancing 0;
BA_ "GenSigSwitchedByIgnition" SG_ 1161 BMS_Status_DCLS 0;
BA_ "GenSigSendType" SG_ 1161 BMS_Status_DCLS 0;
BA_ "Fehlerwert" SG_ 1161 BMS_DCLS_Spannung 1023;
BA_ "GenSigSwitchedByIgnition" SG_ 1161 BMS_DCLS_Spannung 0;
BA_ "GenSigStartValue" SG_ 1161 BMS_DCLS_Spannung 1022;
BA_ "GenSigSendType" SG_ 1161 BMS_DCLS_Spannung 0;
BA_ "Fehlerwert" SG_ 1161 BMS_HVBatt_Perf_Ind 255;
BA_ "GenSigSwitchedByIgnition" SG_ 1161 BMS_HVBatt_Perf_Ind 0;
BA_ "GenSigStartValue" SG_ 1161 BMS_HVBatt_Perf_Ind 254;
BA_ "GenSigSendType" SG_ 1161 BMS_HVBatt_Perf_Ind 0;
BA_ "Fehlerwert" SG_ 1161 BMS_SOC_HiRes 2047;
BA_ "GenSigSwitchedByIgnition" SG_ 1161 BMS_SOC_HiRes 0;
BA_ "GenSigStartValue" SG_ 1161 BMS_SOC_HiRes 2046;
BA_ "GenSigSendType" SG_ 1161 BMS_SOC_HiRes 0;
BA_ "Fehlerwert" SG_ 1161 BMS_HV_Deaktivierungsmodus 3;
BA_ "GenSigSwitchedByIgnition" SG_ 1161 BMS_HV_Deaktivierungsmodus 0;
BA_ "Fehlerwert" SG_ 1161 BMS_Anf_Mo_Luefter 255;
BA_ "GenSigSwitchedByIgnition" SG_ 1161 BMS_Anf_Mo_Luefter 0;
BA_ "GenSigStartValue" SG_ 1161 BMS_Anf_Mo_Luefter 254;
BA_ "GenSigSendType" SG_ 1161 BMS_Anf_Mo_Luefter 0;
BA_ "GenSigSwitchedByIgnition" SG_ 2617236992 CCP_BMS_CRO_01_Data 0;
BA_ "GenSigFuncType" SG_ 2617236992 CCP_BMS_CRO_01_Data 9;
BA_ "GenSigSendType" SG_ 2617236992 CCP_BMS_CRO_01_Data 1;
BA_ "GenSigSwitchedByIgnition" SG_ 2281692672 CCP_BMS_CRO_02_Data 0;
BA_ "GenSigFuncType" SG_ 2281692672 CCP_BMS_CRO_02_Data 9;
BA_ "GenSigSendType" SG_ 2281692672 CCP_BMS_CRO_02_Data 1;
BA_ "GenSigSwitchedByIgnition" SG_ 2617236993 CCP_BMS_DTO_01_Data 0;
BA_ "GenSigFuncType" SG_ 2617236993 CCP_BMS_DTO_01_Data 9;
BA_ "GenSigSendType" SG_ 2617236993 CCP_BMS_DTO_01_Data 1;
BA_ "GenSigSwitchedByIgnition" SG_ 2281692673 CCP_BMS_DTO_02_Data 0;
BA_ "GenSigFuncType" SG_ 2281692673 CCP_BMS_DTO_02_Data 9;
BA_ "GenSigSendType" SG_ 2281692673 CCP_BMS_DTO_02_Data 1;
BA_ "GenSigSwitchedByIgnition" SG_ 2617239041 CCP_LE_DTO_01_Data 0;
BA_ "GenSigSendType" SG_ 2617239041 CCP_LE_DTO_01_Data 1;
BA_ "GenSigSwitchedByIgnition" SG_ 2566690560 CCP_GPM_CRO_01_Data 0;
BA_ "GenSigSendType" SG_ 2566690560 CCP_GPM_CRO_01_Data 1;
BA_ "GenSigSwitchedByIgnition" SG_ 2566690561 CCP_GPM_DTO_01_Data 0;
BA_ "GenSigSendType" SG_ 2566690561 CCP_GPM_DTO_01_Data 1;
BA_ "GenSigSwitchedByIgnition" SG_ 2617124352 CCP_Ladegeraet_CRO_01_Data 0;
BA_ "GenSigFuncType" SG_ 2617124352 CCP_Ladegeraet_CRO_01_Data 9;
BA_ "GenSigSendType" SG_ 2617124352 CCP_Ladegeraet_CRO_01_Data 1;
BA_ "GenSigSwitchedByIgnition" SG_ 2617124353 CCP_Ladegeraet_DTO_01_Data 0;
BA_ "GenSigFuncType" SG_ 2617124353 CCP_Ladegeraet_DTO_01_Data 9;
BA_ "GenSigSendType" SG_ 2617124353 CCP_Ladegeraet_DTO_01_Data 1;
BA_ "GenSigSwitchedByIgnition" SG_ 1666 CCP_LE_CRO_01_Data 0;
BA_ "GenSigSendType" SG_ 1666 CCP_LE_CRO_01_Data 1;
BA_ "GenSigSwitchedByIgnition" SG_ 127 CCU_HYB_01_CHK 0;
BA_ "GenSigFuncType" SG_ 127 CCU_HYB_01_CHK 4;
BA_ "GenSigSendType" SG_ 127 CCU_HYB_01_CHK 0;
BA_ "GenSigSwitchedByIgnition" SG_ 127 CCU_HYB_01_BZ 0;
BA_ "GenSigFuncType" SG_ 127 CCU_HYB_01_BZ 1;
BA_ "GenSigSendType" SG_ 127 CCU_HYB_01_BZ 0;
BA_ "Fehlerwert" SG_ 127 CCU_Strom_momentbildend 4095;
BA_ "GenSigSwitchedByIgnition" SG_ 127 CCU_Strom_momentbildend 0;
BA_ "GenSigStartValue" SG_ 127 CCU_Strom_momentbildend 4094;
BA_ "GenSigSendType" SG_ 127 CCU_Strom_momentbildend 0;
BA_ "Fehlerwert" SG_ 127 CCU_IstWinkelGeschw 511;
BA_ "GenSigSwitchedByIgnition" SG_ 127 CCU_IstWinkelGeschw 0;
BA_ "GenSigStartValue" SG_ 127 CCU_IstWinkelGeschw 510;
BA_ "GenSigSendType" SG_ 127 CCU_IstWinkelGeschw 0;
BA_ "GenSigSwitchedByIgnition" SG_ 127 CCU_Fehler_HW 0;
BA_ "GenSigSendType" SG_ 127 CCU_Fehler_HW 0;
BA_ "GenSigSwitchedByIgnition" SG_ 127 CCU_Fehler_mechanisch 0;
BA_ "GenSigSendType" SG_ 127 CCU_Fehler_mechanisch 0;
BA_ "GenSigSwitchedByIgnition" SG_ 127 CCU_Fehler_CAN 0;
BA_ "GenSigSendType" SG_ 127 CCU_Fehler_CAN 0;
BA_ "GenSigSwitchedByIgnition" SG_ 127 CCU_Fehler_Unterspannung 0;
BA_ "GenSigSendType" SG_ 127 CCU_Fehler_Unterspannung 0;
BA_ "GenSigSwitchedByIgnition" SG_ 127 CCU_Warnung_Temperatur 0;
BA_ "GenSigSendType" SG_ 127 CCU_Warnung_Temperatur 0;
BA_ "GenSigSwitchedByIgnition" SG_ 127 CCU_Fehler_Temperatur 0;
BA_ "GenSigSendType" SG_ 127 CCU_Fehler_Temperatur 0;
BA_ "GenSigSwitchedByIgnition" SG_ 127 CCU_SleepInd 0;
BA_ "GenSigSendType" SG_ 127 CCU_SleepInd 0;
BA_ "Fehlerwert" SG_ 127 CCU_IstPosition 8191;
BA_ "GenSigSwitchedByIgnition" SG_ 127 CCU_IstPosition 0;
BA_ "GenSigStartValue" SG_ 127 CCU_IstPosition 8190;
BA_ "GenSigSendType" SG_ 127 CCU_IstPosition 0;
BA_ "GenSigSwitchedByIgnition" SG_ 127 CCU_Istmodus 0;
BA_ "GenSigStartValue" SG_ 127 CCU_Istmodus 7;
BA_ "GenSigSendType" SG_ 127 CCU_Istmodus 0;
BA_ "Fehlerwert" SG_ 127 CCU_IstDruck 255;
BA_ "GenSigSwitchedByIgnition" SG_ 127 CCU_IstDruck 0;
BA_ "GenSigStartValue" SG_ 127 CCU_IstDruck 254;
BA_ "GenSigSendType" SG_ 127 CCU_IstDruck 0;
BA_ "GenSigSwitchedByIgnition" SG_ 1715 CCU_HYB_02_CHK 0;
BA_ "GenSigFuncType" SG_ 1715 CCU_HYB_02_CHK 4;
BA_ "GenSigSwitchedByIgnition" SG_ 1715 CCU_HYB_02_BZ 0;
BA_ "GenSigFuncType" SG_ 1715 CCU_HYB_02_BZ 1;
BA_ "GenSigSwitchedByIgnition" SG_ 1715 CCU_Medium 0;
BA_ "GenSigSendType" SG_ 1715 CCU_Medium 1;
BA_ "GenSigSwitchedByIgnition" SG_ 1715 CCU_HW_Version 0;
BA_ "GenSigSendType" SG_ 1715 CCU_HW_Version 1;
BA_ "GenSigSwitchedByIgnition" SG_ 1715 CCU_SW_Version 0;
BA_ "GenSigSendType" SG_ 1715 CCU_SW_Version 1;
BA_ "GenSigSwitchedByIgnition" SG_ 1715 CCU_Seriennummer 0;
BA_ "GenSigSendType" SG_ 1715 CCU_Seriennummer 1;
BA_ "GenSigSwitchedByIgnition" SG_ 1715 CCU_Teilenummer 0;
BA_ "GenSigSendType" SG_ 1715 CCU_Teilenummer 1;
BA_ "GenSigSwitchedByIgnition" SG_ 156 DC_HYB_01_CHK 0;
BA_ "GenSigFuncType" SG_ 156 DC_HYB_01_CHK 4;
BA_ "GenSigSendType" SG_ 156 DC_HYB_01_CHK 0;
BA_ "GenSigSwitchedByIgnition" SG_ 156 DC_HYB_01_BZ 0;
BA_ "GenSigFuncType" SG_ 156 DC_HYB_01_BZ 1;
BA_ "GenSigSendType" SG_ 156 DC_HYB_01_BZ 0;
BA_ "Fehlerwert" SG_ 156 DC_IstSpannung_HV 4095;
BA_ "GenSigSwitchedByIgnition" SG_ 156 DC_IstSpannung_HV 0;
BA_ "GenSigStartValue" SG_ 156 DC_IstSpannung_HV 4094;
BA_ "GenSigSendType" SG_ 156 DC_IstSpannung_HV 0;
BA_ "Fehlerwert" SG_ 156 DC_IstStrom_HV 1023;
BA_ "GenSigSwitchedByIgnition" SG_ 156 DC_IstStrom_HV 0;
BA_ "GenSigStartValue" SG_ 156 DC_IstStrom_HV 1022;
BA_ "GenSigSendType" SG_ 156 DC_IstStrom_HV 0;
BA_ "GenSigSwitchedByIgnition" SG_ 156 DC_IstModus 0;
BA_ "GenSigStartValue" SG_ 156 DC_IstModus 7;
BA_ "GenSigSendType" SG_ 156 DC_IstModus 0;
BA_ "GenSigSwitchedByIgnition" SG_ 156 DC_LangsRegelung_aktiv 0;
BA_ "GenSigSendType" SG_ 156 DC_LangsRegelung_aktiv 0;
BA_ "GenSigSwitchedByIgnition" SG_ 156 DC_SleepInd 0;
BA_ "GenSigSendType" SG_ 156 DC_SleepInd 0;
BA_ "GenSigSwitchedByIgnition" SG_ 156 DC_Fehler_intern 0;
BA_ "GenSigSendType" SG_ 156 DC_Fehler_intern 0;
BA_ "GenSigSwitchedByIgnition" SG_ 156 DC_Fehler_Leistungsred 0;
BA_ "GenSigSendType" SG_ 156 DC_Fehler_Leistungsred 0;
BA_ "GenSigSwitchedByIgnition" SG_ 156 DC_Fehler_Spannung 0;
BA_ "GenSigSendType" SG_ 156 DC_Fehler_Spannung 0;
BA_ "GenSigSwitchedByIgnition" SG_ 156 DC_Verbrauch 0;
BA_ "GenSigSendType" SG_ 156 DC_Verbrauch 0;
BA_ "GenSigSwitchedByIgnition" SG_ 156 DC_Verbrauch_Ueberlauf 0;
BA_ "GenSigSendType" SG_ 156 DC_Verbrauch_Ueberlauf 0;
BA_ "GenSigSwitchedByIgnition" SG_ 943 DC_HYB_02_CHK 0;
BA_ "GenSigFuncType" SG_ 943 DC_HYB_02_CHK 4;
BA_ "GenSigSendType" SG_ 943 DC_HYB_02_CHK 0;
BA_ "GenSigSwitchedByIgnition" SG_ 943 DC_HYB_02_BZ 0;
BA_ "GenSigFuncType" SG_ 943 DC_HYB_02_BZ 1;
BA_ "GenSigSendType" SG_ 943 DC_HYB_02_BZ 0;
BA_ "Fehlerwert" SG_ 943 DC_IstSpannung_NV 255;
BA_ "GenSigSwitchedByIgnition" SG_ 943 DC_IstSpannung_NV 0;
BA_ "GenSigStartValue" SG_ 943 DC_IstSpannung_NV 254;
BA_ "GenSigSendType" SG_ 943 DC_IstSpannung_NV 0;
BA_ "Fehlerwert" SG_ 943 DC_IstStrom_NV 1023;
BA_ "GenSigSwitchedByIgnition" SG_ 943 DC_IstStrom_NV 0;
BA_ "GenSigStartValue" SG_ 943 DC_IstStrom_NV 1022;
BA_ "GenSigSendType" SG_ 943 DC_IstStrom_NV 0;
BA_ "GenSigSwitchedByIgnition" SG_ 943 DC_IdentifikationsNr 0;
BA_ "GenSigSendType" SG_ 943 DC_IdentifikationsNr 0;
BA_ "Fehlerwert" SG_ 943 DC_Temperatur 255;
BA_ "GenSigSwitchedByIgnition" SG_ 943 DC_Temperatur 0;
BA_ "GenSigStartValue" SG_ 943 DC_Temperatur 254;
BA_ "GenSigSendType" SG_ 943 DC_Temperatur 0;
BA_ "GenSigSwitchedByIgnition" SG_ 943 DC_Auslastungsgrad 0;
BA_ "GenSigSendType" SG_ 943 DC_Auslastungsgrad 0;
BA_ "GenSigSwitchedByIgnition" SG_ 943 DC_Abregelung_StromLim_HV 0;
BA_ "GenSigSendType" SG_ 943 DC_Abregelung_StromLim_HV 0;
BA_ "GenSigSwitchedByIgnition" SG_ 943 DC_Abregelung_StromLim_NV 0;
BA_ "GenSigSendType" SG_ 943 DC_Abregelung_StromLim_NV 0;
BA_ "GenSigSwitchedByIgnition" SG_ 943 DC_Abregelung_SpannungLim_HV 0;
BA_ "GenSigSendType" SG_ 943 DC_Abregelung_SpannungLim_HV 0;
BA_ "GenSigSwitchedByIgnition" SG_ 943 DC_Abregelung_SpannungLim_NV 0;
BA_ "GenSigSendType" SG_ 943 DC_Abregelung_SpannungLim_NV 0;
BA_ "GenSigSwitchedByIgnition" SG_ 943 DC_Abregelung_Temperatur 0;
BA_ "GenSigSendType" SG_ 943 DC_Abregelung_Temperatur 0;
BA_ "GenSigSwitchedByIgnition" SG_ 2617235968 DEV_BMS_Resp_00_Data 0;
BA_ "GenSigSendType" SG_ 2617235968 DEV_BMS_Resp_00_Data 1;
BA_ "GenSigSwitchedByIgnition" SG_ 2617235969 DEV_BMS_Resp_01_Data 0;
BA_ "GenSigSendType" SG_ 2617235969 DEV_BMS_Resp_01_Data 1;
BA_ "GenSigSwitchedByIgnition" SG_ 2617235970 DEV_BMS_Resp_02_Data 0;
BA_ "GenSigSendType" SG_ 2617235970 DEV_BMS_Resp_02_Data 1;
BA_ "GenSigSwitchedByIgnition" SG_ 2617235971 DEV_BMS_Resp_03_Data 0;
BA_ "GenSigSendType" SG_ 2617235971 DEV_BMS_Resp_03_Data 1;
BA_ "GenSigSwitchedByIgnition" SG_ 2617235972 DEV_BMS_Resp_04_Data 0;
BA_ "GenSigSendType" SG_ 2617235972 DEV_BMS_Resp_04_Data 1;
BA_ "GenSigSwitchedByIgnition" SG_ 2617235973 DEV_BMS_Resp_05_Data 0;
BA_ "GenSigSendType" SG_ 2617235973 DEV_BMS_Resp_05_Data 1;
BA_ "GenSigSwitchedByIgnition" SG_ 2617235974 DEV_BMS_Resp_06_Data 0;
BA_ "GenSigSendType" SG_ 2617235974 DEV_BMS_Resp_06_Data 1;
BA_ "GenSigSwitchedByIgnition" SG_ 2617235975 DEV_BMS_Resp_07_Data 0;
BA_ "GenSigSendType" SG_ 2617235975 DEV_BMS_Resp_07_Data 1;
BA_ "GenSigSwitchedByIgnition" SG_ 2566821632 DEV_GPM_Func_Req_Data 0;
BA_ "GenSigFuncType" SG_ 2566821632 DEV_GPM_Func_Req_Data 9;
BA_ "GenSigSendType" SG_ 2566821632 DEV_GPM_Func_Req_Data 1;
BA_ "GenSigSwitchedByIgnition" SG_ 2566821633 DEV_GPM_Req_01_Data 0;
BA_ "GenSigFuncType" SG_ 2566821633 DEV_GPM_Req_01_Data 9;
BA_ "GenSigSendType" SG_ 2566821633 DEV_GPM_Req_01_Data 1;
BA_ "GenSigSwitchedByIgnition" SG_ 2566821634 DEV_GPM_Resp_01_Data 0;
BA_ "GenSigFuncType" SG_ 2566821634 DEV_GPM_Resp_01_Data 9;
BA_ "GenSigSendType" SG_ 2566821634 DEV_GPM_Resp_01_Data 1;
BA_ "GenSigSwitchedByIgnition" SG_ 2617123328 DEV_Ladegeraet_Req_01_Data 0;
BA_ "GenSigFuncType" SG_ 2617123328 DEV_Ladegeraet_Req_01_Data 9;
BA_ "GenSigSendType" SG_ 2617123328 DEV_Ladegeraet_Req_01_Data 1;
BA_ "GenSigSwitchedByIgnition" SG_ 2617123329 DEV_Ladegeraet_Resp_01_Data 0;
BA_ "GenSigFuncType" SG_ 2617123329 DEV_Ladegeraet_Resp_01_Data 9;
BA_ "GenSigSendType" SG_ 2617123329 DEV_Ladegeraet_Resp_01_Data 1;
BA_ "GenSigSwitchedByIgnition" SG_ 2617123330 DEV_Ladegeraet_Resp_02_Data 0;
BA_ "GenSigFuncType" SG_ 2617123330 DEV_Ladegeraet_Resp_02_Data 9;
BA_ "GenSigSendType" SG_ 2617123330 DEV_Ladegeraet_Resp_02_Data 1;
BA_ "GenSigSwitchedByIgnition" SG_ 2617123331 DEV_Ladegeraet_Resp_03_Data 0;
BA_ "GenSigFuncType" SG_ 2617123331 DEV_Ladegeraet_Resp_03_Data 9;
BA_ "GenSigSendType" SG_ 2617123331 DEV_Ladegeraet_Resp_03_Data 1;
BA_ "GenSigSwitchedByIgnition" SG_ 2617123332 DEV_Ladegeraet_Resp_04_Data 0;
BA_ "GenSigFuncType" SG_ 2617123332 DEV_Ladegeraet_Resp_04_Data 9;
BA_ "GenSigSendType" SG_ 2617123332 DEV_Ladegeraet_Resp_04_Data 1;
BA_ "GenSigSwitchedByIgnition" SG_ 2617123333 DEV_Ladegeraet_Resp_05_Data 0;
BA_ "GenSigFuncType" SG_ 2617123333 DEV_Ladegeraet_Resp_05_Data 9;
BA_ "GenSigSendType" SG_ 2617123333 DEV_Ladegeraet_Resp_05_Data 1;
BA_ "GenSigSwitchedByIgnition" SG_ 2617123334 DEV_Ladegeraet_Resp_06_Data 0;
BA_ "GenSigFuncType" SG_ 2617123334 DEV_Ladegeraet_Resp_06_Data 9;
BA_ "GenSigSendType" SG_ 2617123334 DEV_Ladegeraet_Resp_06_Data 1;
BA_ "GenSigSwitchedByIgnition" SG_ 152 EM_HYB_02_CHK 0;
BA_ "GenSigFuncType" SG_ 152 EM_HYB_02_CHK 4;
BA_ "GenSigSendType" SG_ 152 EM_HYB_02_CHK 0;
BA_ "GenSigSwitchedByIgnition" SG_ 152 EM_HYB_02_BZ 0;
BA_ "GenSigFuncType" SG_ 152 EM_HYB_02_BZ 1;
BA_ "GenSigSendType" SG_ 152 EM_HYB_02_BZ 0;
BA_ "Fehlerwert" SG_ 152 EM_IstMoment 4095;
BA_ "GenSigSwitchedByIgnition" SG_ 152 EM_IstMoment 0;
BA_ "GenSigStartValue" SG_ 152 EM_IstMoment 4094;
BA_ "GenSigSendType" SG_ 152 EM_IstMoment 0;
BA_ "Fehlerwert" SG_ 152 EM_IstMoment_ohneAR 4095;
BA_ "GenSigSwitchedByIgnition" SG_ 152 EM_IstMoment_ohneAR 0;
BA_ "GenSigStartValue" SG_ 152 EM_IstMoment_ohneAR 4094;
BA_ "GenSigSendType" SG_ 152 EM_IstMoment_ohneAR 0;
BA_ "Fehlerwert" SG_ 152 EM_IstDrehzahl 65535;
BA_ "GenSigSwitchedByIgnition" SG_ 152 EM_IstDrehzahl 0;
BA_ "GenSigStartValue" SG_ 152 EM_IstDrehzahl 65534;
BA_ "GenSigSendType" SG_ 152 EM_IstDrehzahl 0;
BA_ "GenSigSwitchedByIgnition" SG_ 152 EM_Status_Spannungsfreiheit 0;
BA_ "GenSigSendType" SG_ 152 EM_Status_Spannungsfreiheit 0;
BA_ "GenSigSwitchedByIgnition" SG_ 152 EM_AR_aktiv 0;
BA_ "GenSigSendType" SG_ 152 EM_AR_aktiv 0;
BA_ "GenSigSwitchedByIgnition" SG_ 152 EM_Fehler_Notabschaltung_HVIL 0;
BA_ "GenSigSwitchedByIgnition" SG_ 939 EM_HYB_03_CHK 0;
BA_ "GenSigFuncType" SG_ 939 EM_HYB_03_CHK 4;
BA_ "GenSigSendType" SG_ 939 EM_HYB_03_CHK 0;
BA_ "GenSigSwitchedByIgnition" SG_ 939 EM_HYB_03_BZ 0;
BA_ "GenSigFuncType" SG_ 939 EM_HYB_03_BZ 1;
BA_ "GenSigSendType" SG_ 939 EM_HYB_03_BZ 0;
BA_ "Fehlerwert" SG_ 939 EM_IstSpannung 4095;
BA_ "GenSigSwitchedByIgnition" SG_ 939 EM_IstSpannung 0;
BA_ "GenSigStartValue" SG_ 939 EM_IstSpannung 4094;
BA_ "GenSigSendType" SG_ 939 EM_IstSpannung 0;
BA_ "Fehlerwert" SG_ 939 EM_IstStrom 4095;
BA_ "GenSigSwitchedByIgnition" SG_ 939 EM_IstStrom 0;
BA_ "GenSigStartValue" SG_ 939 EM_IstStrom 4094;
BA_ "GenSigSendType" SG_ 939 EM_IstStrom 0;
BA_ "GenSigSwitchedByIgnition" SG_ 939 EM_Abregelung_Temperatur 0;
BA_ "GenSigSendType" SG_ 939 EM_Abregelung_Temperatur 3;
BA_ "GenSigSwitchedByIgnition" SG_ 939 EM_Abregelung_MaxSpannung 0;
BA_ "GenSigSendType" SG_ 939 EM_Abregelung_MaxSpannung 3;
BA_ "GenSigSwitchedByIgnition" SG_ 939 EM_Abregelung_MinSpannung 0;
BA_ "GenSigSendType" SG_ 939 EM_Abregelung_MinSpannung 3;
BA_ "GenSigSwitchedByIgnition" SG_ 939 EM_Abregelung_MaxStrom 0;
BA_ "GenSigSendType" SG_ 939 EM_Abregelung_MaxStrom 3;
BA_ "GenSigSwitchedByIgnition" SG_ 939 EM_Abregelung_MinStrom 0;
BA_ "GenSigSendType" SG_ 939 EM_Abregelung_MinStrom 3;
BA_ "GenSigSwitchedByIgnition" SG_ 939 EM_Abregelung_MaxMoment 0;
BA_ "GenSigSendType" SG_ 939 EM_Abregelung_MaxMoment 3;
BA_ "GenSigSwitchedByIgnition" SG_ 939 EM_Abregelung_MinMoment 0;
BA_ "GenSigSendType" SG_ 939 EM_Abregelung_MinMoment 3;
BA_ "GenSigSwitchedByIgnition" SG_ 939 EM_AnlernenElMotor_Anf 0;
BA_ "GenSigSendType" SG_ 939 EM_AnlernenElMotor_Anf 3;
BA_ "GenSigSwitchedByIgnition" SG_ 939 EM_Kuehlpumpe_Status 0;
BA_ "GenSigStartValue" SG_ 939 EM_Kuehlpumpe_Status 7;
BA_ "GenSigSendType" SG_ 939 EM_Kuehlpumpe_Status 0;
BA_ "Fehlerwert" SG_ 939 EM_Verlustleistung 255;
BA_ "GenSigSwitchedByIgnition" SG_ 939 EM_Verlustleistung 0;
BA_ "GenSigStartValue" SG_ 939 EM_Verlustleistung 254;
BA_ "GenSigSendType" SG_ 939 EM_Verlustleistung 0;
BA_ "GenSigSwitchedByIgnition" SG_ 939 EM_Freigabe_Verfallsinfo_WFS 0;
BA_ "GenSigSendType" SG_ 939 EM_Freigabe_Verfallsinfo_WFS 0;
BA_ "GenSigSwitchedByIgnition" SG_ 939 EM_Status_Spgfreiheit 0;
BA_ "GenSigSendType" SG_ 939 EM_Status_Spgfreiheit 0;
BA_ "GenSigSwitchedByIgnition" SG_ 940 EM_HYB_04_CHK 0;
BA_ "GenSigFuncType" SG_ 940 EM_HYB_04_CHK 4;
BA_ "GenSigSendType" SG_ 940 EM_HYB_04_CHK 0;
BA_ "GenSigSwitchedByIgnition" SG_ 940 EM_HYB_04_BZ 0;
BA_ "GenSigFuncType" SG_ 940 EM_HYB_04_BZ 1;
BA_ "GenSigSendType" SG_ 940 EM_HYB_04_BZ 0;
BA_ "GenSigSwitchedByIgnition" SG_ 940 EM_MaxPred_Moment 0;
BA_ "GenSigStartValue" SG_ 940 EM_MaxPred_Moment 1023;
BA_ "GenSigSendType" SG_ 940 EM_MaxPred_Moment 0;
BA_ "GenSigSwitchedByIgnition" SG_ 940 EM_MinPred_Moment 0;
BA_ "GenSigStartValue" SG_ 940 EM_MinPred_Moment 1023;
BA_ "GenSigSendType" SG_ 940 EM_MinPred_Moment 0;
BA_ "GenSigSwitchedByIgnition" SG_ 940 EM_MaxPred_Abknickdrehzahl 0;
BA_ "GenSigStartValue" SG_ 940 EM_MaxPred_Abknickdrehzahl 255;
BA_ "GenSigSendType" SG_ 940 EM_MaxPred_Abknickdrehzahl 0;
BA_ "GenSigSwitchedByIgnition" SG_ 940 EM_MinPred_Abknickdrehzahl 0;
BA_ "GenSigStartValue" SG_ 940 EM_MinPred_Abknickdrehzahl 255;
BA_ "GenSigSendType" SG_ 940 EM_MinPred_Abknickdrehzahl 0;
BA_ "GenSigSwitchedByIgnition" SG_ 940 EM_Moment_HVVerbraucher 0;
BA_ "GenSigStartValue" SG_ 940 EM_Moment_HVVerbraucher 1023;
BA_ "GenSigSendType" SG_ 940 EM_Moment_HVVerbraucher 0;
BA_ "GenSigSwitchedByIgnition" SG_ 1700 EM_HYB_05_CHK 0;
BA_ "GenSigFuncType" SG_ 1700 EM_HYB_05_CHK 4;
BA_ "GenSigSendType" SG_ 1700 EM_HYB_05_CHK 0;
BA_ "GenSigSwitchedByIgnition" SG_ 1700 EM_HYB_05_BZ 0;
BA_ "GenSigFuncType" SG_ 1700 EM_HYB_05_BZ 1;
BA_ "GenSigSendType" SG_ 1700 EM_HYB_05_BZ 0;
BA_ "GenSigSwitchedByIgnition" SG_ 1700 EM_OBD_Lampe_Anf 0;
BA_ "GenSigSendType" SG_ 1700 EM_OBD_Lampe_Anf 0;
BA_ "GenSigSwitchedByIgnition" SG_ 1700 EM_Warnlampe_Anf 0;
BA_ "GenSigSendType" SG_ 1700 EM_Warnlampe_Anf 0;
BA_ "GenSigSwitchedByIgnition" SG_ 1700 EM_Fehlerlampe_Anf 0;
BA_ "GenSigSendType" SG_ 1700 EM_Fehlerlampe_Anf 0;
BA_ "GenSigSwitchedByIgnition" SG_ 1700 EM_Fehler_Pilot 0;
BA_ "GenSigSendType" SG_ 1700 EM_Fehler_Pilot 0;
BA_ "Fehlerwert" SG_ 1700 EM_Temperatur_ElMotor 255;
BA_ "GenSigSwitchedByIgnition" SG_ 1700 EM_Temperatur_ElMotor 0;
BA_ "GenSigStartValue" SG_ 1700 EM_Temperatur_ElMotor 254;
BA_ "GenSigSendType" SG_ 1700 EM_Temperatur_ElMotor 0;
BA_ "Fehlerwert" SG_ 1700 EM_Temperatur_PWR 255;
BA_ "GenSigSwitchedByIgnition" SG_ 1700 EM_Temperatur_PWR 0;
BA_ "GenSigStartValue" SG_ 1700 EM_Temperatur_PWR 254;
BA_ "GenSigSendType" SG_ 1700 EM_Temperatur_PWR 0;
BA_ "Fehlerwert" SG_ 1700 EM_Temperatur_Rotor 255;
BA_ "GenSigSwitchedByIgnition" SG_ 1700 EM_Temperatur_Rotor 0;
BA_ "GenSigStartValue" SG_ 1700 EM_Temperatur_Rotor 254;
BA_ "GenSigSendType" SG_ 1700 EM_Temperatur_Rotor 0;
BA_ "GenSigSwitchedByIgnition" SG_ 1700 EM_HTKreis_Umgehung_Freigabe 0;
BA_ "GenSigSendType" SG_ 1700 EM_HTKreis_Umgehung_Freigabe 0;
BA_ "GenSigSwitchedByIgnition" SG_ 153 EM_HYB_06_CHK 0;
BA_ "GenSigFuncType" SG_ 153 EM_HYB_06_CHK 4;
BA_ "GenSigSendType" SG_ 153 EM_HYB_06_CHK 0;
BA_ "GenSigSwitchedByIgnition" SG_ 153 EM_HYB_06_BZ 0;
BA_ "GenSigFuncType" SG_ 153 EM_HYB_06_BZ 1;
BA_ "GenSigSendType" SG_ 153 EM_HYB_06_BZ 0;
BA_ "GenSigSwitchedByIgnition" SG_ 153 EM_Istmodus 0;
BA_ "GenSigStartValue" SG_ 153 EM_Istmodus 15;
BA_ "GenSigSendType" SG_ 153 EM_Istmodus 0;
BA_ "GenSigSwitchedByIgnition" SG_ 153 EM_HV_betriebsbereit 0;
BA_ "GenSigSendType" SG_ 153 EM_HV_betriebsbereit 0;
BA_ "GenSigSwitchedByIgnition" SG_ 153 EM_SleepInd 0;
BA_ "GenSigSendType" SG_ 153 EM_SleepInd 0;
BA_ "GenSigSwitchedByIgnition" SG_ 153 EM_ErwGrenzen_aktiv 0;
BA_ "GenSigSendType" SG_ 153 EM_ErwGrenzen_aktiv 0;
BA_ "GenSigSwitchedByIgnition" SG_ 153 EM_Init_abgeschlossen 0;
BA_ "GenSigSendType" SG_ 153 EM_Init_abgeschlossen 0;
BA_ "Fehlerwert" SG_ 153 EM_Fehler_ElAntriebAbschaltung 1;
BA_ "GenSigSwitchedByIgnition" SG_ 153 EM_Fehler_ElAntriebAbschaltung 0;
BA_ "GenSigSendType" SG_ 153 EM_Fehler_ElAntriebAbschaltung 0;
BA_ "Fehlerwert" SG_ 153 EM_Fehler_Notabschaltung 1;
BA_ "GenSigSwitchedByIgnition" SG_ 153 EM_Fehler_Notabschaltung 0;
BA_ "GenSigSendType" SG_ 153 EM_Fehler_Notabschaltung 0;
BA_ "GenSigSwitchedByIgnition" SG_ 153 EM_Fehler_Leistungsred 0;
BA_ "GenSigSendType" SG_ 153 EM_Fehler_Leistungsred 0;
BA_ "Fehlerwert" SG_ 153 EM_Fehler_ElAntriebFreilauf 1;
BA_ "GenSigSwitchedByIgnition" SG_ 153 EM_Fehler_ElAntriebFreilauf 0;
BA_ "GenSigSendType" SG_ 153 EM_Fehler_ElAntriebFreilauf 0;
BA_ "GenSigSwitchedByIgnition" SG_ 153 EM_Max_Moment 0;
BA_ "GenSigStartValue" SG_ 153 EM_Max_Moment 1023;
BA_ "GenSigSendType" SG_ 153 EM_Max_Moment 0;
BA_ "GenSigSwitchedByIgnition" SG_ 153 EM_Min_Moment 0;
BA_ "GenSigStartValue" SG_ 153 EM_Min_Moment 1023;
BA_ "GenSigSendType" SG_ 153 EM_Min_Moment 0;
BA_ "GenSigSwitchedByIgnition" SG_ 153 EM_MaxDyn_Moment 0;
BA_ "GenSigStartValue" SG_ 153 EM_MaxDyn_Moment 1023;
BA_ "GenSigSendType" SG_ 153 EM_MaxDyn_Moment 0;
BA_ "GenSigSwitchedByIgnition" SG_ 153 EM_MinDyn_Moment 0;
BA_ "GenSigStartValue" SG_ 153 EM_MinDyn_Moment 1023;
BA_ "GenSigSendType" SG_ 153 EM_MinDyn_Moment 0;
BA_ "Fehlerwert" SG_ 81 EM_IstDrehzahl 65535;
BA_ "GenSigSwitchedByIgnition" SG_ 81 EM_IstDrehzahl 0;
BA_ "GenSigStartValue" SG_ 81 EM_IstDrehzahl 65534;
BA_ "GenSigSendType" SG_ 81 EM_IstDrehzahl 0;
BA_ "GenSigSwitchedByIgnition" SG_ 195 GPM_01_CHK 0;
BA_ "GenSigFuncType" SG_ 195 GPM_01_CHK 4;
BA_ "GenSigSendType" SG_ 195 GPM_01_CHK 0;
BA_ "GenSigSwitchedByIgnition" SG_ 195 GPM_01_BZ 0;
BA_ "GenSigFuncType" SG_ 195 GPM_01_BZ 1;
BA_ "GenSigSendType" SG_ 195 GPM_01_BZ 0;
BA_ "GenSigSendType" SG_ 195 GPM_State 0;
BA_ "GenSigSendType" SG_ 195 GPM_AspAktuatorweg 0;
BA_ "GenSigSendType" SG_ 195 GPM_AspPedalweg 0;
BA_ "GenSigSendType" SG_ 195 GPM_AktuatorUebertreten 0;
BA_ "Fehlerwert" SG_ 195 GPM_Fehler_mechanisch 1;
BA_ "GenSigSendType" SG_ 195 GPM_Fehler_mechanisch 0;
BA_ "Fehlerwert" SG_ 195 GPM_Fehler_CAN 1;
BA_ "GenSigSendType" SG_ 195 GPM_Fehler_CAN 0;
BA_ "GenSigSendType" SG_ 195 GPM_SleepInd 0;
BA_ "Fehlerwert" SG_ 195 GPM_Fehler_Unterspannung 1;
BA_ "GenSigSendType" SG_ 195 GPM_Fehler_Unterspannung 0;
BA_ "Fehlerwert" SG_ 195 GPM_Fehler_Temperatur 1;
BA_ "GenSigSendType" SG_ 195 GPM_Fehler_Temperatur 0;
BA_ "Fehlerwert" SG_ 195 GPM_Fehler_HW 1;
BA_ "GenSigSendType" SG_ 195 GPM_Fehler_HW 0;
BA_ "Fehlerwert" SG_ 195 GPM_Warnung_Temperatur 1;
BA_ "GenSigSendType" SG_ 195 GPM_Warnung_Temperatur 0;
BA_ "GenSigSwitchedByIgnition" SG_ 1705 GPM_TeileNr_Mux 0;
BA_ "GenSigSwitchedByIgnition" SG_ 1705 GPM_TeileNr_Word_01 0;
BA_ "GenSigSwitchedByIgnition" SG_ 1705 GPM_TeileNr_Word_02 0;
BA_ "GenSigSwitchedByIgnition" SG_ 1705 GPM_TeileNr_Word_03 0;
BA_ "GenSigSwitchedByIgnition" SG_ 1705 GPM_TeileNr_Word_04 0;
BA_ "GenSigSwitchedByIgnition" SG_ 1705 GPM_TeileNr_Word_05 0;
BA_ "GenSigSwitchedByIgnition" SG_ 1705 GPM_TeileNr_Word_06 0;
BA_ "GenSigSwitchedByIgnition" SG_ 1705 GPM_TeileNr_Word_07 0;
BA_ "GenSigSwitchedByIgnition" SG_ 1705 GPM_TeileNr_Word_08 0;
BA_ "GenSigSwitchedByIgnition" SG_ 1705 GPM_TeileNr_Word_09 0;
BA_ "GenSigSwitchedByIgnition" SG_ 1705 GPM_TeileNr_Word_10 0;
BA_ "GenSigSwitchedByIgnition" SG_ 1705 GPM_TeileNr_Word_11 0;
BA_ "GenSigSwitchedByIgnition" SG_ 1705 GPM_TeileNr_Word_12 0;
BA_ "GenSigSwitchedByIgnition" SG_ 1705 GPM_TeileNr_Word_13 0;
BA_ "GenSigSwitchedByIgnition" SG_ 1705 GPM_TeileNr_Word_14 0;
BA_ "GenSigSwitchedByIgnition" SG_ 1705 GPM_TeileNr_Word_15 0;
BA_ "GenSigSwitchedByIgnition" SG_ 1705 GPM_TeileNr_Word_16 0;
BA_ "GenSigSendType" SG_ 1705 GPM_Seriennummer 0;
BA_ "GenSigSwitchedByIgnition" SG_ 1705 GPM_HW_Version 0;
BA_ "GenSigSendType" SG_ 1705 GPM_HW_Version 0;
BA_ "GenSigSendType" SG_ 1705 GPM_SW_Version 0;
BA_ "GenSigSwitchedByIgnition" SG_ 1382 HVLM_01_CHK 0;
BA_ "GenSigFuncType" SG_ 1382 HVLM_01_CHK 4;
BA_ "GenSigSendType" SG_ 1382 HVLM_01_CHK 0;
BA_ "GenSigSwitchedByIgnition" SG_ 1382 HVLM_01_BZ 0;
BA_ "GenSigFuncType" SG_ 1382 HVLM_01_BZ 1;
BA_ "GenSigSendType" SG_ 1382 HVLM_01_BZ 0;
BA_ "Fehlerwert" SG_ 1382 HVLM_Fehler_Ladestecker 1;
BA_ "GenSigSwitchedByIgnition" SG_ 1382 HVLM_Fehler_Ladestecker 0;
BA_ "GenSigSendType" SG_ 1382 HVLM_Fehler_Ladestecker 0;
BA_ "Fehlerwert" SG_ 1382 HVLM_Fehler_Verriegelung 1;
BA_ "GenSigSwitchedByIgnition" SG_ 1382 HVLM_Fehler_Verriegelung 0;
BA_ "GenSigSendType" SG_ 1382 HVLM_Fehler_Verriegelung 0;
BA_ "GenSigSwitchedByIgnition" SG_ 1382 HVLM_SollStrom_HV_Offset 0;
BA_ "GenSigSendType" SG_ 1382 HVLM_SollStrom_HV_Offset 0;
BA_ "Fehlerwert" SG_ 1382 HVLM_IstStrom 511;
BA_ "GenSigSwitchedByIgnition" SG_ 1382 HVLM_IstStrom 0;
BA_ "GenSigStartValue" SG_ 1382 HVLM_IstStrom 510;
BA_ "GenSigSendType" SG_ 1382 HVLM_IstStrom 0;
BA_ "Fehlerwert" SG_ 1382 HVLM_IstModus_02 3;
BA_ "GenSigSwitchedByIgnition" SG_ 1382 HVLM_IstModus_02 0;
BA_ "GenSigStartValue" SG_ 1382 HVLM_IstModus_02 2;
BA_ "GenSigSendType" SG_ 1382 HVLM_IstModus_02 0;
BA_ "GenSigSwitchedByIgnition" SG_ 1382 HVLM_Konditionierung_Anf 0;
BA_ "GenSigSendType" SG_ 1382 HVLM_Konditionierung_Anf 0;
BA_ "Fehlerwert" SG_ 1382 HVLM_LadeAnforderung 7;
BA_ "GenSigSwitchedByIgnition" SG_ 1382 HVLM_LadeAnforderung 0;
BA_ "GenSigStartValue" SG_ 1382 HVLM_LadeAnforderung 6;
BA_ "GenSigSendType" SG_ 1382 HVLM_LadeAnforderung 0;
BA_ "GenSigSwitchedByIgnition" SG_ 1382 HVLM_Stecker_Status 0;
BA_ "GenSigSendType" SG_ 1382 HVLM_Stecker_Status 0;
BA_ "Fehlerwert" SG_ 1382 HVLM_SollStrom_HV 1023;
BA_ "GenSigSwitchedByIgnition" SG_ 1382 HVLM_SollStrom_HV 0;
BA_ "GenSigStartValue" SG_ 1382 HVLM_SollStrom_HV 1022;
BA_ "GenSigSendType" SG_ 1382 HVLM_SollStrom_HV 0;
BA_ "Fehlerwert" SG_ 1382 HVLM_MaxSpannung_HV 1023;
BA_ "GenSigSwitchedByIgnition" SG_ 1382 HVLM_MaxSpannung_HV 0;
BA_ "GenSigStartValue" SG_ 1382 HVLM_MaxSpannung_HV 1022;
BA_ "GenSigSendType" SG_ 1382 HVLM_MaxSpannung_HV 0;
BA_ "Fehlerwert" SG_ 1381 HVLM_HV_Abstellzeit 255;
BA_ "GenSigSwitchedByIgnition" SG_ 1381 HVLM_HV_Abstellzeit 0;
BA_ "GenSigStartValue" SG_ 1381 HVLM_HV_Abstellzeit 254;
BA_ "GenSigSendType" SG_ 1381 HVLM_HV_Abstellzeit 0;
BA_ "Fehlerwert" SG_ 1381 HVLM_Zustand_LED 15;
BA_ "GenSigSwitchedByIgnition" SG_ 1381 HVLM_Zustand_LED 0;
BA_ "GenSigStartValue" SG_ 1381 HVLM_Zustand_LED 14;
BA_ "GenSigSendType" SG_ 1381 HVLM_Zustand_LED 3;
BA_ "Fehlerwert" SG_ 1381 HVLM_MaxLadezeitDCHV 255;
BA_ "GenSigSwitchedByIgnition" SG_ 1381 HVLM_MaxLadezeitDCHV 0;
BA_ "GenSigStartValue" SG_ 1381 HVLM_MaxLadezeitDCHV 254;
BA_ "GenSigSendType" SG_ 1381 HVLM_MaxLadezeitDCHV 3;
BA_ "Fehlerwert" SG_ 1381 HVLM_MaxStrom_Netz 127;
BA_ "GenSigSwitchedByIgnition" SG_ 1381 HVLM_MaxStrom_Netz 0;
BA_ "GenSigStartValue" SG_ 1381 HVLM_MaxStrom_Netz 126;
BA_ "GenSigSendType" SG_ 1381 HVLM_MaxStrom_Netz 3;
BA_ "GenSigSwitchedByIgnition" SG_ 1381 HVLM_LG_Sollmodus 0;
BA_ "GenSigSendType" SG_ 1381 HVLM_LG_Sollmodus 3;
BA_ "Fehlerwert" SG_ 1381 HVLM_FreigabeTankdeckel 3;
BA_ "GenSigSwitchedByIgnition" SG_ 1381 HVLM_FreigabeTankdeckel 0;
BA_ "GenSigStartValue" SG_ 1381 HVLM_FreigabeTankdeckel 2;
BA_ "GenSigSendType" SG_ 1381 HVLM_FreigabeTankdeckel 3;
BA_ "GenSigSwitchedByIgnition" SG_ 1381 HVLM_Stecker_Verriegeln 0;
BA_ "GenSigStartValue" SG_ 1381 HVLM_Stecker_Verriegeln 2;
BA_ "GenSigSendType" SG_ 1381 HVLM_Stecker_Verriegeln 3;
BA_ "GenSigSwitchedByIgnition" SG_ 1381 HVLM_Start_Spannungsmessung_DCLS 0;
BA_ "GenSigSendType" SG_ 1381 HVLM_Start_Spannungsmessung_DCLS 3;
BA_ "Fehlerwert" SG_ 1381 HVLM_Taster_Profil_Laden_Anf 3;
BA_ "GenSigSwitchedByIgnition" SG_ 1381 HVLM_Taster_Profil_Laden_Anf 0;
BA_ "GenSigStartValue" SG_ 1381 HVLM_Taster_Profil_Laden_Anf 2;
BA_ "GenSigSendType" SG_ 1381 HVLM_Taster_Profil_Laden_Anf 3;
BA_ "Fehlerwert" SG_ 1381 HVLM_Taster_Sofort_Laden_Anf 3;
BA_ "GenSigSwitchedByIgnition" SG_ 1381 HVLM_Taster_Sofort_Laden_Anf 0;
BA_ "GenSigStartValue" SG_ 1381 HVLM_Taster_Sofort_Laden_Anf 2;
BA_ "GenSigSendType" SG_ 1381 HVLM_Taster_Sofort_Laden_Anf 3;
BA_ "Fehlerwert" SG_ 1381 HVLM_FreigabeKlimatisierung 3;
BA_ "GenSigSwitchedByIgnition" SG_ 1381 HVLM_FreigabeKlimatisierung 0;
BA_ "GenSigStartValue" SG_ 1381 HVLM_FreigabeKlimatisierung 2;
BA_ "GenSigSendType" SG_ 1381 HVLM_FreigabeKlimatisierung 0;
BA_ "GenSigSwitchedByIgnition" SG_ 1381 HVLM_Ladetexte 0;
BA_ "GenSigSendType" SG_ 1381 HVLM_Ladetexte 3;
BA_ "Fehlerwert" SG_ 1381 HVLM_IstSpannung_HV 1023;
BA_ "GenSigSwitchedByIgnition" SG_ 1381 HVLM_IstSpannung_HV 0;
BA_ "GenSigStartValue" SG_ 1381 HVLM_IstSpannung_HV 1022;
BA_ "GenSigSendType" SG_ 1381 HVLM_IstSpannung_HV 3;
BA_ "GenSigSwitchedByIgnition" SG_ 1380 LAD_01_CHK 0;
BA_ "GenSigFuncType" SG_ 1380 LAD_01_CHK 4;
BA_ "GenSigSendType" SG_ 1380 LAD_01_CHK 0;
BA_ "GenSigSwitchedByIgnition" SG_ 1380 LAD_01_BZ 0;
BA_ "GenSigFuncType" SG_ 1380 LAD_01_BZ 1;
BA_ "GenSigSendType" SG_ 1380 LAD_01_BZ 0;
BA_ "Fehlerwert" SG_ 1380 LAD_IstModus 5;
BA_ "GenSigSwitchedByIgnition" SG_ 1380 LAD_IstModus 0;
BA_ "GenSigStartValue" SG_ 1380 LAD_IstModus 7;
BA_ "GenSigSendType" SG_ 1380 LAD_IstModus 5;
BA_ "Fehlerwert" SG_ 1380 LAD_AC_Istspannung 511;
BA_ "GenSigSwitchedByIgnition" SG_ 1380 LAD_AC_Istspannung 0;
BA_ "GenSigStartValue" SG_ 1380 LAD_AC_Istspannung 510;
BA_ "GenSigSendType" SG_ 1380 LAD_AC_Istspannung 0;
BA_ "Fehlerwert" SG_ 1380 LAD_IstSpannung_HV 1023;
BA_ "GenSigSwitchedByIgnition" SG_ 1380 LAD_IstSpannung_HV 0;
BA_ "GenSigStartValue" SG_ 1380 LAD_IstSpannung_HV 1022;
BA_ "GenSigSendType" SG_ 1380 LAD_IstSpannung_HV 0;
BA_ "Fehlerwert" SG_ 1380 LAD_IstStrom_HV 1023;
BA_ "GenSigSwitchedByIgnition" SG_ 1380 LAD_IstStrom_HV 0;
BA_ "GenSigStartValue" SG_ 1380 LAD_IstStrom_HV 1022;
BA_ "GenSigSendType" SG_ 1380 LAD_IstStrom_HV 0;
BA_ "GenSigSwitchedByIgnition" SG_ 1380 LAD_Status_Spgfreiheit 0;
BA_ "GenSigSendType" SG_ 1380 LAD_Status_Spgfreiheit 4;
BA_ "GenSigActiveRepetitions" SG_ 1380 LAD_Status_Spgfreiheit 5;
BA_ "Fehlerwert" SG_ 1380 LAD_Temperatur 255;
BA_ "GenSigSwitchedByIgnition" SG_ 1380 LAD_Temperatur 0;
BA_ "GenSigStartValue" SG_ 1380 LAD_Temperatur 254;
BA_ "GenSigSendType" SG_ 1380 LAD_Temperatur 0;
BA_ "Fehlerwert" SG_ 1380 LAD_Verlustleistung 255;
BA_ "GenSigSwitchedByIgnition" SG_ 1380 LAD_Verlustleistung 0;
BA_ "GenSigStartValue" SG_ 1380 LAD_Verlustleistung 254;
BA_ "GenSigSendType" SG_ 1380 LAD_Verlustleistung 0;
BA_ "GenSigSwitchedByIgnition" SG_ 1662 LAD_02_CHK 0;
BA_ "GenSigFuncType" SG_ 1662 LAD_02_CHK 4;
BA_ "GenSigSendType" SG_ 1662 LAD_02_CHK 0;
BA_ "GenSigSwitchedByIgnition" SG_ 1662 LAD_02_BZ 0;
BA_ "GenSigFuncType" SG_ 1662 LAD_02_BZ 1;
BA_ "GenSigSendType" SG_ 1662 LAD_02_BZ 0;
BA_ "GenSigSwitchedByIgnition" SG_ 1662 LAD_Abregelung_Temperatur 0;
BA_ "GenSigSendType" SG_ 1662 LAD_Abregelung_Temperatur 0;
BA_ "GenSigSwitchedByIgnition" SG_ 1662 LAD_Abregelung_IU_Ein_Aus 0;
BA_ "GenSigSendType" SG_ 1662 LAD_Abregelung_IU_Ein_Aus 0;
BA_ "GenSigSwitchedByIgnition" SG_ 1662 LAD_Abregelung_BuchseTemp 0;
BA_ "GenSigSendType" SG_ 1662 LAD_Abregelung_BuchseTemp 0;
BA_ "GenSigSwitchedByIgnition" SG_ 1662 LAD_Warnlampe_Anf 0;
BA_ "GenSigSendType" SG_ 1662 LAD_Warnlampe_Anf 0;
BA_ "Fehlerwert" SG_ 1662 LAD_MaxLadLeistung_HV 511;
BA_ "GenSigSwitchedByIgnition" SG_ 1662 LAD_MaxLadLeistung_HV 0;
BA_ "GenSigStartValue" SG_ 1662 LAD_MaxLadLeistung_HV 510;
BA_ "GenSigSendType" SG_ 1662 LAD_MaxLadLeistung_HV 0;
BA_ "Fehlerwert" SG_ 1662 LAD_CP_Stromlimit 127;
BA_ "GenSigSwitchedByIgnition" SG_ 1662 LAD_CP_Stromlimit 0;
BA_ "GenSigStartValue" SG_ 1662 LAD_CP_Stromlimit 126;
BA_ "GenSigSendType" SG_ 1662 LAD_CP_Stromlimit 0;
BA_ "Fehlerwert" SG_ 1662 LAD_PRX_Stromlimit 7;
BA_ "GenSigSwitchedByIgnition" SG_ 1662 LAD_PRX_Stromlimit 0;
BA_ "GenSigStartValue" SG_ 1662 LAD_PRX_Stromlimit 6;
BA_ "GenSigSendType" SG_ 1662 LAD_PRX_Stromlimit 0;
BA_ "GenSigSwitchedByIgnition" SG_ 1662 LAD_CP_Erkennung 0;
BA_ "GenSigSendType" SG_ 1662 LAD_CP_Erkennung 3;
BA_ "GenSigSwitchedByIgnition" SG_ 1662 LAD_Stecker_Verriegelt 0;
BA_ "GenSigSendType" SG_ 1662 LAD_Stecker_Verriegelt 0;
BA_ "GenSigSwitchedByIgnition" SG_ 1662 LAD_Stecker_Gesteckt 0;
BA_ "GenSigSendType" SG_ 1662 LAD_Stecker_Gesteckt 3;
BA_ "GenSigSwitchedByIgnition" SG_ 1662 LAD_Kuehlbedarf 0;
BA_ "GenSigSendType" SG_ 1662 LAD_Kuehlbedarf 0;
BA_ "GenSigSwitchedByIgnition" SG_ 1662 LAD_MaxLadLeistung_HV_Offset 0;
BA_ "GenSigSendType" SG_ 1662 LAD_MaxLadLeistung_HV_Offset 0;
BA_ "GenSigSwitchedByIgnition" SG_ 1662 LAD_Fehlerstatus 0;
BA_ "GenSigStartValue" SG_ 1662 LAD_Fehlerstatus 7;
BA_ "GenSigSendType" SG_ 1662 LAD_Fehlerstatus 0;
BA_ "GenSigSwitchedByIgnition" SG_ 1662 LAD_Warnzustand 0;
BA_ "GenSigSendType" SG_ 1662 LAD_Warnzustand 0;
BA_ "GenSigSwitchedByIgnition" SG_ 1662 LAD_Fehlerzustand 0;
BA_ "GenSigSendType" SG_ 1662 LAD_Fehlerzustand 0;
BA_ "GenSigSwitchedByIgnition" SG_ 934 MSG_HYB_01_CHK 0;
BA_ "GenSigFuncType" SG_ 934 MSG_HYB_01_CHK 4;
BA_ "GenSigSendType" SG_ 934 MSG_HYB_01_CHK 0;
BA_ "GenSigSwitchedByIgnition" SG_ 934 MSG_HYB_01_BZ 0;
BA_ "GenSigFuncType" SG_ 934 MSG_HYB_01_BZ 1;
BA_ "GenSigSendType" SG_ 934 MSG_HYB_01_BZ 0;
BA_ "GenSigSwitchedByIgnition" SG_ 934 MO_SleepAckn 0;
BA_ "GenSigSendType" SG_ 934 MO_SleepAckn 0;
BA_ "GenSigSwitchedByIgnition" SG_ 934 MO_ErwGrenzen_Anf 0;
BA_ "GenSigSendType" SG_ 934 MO_ErwGrenzen_Anf 3;
BA_ "GenSigSwitchedByIgnition" SG_ 934 MO_Fehler_Notentladung_Anf 0;
BA_ "GenSigSendType" SG_ 934 MO_Fehler_Notentladung_Anf 3;
BA_ "GenSigSwitchedByIgnition" SG_ 934 MO_DC_Sollmodus 0;
BA_ "GenSigStartValue" SG_ 934 MO_DC_Sollmodus 7;
BA_ "GenSigSendType" SG_ 934 MO_DC_Sollmodus 3;
BA_ "GenSigSwitchedByIgnition" SG_ 934 MO_DC_LangsRegelung_Anf 0;
BA_ "GenSigSendType" SG_ 934 MO_DC_LangsRegelung_Anf 3;
BA_ "GenSigSwitchedByIgnition" SG_ 934 MO_BMS_Sollmodus 0;
BA_ "GenSigStartValue" SG_ 934 MO_BMS_Sollmodus 7;
BA_ "GenSigSendType" SG_ 934 MO_BMS_Sollmodus 3;
BA_ "GenSigSwitchedByIgnition" SG_ 934 MO_BMS_IsoMessung_Anf 0;
BA_ "GenSigSendType" SG_ 934 MO_BMS_IsoMessung_Anf 3;
BA_ "Fehlerwert" SG_ 934 MO_HV_Deaktivierungsmodus 3;
BA_ "GenSigSwitchedByIgnition" SG_ 934 MO_HV_Deaktivierungsmodus 0;
BA_ "GenSigSwitchedByIgnition" SG_ 934 MO_LG_Sollmodus 0;
BA_ "GenSigStartValue" SG_ 934 MO_LG_Sollmodus 7;
BA_ "GenSigSendType" SG_ 934 MO_LG_Sollmodus 3;
BA_ "GenSigSwitchedByIgnition" SG_ 934 MO_Ladebereit 0;
BA_ "GenSigSendType" SG_ 934 MO_Ladebereit 0;
BA_ "GenSigSwitchedByIgnition" SG_ 935 MSG_HYB_02_CHK 0;
BA_ "GenSigFuncType" SG_ 935 MSG_HYB_02_CHK 4;
BA_ "GenSigSendType" SG_ 935 MSG_HYB_02_CHK 0;
BA_ "GenSigSwitchedByIgnition" SG_ 935 MSG_HYB_02_BZ 0;
BA_ "GenSigFuncType" SG_ 935 MSG_HYB_02_BZ 1;
BA_ "GenSigSendType" SG_ 935 MSG_HYB_02_BZ 0;
BA_ "GenSigSwitchedByIgnition" SG_ 935 MO_DC_SollSpannung_NV 0;
BA_ "GenSigStartValue" SG_ 935 MO_DC_SollSpannung_NV 255;
BA_ "GenSigSendType" SG_ 935 MO_DC_SollSpannung_NV 0;
BA_ "GenSigSwitchedByIgnition" SG_ 935 MO_DC_Max_Strom_HV 0;
BA_ "GenSigStartValue" SG_ 935 MO_DC_Max_Strom_HV 255;
BA_ "GenSigSendType" SG_ 935 MO_DC_Max_Strom_HV 0;
BA_ "GenSigSwitchedByIgnition" SG_ 935 MO_DC_Min_Spannung_HV 0;
BA_ "GenSigStartValue" SG_ 935 MO_DC_Min_Spannung_HV 255;
BA_ "GenSigSendType" SG_ 935 MO_DC_Min_Spannung_HV 0;
BA_ "GenSigSwitchedByIgnition" SG_ 935 MO_DC_SollSpannung_HV 0;
BA_ "GenSigStartValue" SG_ 935 MO_DC_SollSpannung_HV 255;
BA_ "GenSigSendType" SG_ 935 MO_DC_SollSpannung_HV 0;
BA_ "GenSigSwitchedByIgnition" SG_ 935 MO_DC_Max_Strom_NV 0;
BA_ "GenSigStartValue" SG_ 935 MO_DC_Max_Strom_NV 255;
BA_ "GenSigSendType" SG_ 935 MO_DC_Max_Strom_NV 0;
BA_ "GenSigSwitchedByIgnition" SG_ 935 MO_DC_Min_Spannung_NV 0;
BA_ "GenSigStartValue" SG_ 935 MO_DC_Min_Spannung_NV 255;
BA_ "GenSigSendType" SG_ 935 MO_DC_Min_Spannung_NV 0;
BA_ "GenSigSwitchedByIgnition" SG_ 144 MSG_HYB_03_CHK 0;
BA_ "GenSigFuncType" SG_ 144 MSG_HYB_03_CHK 4;
BA_ "GenSigSendType" SG_ 144 MSG_HYB_03_CHK 0;
BA_ "GenSigSwitchedByIgnition" SG_ 144 MSG_HYB_03_BZ 0;
BA_ "GenSigFuncType" SG_ 144 MSG_HYB_03_BZ 1;
BA_ "GenSigSendType" SG_ 144 MSG_HYB_03_BZ 0;
BA_ "GenSigSwitchedByIgnition" SG_ 144 MO_EM_Sollmodus 0;
BA_ "GenSigStartValue" SG_ 144 MO_EM_Sollmodus 15;
BA_ "GenSigSendType" SG_ 144 MO_EM_Sollmodus 0;
BA_ "GenSigSwitchedByIgnition" SG_ 144 MO_EM_SollMoment 0;
BA_ "GenSigStartValue" SG_ 144 MO_EM_SollMoment 16383;
BA_ "GenSigSendType" SG_ 144 MO_EM_SollMoment 0;
BA_ "GenSigSwitchedByIgnition" SG_ 144 MO_EM_SollDrehzahl 0;
BA_ "GenSigStartValue" SG_ 144 MO_EM_SollDrehzahl 32767;
BA_ "GenSigSendType" SG_ 144 MO_EM_SollDrehzahl 0;
BA_ "GenSigSwitchedByIgnition" SG_ 144 MO_EM_SollSpannung 0;
BA_ "GenSigStartValue" SG_ 144 MO_EM_SollSpannung 16383;
BA_ "GenSigSendType" SG_ 144 MO_EM_SollSpannung 0;
BA_ "Fehlerwert" SG_ 144 MO_Waehlpos 7;
BA_ "GenSigSwitchedByIgnition" SG_ 144 MO_Waehlpos 0;
BA_ "GenSigSendType" SG_ 144 MO_Waehlpos 0;
BA_ "GenSigSwitchedByIgnition" SG_ 145 MSG_HYB_07_CHK 0;
BA_ "GenSigFuncType" SG_ 145 MSG_HYB_07_CHK 4;
BA_ "GenSigSendType" SG_ 145 MSG_HYB_07_CHK 0;
BA_ "GenSigSwitchedByIgnition" SG_ 145 MSG_HYB_07_BZ 0;
BA_ "GenSigFuncType" SG_ 145 MSG_HYB_07_BZ 1;
BA_ "GenSigSendType" SG_ 145 MSG_HYB_07_BZ 0;
BA_ "GenSigSwitchedByIgnition" SG_ 145 MO_EM_AR_Anf 0;
BA_ "GenSigSendType" SG_ 145 MO_EM_AR_Anf 0;
BA_ "GenSigSwitchedByIgnition" SG_ 145 MO_EM_Dyn_Kp_AR 0;
BA_ "GenSigStartValue" SG_ 145 MO_EM_Dyn_Kp_AR 255;
BA_ "GenSigSendType" SG_ 145 MO_EM_Dyn_Kp_AR 0;
BA_ "GenSigSwitchedByIgnition" SG_ 145 MO_EM_Stat_Kp_AR 0;
BA_ "GenSigStartValue" SG_ 145 MO_EM_Stat_Kp_AR 255;
BA_ "GenSigSendType" SG_ 145 MO_EM_Stat_Kp_AR 0;
BA_ "GenSigSwitchedByIgnition" SG_ 145 MO_EM_DynLimit_AR 0;
BA_ "GenSigStartValue" SG_ 145 MO_EM_DynLimit_AR 255;
BA_ "GenSigSendType" SG_ 145 MO_EM_DynLimit_AR 0;
BA_ "GenSigSwitchedByIgnition" SG_ 145 MO_EM_StatLimit_AR 0;
BA_ "GenSigStartValue" SG_ 145 MO_EM_StatLimit_AR 255;
BA_ "GenSigSendType" SG_ 145 MO_EM_StatLimit_AR 0;
BA_ "GenSigSwitchedByIgnition" SG_ 145 MO_EM_Periode_AR 0;
BA_ "GenSigStartValue" SG_ 145 MO_EM_Periode_AR 255;
BA_ "GenSigSendType" SG_ 145 MO_EM_Periode_AR 0;
BA_ "GenSigSwitchedByIgnition" SG_ 145 MO_EM_Strom_HVVerbraucher 0;
BA_ "GenSigStartValue" SG_ 145 MO_EM_Strom_HVVerbraucher 255;
BA_ "GenSigSendType" SG_ 145 MO_EM_Strom_HVVerbraucher 0;
BA_ "GenSigSwitchedByIgnition" SG_ 146 MSG_HYB_08_CHK 0;
BA_ "GenSigFuncType" SG_ 146 MSG_HYB_08_CHK 4;
BA_ "GenSigSendType" SG_ 146 MSG_HYB_08_CHK 0;
BA_ "GenSigSwitchedByIgnition" SG_ 146 MSG_HYB_08_BZ 0;
BA_ "GenSigFuncType" SG_ 146 MSG_HYB_08_BZ 1;
BA_ "GenSigSendType" SG_ 146 MSG_HYB_08_BZ 0;
BA_ "Fehlerwert" SG_ 146 MO_EM_MinMoment_DrzRegler 8191;
BA_ "GenSigSwitchedByIgnition" SG_ 146 MO_EM_MinMoment_DrzRegler 0;
BA_ "GenSigStartValue" SG_ 146 MO_EM_MinMoment_DrzRegler 8190;
BA_ "GenSigSendType" SG_ 146 MO_EM_MinMoment_DrzRegler 0;
BA_ "Fehlerwert" SG_ 146 MO_EM_MaxMoment_DrzRegler 8191;
BA_ "GenSigSwitchedByIgnition" SG_ 146 MO_EM_MaxMoment_DrzRegler 0;
BA_ "GenSigStartValue" SG_ 146 MO_EM_MaxMoment_DrzRegler 8190;
BA_ "GenSigSendType" SG_ 146 MO_EM_MaxMoment_DrzRegler 0;
BA_ "GenSigSwitchedByIgnition" SG_ 146 MO_EM_Band_KpKlein_DrzRegler 0;
BA_ "GenSigStartValue" SG_ 146 MO_EM_Band_KpKlein_DrzRegler 1023;
BA_ "GenSigSendType" SG_ 146 MO_EM_Band_KpKlein_DrzRegler 0;
BA_ "GenSigSwitchedByIgnition" SG_ 146 MO_EM_KpKlein_DrzRegler 0;
BA_ "GenSigStartValue" SG_ 146 MO_EM_KpKlein_DrzRegler 255;
BA_ "GenSigSendType" SG_ 146 MO_EM_KpKlein_DrzRegler 0;
BA_ "GenSigSwitchedByIgnition" SG_ 146 MO_EM_KpGross_DrzRegler 0;
BA_ "GenSigStartValue" SG_ 146 MO_EM_KpGross_DrzRegler 255;
BA_ "GenSigSendType" SG_ 146 MO_EM_KpGross_DrzRegler 0;
BA_ "GenSigSwitchedByIgnition" SG_ 936 MSG_HYB_09_CHK 0;
BA_ "GenSigFuncType" SG_ 936 MSG_HYB_09_CHK 4;
BA_ "GenSigSendType" SG_ 936 MSG_HYB_09_CHK 0;
BA_ "GenSigSwitchedByIgnition" SG_ 936 MSG_HYB_09_BZ 0;
BA_ "GenSigFuncType" SG_ 936 MSG_HYB_09_BZ 1;
BA_ "GenSigSendType" SG_ 936 MSG_HYB_09_BZ 0;
BA_ "GenSigSwitchedByIgnition" SG_ 936 MO_EM_Max_Moment 0;
BA_ "GenSigStartValue" SG_ 936 MO_EM_Max_Moment 1023;
BA_ "GenSigSendType" SG_ 936 MO_EM_Max_Moment 3;
BA_ "GenSigSwitchedByIgnition" SG_ 936 MO_EM_Min_Moment 0;
BA_ "GenSigStartValue" SG_ 936 MO_EM_Min_Moment 1023;
BA_ "GenSigSendType" SG_ 936 MO_EM_Min_Moment 3;
BA_ "GenSigSwitchedByIgnition" SG_ 936 MO_EM_Max_Momentengradient 0;
BA_ "GenSigStartValue" SG_ 936 MO_EM_Max_Momentengradient 255;
BA_ "GenSigSendType" SG_ 936 MO_EM_Max_Momentengradient 3;
BA_ "GenSigSwitchedByIgnition" SG_ 936 MO_EM_Max_Moment_AR 0;
BA_ "GenSigSendType" SG_ 936 MO_EM_Max_Moment_AR 3;
BA_ "GenSigSwitchedByIgnition" SG_ 936 MO_EM_MaxPred_Strom 0;
BA_ "GenSigStartValue" SG_ 936 MO_EM_MaxPred_Strom 1023;
BA_ "GenSigSendType" SG_ 936 MO_EM_MaxPred_Strom 0;
BA_ "GenSigSwitchedByIgnition" SG_ 936 MO_EM_MinPred_Strom 0;
BA_ "GenSigStartValue" SG_ 936 MO_EM_MinPred_Strom 1023;
BA_ "GenSigSendType" SG_ 936 MO_EM_MinPred_Strom 0;
BA_ "GenSigSwitchedByIgnition" SG_ 1698 MSG_HYB_10_CHK 0;
BA_ "GenSigFuncType" SG_ 1698 MSG_HYB_10_CHK 4;
BA_ "GenSigSendType" SG_ 1698 MSG_HYB_10_CHK 0;
BA_ "GenSigSwitchedByIgnition" SG_ 1698 MSG_HYB_10_BZ 0;
BA_ "GenSigFuncType" SG_ 1698 MSG_HYB_10_BZ 1;
BA_ "GenSigSendType" SG_ 1698 MSG_HYB_10_BZ 0;
BA_ "GenSigSwitchedByIgnition" SG_ 1698 MO_EM_Kuehlpumpe_Soll 0;
BA_ "GenSigStartValue" SG_ 1698 MO_EM_Kuehlpumpe_Soll 15;
BA_ "GenSigSendType" SG_ 1698 MO_EM_Kuehlpumpe_Soll 0;
BA_ "Fehlerwert" SG_ 1698 MO_Abstellzeit 255;
BA_ "GenSigSwitchedByIgnition" SG_ 1698 MO_Abstellzeit 0;
BA_ "GenSigStartValue" SG_ 1698 MO_Abstellzeit 254;
BA_ "GenSigSendType" SG_ 1698 MO_Abstellzeit 0;
BA_ "GenSigSwitchedByIgnition" SG_ 1698 MO_Abstellzeit_Status 0;
BA_ "GenSigSendType" SG_ 1698 MO_Abstellzeit_Status 0;
BA_ "GenSigSwitchedByIgnition" SG_ 1698 MO_EM_NTKreisPumpe1_Status 0;
BA_ "GenSigSendType" SG_ 1698 MO_EM_NTKreisPumpe1_Status 0;
BA_ "GenSigSwitchedByIgnition" SG_ 1698 MO_EM_NTKreisPumpe2_Status 0;
BA_ "GenSigSendType" SG_ 1698 MO_EM_NTKreisPumpe2_Status 0;
BA_ "GenSigSwitchedByIgnition" SG_ 1698 MO_EM_NTKreis_Status 0;
BA_ "GenSigSendType" SG_ 1698 MO_EM_NTKreis_Status 0;
BA_ "GenSigSwitchedByIgnition" SG_ 1698 MO_EM_HTKreisPumpe1_Status 0;
BA_ "GenSigSendType" SG_ 1698 MO_EM_HTKreisPumpe1_Status 0;
BA_ "GenSigSwitchedByIgnition" SG_ 1698 MO_EM_HTKreisPumpe2_Status 0;
BA_ "GenSigSendType" SG_ 1698 MO_EM_HTKreisPumpe2_Status 0;
BA_ "GenSigSwitchedByIgnition" SG_ 1698 MO_EM_HTKreis_Status 0;
BA_ "GenSigSendType" SG_ 1698 MO_EM_HTKreis_Status 0;
BA_ "Fehlerwert" SG_ 1698 MO_LuefterGeschw_rel 15;
BA_ "GenSigSwitchedByIgnition" SG_ 1698 MO_LuefterGeschw_rel 0;
BA_ "GenSigStartValue" SG_ 1698 MO_LuefterGeschw_rel 14;
BA_ "GenSigSendType" SG_ 1698 MO_LuefterGeschw_rel 0;
BA_ "Fehlerwert" SG_ 1698 MO_Temp_Kuehleraustritt 255;
BA_ "GenSigSwitchedByIgnition" SG_ 1698 MO_Temp_Kuehleraustritt 0;
BA_ "GenSigStartValue" SG_ 1698 MO_Temp_Kuehleraustritt 254;
BA_ "GenSigSendType" SG_ 1698 MO_Temp_Kuehleraustritt 0;
BA_ "GenSigSwitchedByIgnition" SG_ 150 MSG_HYB_15_CHK 0;
BA_ "GenSigFuncType" SG_ 150 MSG_HYB_15_CHK 4;
BA_ "GenSigSendType" SG_ 150 MSG_HYB_15_CHK 0;
BA_ "GenSigSwitchedByIgnition" SG_ 150 MSG_HYB_15_BZ 0;
BA_ "GenSigFuncType" SG_ 150 MSG_HYB_15_BZ 1;
BA_ "GenSigSendType" SG_ 150 MSG_HYB_15_BZ 0;
BA_ "GenSigSwitchedByIgnition" SG_ 150 MO_CCU_Sollmodus 0;
BA_ "GenSigStartValue" SG_ 150 MO_CCU_Sollmodus 7;
BA_ "GenSigSendType" SG_ 150 MO_CCU_Sollmodus 0;
BA_ "GenSigSwitchedByIgnition" SG_ 150 MO_CCU_DruckLim_Anf 0;
BA_ "GenSigSendType" SG_ 150 MO_CCU_DruckLim_Anf 0;
BA_ "GenSigSwitchedByIgnition" SG_ 150 MO_CCU_PHEV_Mode 0;
BA_ "GenSigSendType" SG_ 150 MO_CCU_PHEV_Mode 0;
BA_ "GenSigSwitchedByIgnition" SG_ 150 MO_CCU_HSR_Hyst 0;
BA_ "GenSigSendType" SG_ 150 MO_CCU_HSR_Hyst 0;
BA_ "GenSigSwitchedByIgnition" SG_ 150 MO_CCU_Sollposition 0;
BA_ "GenSigStartValue" SG_ 150 MO_CCU_Sollposition 8191;
BA_ "GenSigSendType" SG_ 150 MO_CCU_Sollposition 0;
BA_ "GenSigSwitchedByIgnition" SG_ 196 MSG_HYB_22_CHK 0;
BA_ "GenSigFuncType" SG_ 196 MSG_HYB_22_CHK 4;
BA_ "GenSigSendType" SG_ 196 MSG_HYB_22_CHK 0;
BA_ "GenSigSwitchedByIgnition" SG_ 196 MSG_HYB_22_BZ 0;
BA_ "GenSigFuncType" SG_ 196 MSG_HYB_22_BZ 1;
BA_ "GenSigSendType" SG_ 196 MSG_HYB_22_BZ 0;
BA_ "GenSigSwitchedByIgnition" SG_ 196 MO_GPM_act_swt 0;
BA_ "GenSigSendType" SG_ 196 MO_GPM_act_swt 0;
BA_ "GenSigSendType" SG_ 196 MO_GPM_self_test 0;
BA_ "Fehlerwert" SG_ 196 MO_QBit_GPM_Fahrpedalwerte_01 1;
BA_ "GenSigSendType" SG_ 196 MO_QBit_GPM_Fahrpedalwerte_01 0;
BA_ "GenSigSendType" SG_ 196 MO_GPM_sollact_pos 0;
BA_ "GenSigSendType" SG_ 196 MO_GPM_sollactpv_pos 0;
BA_ "Fehlerwert" SG_ 196 MO_GPM_Fahrpedalrohwert 255;
BA_ "GenSigSendType" SG_ 196 MO_GPM_Fahrpedalrohwert 0;
BA_REL_ "GenSigTimeoutTime" BU_SG_REL_ Ladegeraet_PAG_PF SG_ 151 BMS_HYB_02_CHK 500;
BA_REL_ "GenSigTimeoutTime" BU_SG_REL_ LEH_PlugIn SG_ 151 BMS_HYB_02_CHK 500;
BA_REL_ "GenSigTimeoutTime" BU_SG_REL_ Motor_MED17_SIMOS8_PlugIn_PAG_PF SG_ 151 BMS_HYB_02_CHK 500;
BA_REL_ "GenSigTimeoutTime" BU_SG_REL_ Ladegeraet_PAG_PF SG_ 151 BMS_HYB_02_BZ 500;
BA_REL_ "GenSigTimeoutTime" BU_SG_REL_ LEH_PlugIn SG_ 151 BMS_HYB_02_BZ 500;
BA_REL_ "GenSigTimeoutTime" BU_SG_REL_ Motor_MED17_SIMOS8_PlugIn_PAG_PF SG_ 151 BMS_HYB_02_BZ 500;
BA_REL_ "GenSigTimeoutTime" BU_SG_REL_ Ladegeraet_PAG_PF SG_ 151 BMS_IstStrom 500;
BA_REL_ "GenSigTimeoutTime" BU_SG_REL_ LEH_PlugIn SG_ 151 BMS_IstStrom 500;
BA_REL_ "GenSigTimeoutTime" BU_SG_REL_ Motor_MED17_SIMOS8_PlugIn_PAG_PF SG_ 151 BMS_IstStrom 500;
BA_REL_ "GenSigTimeoutTime" BU_SG_REL_ Ladegeraet_PAG_PF SG_ 151 BMS_IstSpannung 500;
BA_REL_ "GenSigTimeoutTime" BU_SG_REL_ LEH_PlugIn SG_ 151 BMS_IstSpannung 500;
BA_REL_ "GenSigTimeoutTime" BU_SG_REL_ Motor_MED17_SIMOS8_PlugIn_PAG_PF SG_ 151 BMS_IstSpannung 500;
BA_REL_ "GenSigTimeoutTime" BU_SG_REL_ Ladegeraet_PAG_PF SG_ 151 BMS_IstModus 500;
BA_REL_ "GenSigTimeoutTime" BU_SG_REL_ LEH_PlugIn SG_ 151 BMS_IstModus 500;
BA_REL_ "GenSigTimeoutTime" BU_SG_REL_ Motor_MED17_SIMOS8_PlugIn_PAG_PF SG_ 151 BMS_IstModus 500;
BA_REL_ "GenSigTimeoutTime" BU_SG_REL_ Motor_MED17_SIMOS8_PlugIn_PAG_PF SG_ 151 BMS_SleepInd 500;
BA_REL_ "GenSigTimeoutTime" BU_SG_REL_ Ladegeraet_PAG_PF SG_ 151 BMS_IsoMessungAktiv 500;
BA_REL_ "GenSigTimeoutTime" BU_SG_REL_ LEH_PlugIn SG_ 151 BMS_IsoMessungAktiv 500;
BA_REL_ "GenSigTimeoutTime" BU_SG_REL_ Motor_MED17_SIMOS8_PlugIn_PAG_PF SG_ 151 BMS_IsoMessungAktiv 500;
BA_REL_ "GenSigTimeoutTime" BU_SG_REL_ Ladegeraet_PAG_PF SG_ 151 BMS_Init_abgeschlossen 500;
BA_REL_ "GenSigTimeoutTime" BU_SG_REL_ LEH_PlugIn SG_ 151 BMS_Init_abgeschlossen 500;
BA_REL_ "GenSigTimeoutTime" BU_SG_REL_ Motor_MED17_SIMOS8_PlugIn_PAG_PF SG_ 151 BMS_Init_abgeschlossen 500;
BA_REL_ "GenSigTimeoutTime" BU_SG_REL_ Ladegeraet_PAG_PF SG_ 151 BMS_Fehler_Notabschaltung_Crash 500;
BA_REL_ "GenSigTimeoutTime" BU_SG_REL_ LEH_PlugIn SG_ 151 BMS_Fehler_Notabschaltung_Crash 500;
BA_REL_ "GenSigTimeoutTime" BU_SG_REL_ Motor_MED17_SIMOS8_PlugIn_PAG_PF SG_ 151 BMS_Fehler_Notabschaltung_Crash 500;
BA_REL_ "GenSigTimeoutTime" BU_SG_REL_ Ladegeraet_PAG_PF SG_ 151 BMS_Fehler_Notabschaltung_Pilot 500;
BA_REL_ "GenSigTimeoutTime" BU_SG_REL_ LEH_PlugIn SG_ 151 BMS_Fehler_Notabschaltung_Pilot 500;
BA_REL_ "GenSigTimeoutTime" BU_SG_REL_ Motor_MED17_SIMOS8_PlugIn_PAG_PF SG_ 151 BMS_Fehler_Notabschaltung_Pilot 500;
BA_REL_ "GenSigTimeoutTime" BU_SG_REL_ Ladegeraet_PAG_PF SG_ 151 BMS_Fehler_HVBattAbschaltung_Anf 500;
BA_REL_ "GenSigTimeoutTime" BU_SG_REL_ LEH_PlugIn SG_ 151 BMS_Fehler_HVBattAbschaltung_Anf 500;
BA_REL_ "GenSigTimeoutTime" BU_SG_REL_ Motor_MED17_SIMOS8_PlugIn_PAG_PF SG_ 151 BMS_Fehler_HVBattAbschaltung_Anf 500;
BA_REL_ "GenSigTimeoutTime" BU_SG_REL_ Ladegeraet_PAG_PF SG_ 151 BMS_Fehler_HVBattAbschaltung 500;
BA_REL_ "GenSigTimeoutTime" BU_SG_REL_ LEH_PlugIn SG_ 151 BMS_Fehler_HVBattAbschaltung 500;
BA_REL_ "GenSigTimeoutTime" BU_SG_REL_ Motor_MED17_SIMOS8_PlugIn_PAG_PF SG_ 151 BMS_Fehler_HVBattAbschaltung 500;
BA_REL_ "GenSigTimeoutTime" BU_SG_REL_ Ladegeraet_PAG_PF SG_ 151 BMS_Fehler_HS_verschweisst 500;
BA_REL_ "GenSigTimeoutTime" BU_SG_REL_ LEH_PlugIn SG_ 151 BMS_Fehler_HS_verschweisst 500;
BA_REL_ "GenSigTimeoutTime" BU_SG_REL_ Motor_MED17_SIMOS8_PlugIn_PAG_PF SG_ 151 BMS_Fehler_HS_verschweisst 500;
BA_REL_ "GenSigTimeoutTime" BU_SG_REL_ Ladegeraet_PAG_PF SG_ 151 BMS_Fehler_HS_offen 500;
BA_REL_ "GenSigTimeoutTime" BU_SG_REL_ Ladegeraet_PAG_PF SG_ 151 BMS_Fehler_Leistungsred 500;
BA_REL_ "GenSigTimeoutTime" BU_SG_REL_ LEH_PlugIn SG_ 151 BMS_Fehler_Leistungsred 500;
BA_REL_ "GenSigTimeoutTime" BU_SG_REL_ Motor_MED17_SIMOS8_PlugIn_PAG_PF SG_ 151 BMS_Fehler_Leistungsred 500;
BA_REL_ "GenSigTimeoutTime" BU_SG_REL_ Ladegeraet_PAG_PF SG_ 151 BMS_Fehler_Isolation 500;
BA_REL_ "GenSigTimeoutTime" BU_SG_REL_ LEH_PlugIn SG_ 151 BMS_Fehler_Isolation 500;
BA_REL_ "GenSigTimeoutTime" BU_SG_REL_ Motor_MED17_SIMOS8_PlugIn_PAG_PF SG_ 151 BMS_Fehler_Isolation 500;
BA_REL_ "GenSigTimeoutTime" BU_SG_REL_ Motor_MED17_SIMOS8_PlugIn_PAG_PF SG_ 151 BMS_Fehler_Kaltstartleistung 500;
BA_REL_ "GenSigTimeoutTime" BU_SG_REL_ Ladegeraet_PAG_PF SG_ 151 BMS_Fehler_Pilot 500;
BA_REL_ "GenSigTimeoutTime" BU_SG_REL_ Ladegeraet_PAG_PF SG_ 151 BMS_Fehler_Sicherung 500;
BA_REL_ "GenSigTimeoutTime" BU_SG_REL_ Ladegeraet_PAG_PF SG_ 938 BMS_HYB_03_CHK 1000;
BA_REL_ "GenSigTimeoutTime" BU_SG_REL_ LEH_PlugIn SG_ 938 BMS_HYB_03_CHK 1000;
BA_REL_ "GenSigTimeoutTime" BU_SG_REL_ Motor_MED17_SIMOS8_PlugIn_PAG_PF SG_ 938 BMS_HYB_03_CHK 1000;
BA_REL_ "GenSigTimeoutTime" BU_SG_REL_ Ladegeraet_PAG_PF SG_ 938 BMS_HYB_03_BZ 1000;
BA_REL_ "GenSigTimeoutTime" BU_SG_REL_ LEH_PlugIn SG_ 938 BMS_HYB_03_BZ 1000;
BA_REL_ "GenSigTimeoutTime" BU_SG_REL_ Motor_MED17_SIMOS8_PlugIn_PAG_PF SG_ 938 BMS_HYB_03_BZ 1000;
BA_REL_ "GenSigTimeoutTime" BU_SG_REL_ Ladegeraet_PAG_PF SG_ 938 BMS_MaxPred_LadeStrom 1000;
BA_REL_ "GenSigTimeoutTime" BU_SG_REL_ LEH_PlugIn SG_ 938 BMS_MaxPred_LadeStrom 1000;
BA_REL_ "GenSigTimeoutTime" BU_SG_REL_ Motor_MED17_SIMOS8_PlugIn_PAG_PF SG_ 938 BMS_MaxPred_LadeStrom 1000;
BA_REL_ "GenSigTimeoutTime" BU_SG_REL_ LEH_PlugIn SG_ 938 BMS_MaxPred_EntladeStrom 1000;
BA_REL_ "GenSigTimeoutTime" BU_SG_REL_ Motor_MED17_SIMOS8_PlugIn_PAG_PF SG_ 938 BMS_MaxPred_EntladeStrom 1000;
BA_REL_ "GenSigTimeoutTime" BU_SG_REL_ LEH_PlugIn SG_ 938 BMS_MinPred_LadeSpannung 1000;
BA_REL_ "GenSigTimeoutTime" BU_SG_REL_ Motor_MED17_SIMOS8_PlugIn_PAG_PF SG_ 938 BMS_MinPred_LadeSpannung 1000;
BA_REL_ "GenSigTimeoutTime" BU_SG_REL_ LEH_PlugIn SG_ 938 BMS_MinPred_EntladeSpannung 1000;
BA_REL_ "GenSigTimeoutTime" BU_SG_REL_ Motor_MED17_SIMOS8_PlugIn_PAG_PF SG_ 938 BMS_MinPred_EntladeSpannung 1000;
BA_REL_ "GenSigTimeoutTime" BU_SG_REL_ LEH_PlugIn SG_ 938 BMS_BattLuefterGeschw_rel 1000;
BA_REL_ "GenSigTimeoutTime" BU_SG_REL_ Motor_MED17_SIMOS8_PlugIn_PAG_PF SG_ 938 BMS_BattLuefterGeschw_rel 1000;
BA_REL_ "GenSigTimeoutTime" BU_SG_REL_ Ladegeraet_PAG_PF SG_ 938 BMS_SOC 1000;
BA_REL_ "GenSigTimeoutTime" BU_SG_REL_ LEH_PlugIn SG_ 938 BMS_SOC 1000;
BA_REL_ "GenSigTimeoutTime" BU_SG_REL_ Motor_MED17_SIMOS8_PlugIn_PAG_PF SG_ 938 BMS_SOC 1000;
BA_REL_ "GenSigTimeoutTime" BU_SG_REL_ Ladegeraet_PAG_PF SG_ 292 BMS_HYB_04_CHK 500;
BA_REL_ "GenSigTimeoutTime" BU_SG_REL_ LEH_PlugIn SG_ 292 BMS_HYB_04_CHK 500;
BA_REL_ "GenSigTimeoutTime" BU_SG_REL_ Motor_MED17_SIMOS8_PlugIn_PAG_PF SG_ 292 BMS_HYB_04_CHK 500;
BA_REL_ "GenSigTimeoutTime" BU_SG_REL_ Ladegeraet_PAG_PF SG_ 292 BMS_HYB_04_BZ 500;
BA_REL_ "GenSigTimeoutTime" BU_SG_REL_ LEH_PlugIn SG_ 292 BMS_HYB_04_BZ 500;
BA_REL_ "GenSigTimeoutTime" BU_SG_REL_ Motor_MED17_SIMOS8_PlugIn_PAG_PF SG_ 292 BMS_HYB_04_BZ 500;
BA_REL_ "GenSigTimeoutTime" BU_SG_REL_ Ladegeraet_PAG_PF SG_ 292 BMS_MinDyn_LadeSpannung 500;
BA_REL_ "GenSigTimeoutTime" BU_SG_REL_ LEH_PlugIn SG_ 292 BMS_MinDyn_LadeSpannung 500;
BA_REL_ "GenSigTimeoutTime" BU_SG_REL_ Motor_MED17_SIMOS8_PlugIn_PAG_PF SG_ 292 BMS_MinDyn_LadeSpannung 500;
BA_REL_ "GenSigTimeoutTime" BU_SG_REL_ LEH_PlugIn SG_ 292 BMS_MinDyn_EntladeSpannung 500;
BA_REL_ "GenSigTimeoutTime" BU_SG_REL_ Motor_MED17_SIMOS8_PlugIn_PAG_PF SG_ 292 BMS_MinDyn_EntladeSpannung 500;
BA_REL_ "GenSigTimeoutTime" BU_SG_REL_ LEH_PlugIn SG_ 292 BMS_MaxDyn_EntladeStrom 500;
BA_REL_ "GenSigTimeoutTime" BU_SG_REL_ Motor_MED17_SIMOS8_PlugIn_PAG_PF SG_ 292 BMS_MaxDyn_EntladeStrom 500;
BA_REL_ "GenSigTimeoutTime" BU_SG_REL_ Ladegeraet_PAG_PF SG_ 292 BMS_MaxDyn_LadeStrom 500;
BA_REL_ "GenSigTimeoutTime" BU_SG_REL_ LEH_PlugIn SG_ 292 BMS_MaxDyn_LadeStrom 500;
BA_REL_ "GenSigTimeoutTime" BU_SG_REL_ Motor_MED17_SIMOS8_PlugIn_PAG_PF SG_ 292 BMS_MaxDyn_LadeStrom 500;
BA_REL_ "GenSigTimeoutTime" BU_SG_REL_ LEH_PlugIn SG_ 292 BMS_ErwGrenzen_aktiv 500;
BA_REL_ "GenSigTimeoutTime" BU_SG_REL_ Motor_MED17_SIMOS8_PlugIn_PAG_PF SG_ 292 BMS_ErwGrenzen_aktiv 500;
BA_REL_ "GenSigTimeoutTime" BU_SG_REL_ Ladegeraet_PAG_PF SG_ 1699 BMS_HYB_06_CHK 5000;
BA_REL_ "GenSigTimeoutTime" BU_SG_REL_ LEH_PlugIn SG_ 1699 BMS_HYB_06_CHK 5000;
BA_REL_ "GenSigTimeoutTime" BU_SG_REL_ Motor_MED17_SIMOS8_PlugIn_PAG_PF SG_ 1699 BMS_HYB_06_CHK 5000;
BA_REL_ "GenSigTimeoutTime" BU_SG_REL_ Ladegeraet_PAG_PF SG_ 1699 BMS_HYB_06_BZ 5000;
BA_REL_ "GenSigTimeoutTime" BU_SG_REL_ LEH_PlugIn SG_ 1699 BMS_HYB_06_BZ 5000;
BA_REL_ "GenSigTimeoutTime" BU_SG_REL_ Motor_MED17_SIMOS8_PlugIn_PAG_PF SG_ 1699 BMS_HYB_06_BZ 5000;
BA_REL_ "GenSigTimeoutTime" BU_SG_REL_ Ladegeraet_PAG_PF SG_ 1699 BMS_Max_LadeSpannung 5000;
BA_REL_ "GenSigTimeoutTime" BU_SG_REL_ LEH_PlugIn SG_ 1699 BMS_Max_LadeSpannung 5000;
BA_REL_ "GenSigTimeoutTime" BU_SG_REL_ Motor_MED17_SIMOS8_PlugIn_PAG_PF SG_ 1699 BMS_Max_LadeSpannung 5000;
BA_REL_ "GenSigTimeoutTime" BU_SG_REL_ Ladegeraet_PAG_PF SG_ 1699 BMS_Min_EntladeSpannung 5000;
BA_REL_ "GenSigTimeoutTime" BU_SG_REL_ LEH_PlugIn SG_ 1699 BMS_Min_EntladeSpannung 5000;
BA_REL_ "GenSigTimeoutTime" BU_SG_REL_ Motor_MED17_SIMOS8_PlugIn_PAG_PF SG_ 1699 BMS_Min_EntladeSpannung 5000;
BA_REL_ "GenSigTimeoutTime" BU_SG_REL_ Ladegeraet_PAG_PF SG_ 1699 BMS_Temperatur 5000;
BA_REL_ "GenSigTimeoutTime" BU_SG_REL_ LEH_PlugIn SG_ 1699 BMS_Temperatur 5000;
BA_REL_ "GenSigTimeoutTime" BU_SG_REL_ Motor_MED17_SIMOS8_PlugIn_PAG_PF SG_ 1699 BMS_Temperatur 5000;
BA_REL_ "GenSigTimeoutTime" BU_SG_REL_ LEH_PlugIn SG_ 1699 BMS_Temperatur_Ansaugluft 5000;
BA_REL_ "GenSigTimeoutTime" BU_SG_REL_ Motor_MED17_SIMOS8_PlugIn_PAG_PF SG_ 1699 BMS_Temperatur_Ansaugluft 5000;
BA_REL_ "GenSigTimeoutTime" BU_SG_REL_ Ladegeraet_PAG_PF SG_ 1699 BMS_Ausgleichsladung_Anf 5000;
BA_REL_ "GenSigTimeoutTime" BU_SG_REL_ LEH_PlugIn SG_ 1699 BMS_Ausgleichsladung_Anf 5000;
BA_REL_ "GenSigTimeoutTime" BU_SG_REL_ Motor_MED17_SIMOS8_PlugIn_PAG_PF SG_ 1699 BMS_Ausgleichsladung_Anf 5000;
BA_REL_ "GenSigTimeoutTime" BU_SG_REL_ LEH_PlugIn SG_ 1699 BMS_Umluftklappe_Anf 5000;
BA_REL_ "GenSigTimeoutTime" BU_SG_REL_ Motor_MED17_SIMOS8_PlugIn_PAG_PF SG_ 1699 BMS_Umluftklappe_Anf 5000;
BA_REL_ "GenSigTimeoutTime" BU_SG_REL_ LEH_PlugIn SG_ 1699 BMS_OBD_Lampe_Anf 5000;
BA_REL_ "GenSigTimeoutTime" BU_SG_REL_ Motor_MED17_SIMOS8_PlugIn_PAG_PF SG_ 1699 BMS_OBD_Lampe_Anf 5000;
BA_REL_ "GenSigTimeoutTime" BU_SG_REL_ LEH_PlugIn SG_ 1699 BMS_Warnlampe_Anf 5000;
BA_REL_ "GenSigTimeoutTime" BU_SG_REL_ Motor_MED17_SIMOS8_PlugIn_PAG_PF SG_ 1699 BMS_Warnlampe_Anf 5000;
BA_REL_ "GenSigTimeoutTime" BU_SG_REL_ LEH_PlugIn SG_ 1699 BMS_Fehlerlampe_Anf 5000;
BA_REL_ "GenSigTimeoutTime" BU_SG_REL_ Motor_MED17_SIMOS8_PlugIn_PAG_PF SG_ 1699 BMS_Fehlerlampe_Anf 5000;
BA_REL_ "GenSigTimeoutTime" BU_SG_REL_ Ladegeraet_PAG_PF SG_ 1723 BMS_Energieinhalt 5000;
BA_REL_ "GenSigTimeoutTime" BU_SG_REL_ Motor_MED17_SIMOS8_PlugIn_PAG_PF SG_ 1723 BMS_Energieinhalt 5000;
BA_REL_ "GenSigTimeoutTime" BU_SG_REL_ Ladegeraet_PAG_PF SG_ 1723 BMS_Kapazitaet 5000;
BA_REL_ "GenSigTimeoutTime" BU_SG_REL_ Motor_MED17_SIMOS8_PlugIn_PAG_PF SG_ 1723 BMS_Kapazitaet 5000;
BA_REL_ "GenSigTimeoutTime" BU_SG_REL_ Ladegeraet_PAG_PF SG_ 1723 BMS_Temperierung_Anf 5000;
BA_REL_ "GenSigTimeoutTime" BU_SG_REL_ Motor_MED17_SIMOS8_PlugIn_PAG_PF SG_ 1723 BMS_Temperierung_Anf 5000;
BA_REL_ "GenSigTimeoutTime" BU_SG_REL_ Ladegeraet_PAG_PF SG_ 1161 BMS_Status_DCLS 1000;
BA_REL_ "GenSigTimeoutTime" BU_SG_REL_ Ladegeraet_PAG_PF SG_ 1161 BMS_DCLS_Spannung 1000;
BA_REL_ "GenSigTimeoutTime" BU_SG_REL_ Motor_MED17_SIMOS8_PlugIn_PAG_PF SG_ 1161 BMS_HVBatt_Perf_Ind 1000;
BA_REL_ "GenSigTimeoutTime" BU_SG_REL_ Motor_MED17_SIMOS8_PlugIn_PAG_PF SG_ 1161 BMS_SOC_HiRes 1000;
BA_REL_ "GenSigTimeoutTime" BU_SG_REL_ Motor_MED17_SIMOS8_PlugIn_PAG_PF SG_ 1161 BMS_Anf_Mo_Luefter 1000;
BA_REL_ "GenSigTimeoutTime" BU_SG_REL_ Motor_MED17_SIMOS8_PlugIn_PAG_PF SG_ 127 CCU_HYB_01_CHK 500;
BA_REL_ "GenSigTimeoutTime" BU_SG_REL_ Motor_MED17_SIMOS8_PlugIn_PAG_PF SG_ 127 CCU_HYB_01_BZ 500;
BA_REL_ "GenSigTimeoutTime" BU_SG_REL_ Motor_MED17_SIMOS8_PlugIn_PAG_PF SG_ 127 CCU_Strom_momentbildend 500;
BA_REL_ "GenSigTimeoutTime" BU_SG_REL_ Motor_MED17_SIMOS8_PlugIn_PAG_PF SG_ 127 CCU_IstWinkelGeschw 500;
BA_REL_ "GenSigTimeoutTime" BU_SG_REL_ Motor_MED17_SIMOS8_PlugIn_PAG_PF SG_ 127 CCU_Fehler_HW 500;
BA_REL_ "GenSigTimeoutTime" BU_SG_REL_ Motor_MED17_SIMOS8_PlugIn_PAG_PF SG_ 127 CCU_Fehler_mechanisch 500;
BA_REL_ "GenSigTimeoutTime" BU_SG_REL_ Motor_MED17_SIMOS8_PlugIn_PAG_PF SG_ 127 CCU_Fehler_CAN 500;
BA_REL_ "GenSigTimeoutTime" BU_SG_REL_ Motor_MED17_SIMOS8_PlugIn_PAG_PF SG_ 127 CCU_Fehler_Unterspannung 500;
BA_REL_ "GenSigTimeoutTime" BU_SG_REL_ Motor_MED17_SIMOS8_PlugIn_PAG_PF SG_ 127 CCU_Warnung_Temperatur 500;
BA_REL_ "GenSigTimeoutTime" BU_SG_REL_ Motor_MED17_SIMOS8_PlugIn_PAG_PF SG_ 127 CCU_Fehler_Temperatur 500;
BA_REL_ "GenSigTimeoutTime" BU_SG_REL_ Motor_MED17_SIMOS8_PlugIn_PAG_PF SG_ 127 CCU_SleepInd 500;
BA_REL_ "GenSigTimeoutTime" BU_SG_REL_ Motor_MED17_SIMOS8_PlugIn_PAG_PF SG_ 127 CCU_IstPosition 500;
BA_REL_ "GenSigTimeoutTime" BU_SG_REL_ Motor_MED17_SIMOS8_PlugIn_PAG_PF SG_ 127 CCU_Istmodus 500;
BA_REL_ "GenSigTimeoutTime" BU_SG_REL_ Motor_MED17_SIMOS8_PlugIn_PAG_PF SG_ 127 CCU_IstDruck 500;
BA_REL_ "GenSigTimeoutTime" BU_SG_REL_ Motor_MED17_SIMOS8_PlugIn_PAG_PF SG_ 156 DC_HYB_01_CHK 500;
BA_REL_ "GenSigTimeoutTime" BU_SG_REL_ Motor_MED17_SIMOS8_PlugIn_PAG_PF SG_ 156 DC_HYB_01_BZ 500;
BA_REL_ "GenSigTimeoutTime" BU_SG_REL_ BMS_PlugIn SG_ 156 DC_IstSpannung_HV 500;
BA_REL_ "GenSigTimeoutTime" BU_SG_REL_ Motor_MED17_SIMOS8_PlugIn_PAG_PF SG_ 156 DC_IstSpannung_HV 500;
BA_REL_ "GenSigTimeoutTime" BU_SG_REL_ BMS_PlugIn SG_ 156 DC_IstStrom_HV 500;
BA_REL_ "GenSigTimeoutTime" BU_SG_REL_ Ladegeraet_PAG_PF SG_ 156 DC_IstStrom_HV 500;
BA_REL_ "GenSigTimeoutTime" BU_SG_REL_ Motor_MED17_SIMOS8_PlugIn_PAG_PF SG_ 156 DC_IstStrom_HV 500;
BA_REL_ "GenSigTimeoutTime" BU_SG_REL_ Motor_MED17_SIMOS8_PlugIn_PAG_PF SG_ 156 DC_IstModus 500;
BA_REL_ "GenSigTimeoutTime" BU_SG_REL_ Motor_MED17_SIMOS8_PlugIn_PAG_PF SG_ 156 DC_LangsRegelung_aktiv 500;
BA_REL_ "GenSigTimeoutTime" BU_SG_REL_ Motor_MED17_SIMOS8_PlugIn_PAG_PF SG_ 156 DC_SleepInd 500;
BA_REL_ "GenSigTimeoutTime" BU_SG_REL_ Motor_MED17_SIMOS8_PlugIn_PAG_PF SG_ 156 DC_Fehler_intern 500;
BA_REL_ "GenSigTimeoutTime" BU_SG_REL_ Motor_MED17_SIMOS8_PlugIn_PAG_PF SG_ 156 DC_Fehler_Leistungsred 500;
BA_REL_ "GenSigTimeoutTime" BU_SG_REL_ Motor_MED17_SIMOS8_PlugIn_PAG_PF SG_ 156 DC_Fehler_Spannung 500;
BA_REL_ "GenSigTimeoutTime" BU_SG_REL_ Motor_MED17_SIMOS8_PlugIn_PAG_PF SG_ 943 DC_HYB_02_CHK 1000;
BA_REL_ "GenSigTimeoutTime" BU_SG_REL_ Motor_MED17_SIMOS8_PlugIn_PAG_PF SG_ 943 DC_HYB_02_BZ 1000;
BA_REL_ "GenSigTimeoutTime" BU_SG_REL_ Motor_MED17_SIMOS8_PlugIn_PAG_PF SG_ 943 DC_IstSpannung_NV 1000;
BA_REL_ "GenSigTimeoutTime" BU_SG_REL_ Motor_MED17_SIMOS8_PlugIn_PAG_PF SG_ 943 DC_IstStrom_NV 1000;
BA_REL_ "GenSigTimeoutTime" BU_SG_REL_ Motor_MED17_SIMOS8_PlugIn_PAG_PF SG_ 943 DC_IdentifikationsNr 1000;
BA_REL_ "GenSigTimeoutTime" BU_SG_REL_ Motor_MED17_SIMOS8_PlugIn_PAG_PF SG_ 943 DC_Temperatur 1000;
BA_REL_ "GenSigTimeoutTime" BU_SG_REL_ Motor_MED17_SIMOS8_PlugIn_PAG_PF SG_ 943 DC_Auslastungsgrad 1000;
BA_REL_ "GenSigTimeoutTime" BU_SG_REL_ Motor_MED17_SIMOS8_PlugIn_PAG_PF SG_ 943 DC_Abregelung_StromLim_HV 1000;
BA_REL_ "GenSigTimeoutTime" BU_SG_REL_ Motor_MED17_SIMOS8_PlugIn_PAG_PF SG_ 943 DC_Abregelung_StromLim_NV 1000;
BA_REL_ "GenSigTimeoutTime" BU_SG_REL_ Motor_MED17_SIMOS8_PlugIn_PAG_PF SG_ 943 DC_Abregelung_SpannungLim_HV 1000;
BA_REL_ "GenSigTimeoutTime" BU_SG_REL_ Motor_MED17_SIMOS8_PlugIn_PAG_PF SG_ 943 DC_Abregelung_SpannungLim_NV 1000;
BA_REL_ "GenSigTimeoutTime" BU_SG_REL_ Motor_MED17_SIMOS8_PlugIn_PAG_PF SG_ 943 DC_Abregelung_Temperatur 1000;
BA_REL_ "GenSigTimeoutTime" BU_SG_REL_ Motor_MED17_SIMOS8_PlugIn_PAG_PF SG_ 152 EM_HYB_02_CHK 500;
BA_REL_ "GenSigTimeoutTime" BU_SG_REL_ Motor_MED17_SIMOS8_PlugIn_PAG_PF SG_ 152 EM_HYB_02_BZ 500;
BA_REL_ "GenSigTimeoutTime" BU_SG_REL_ Motor_MED17_SIMOS8_PlugIn_PAG_PF SG_ 152 EM_IstMoment 500;
BA_REL_ "GenSigTimeoutTime" BU_SG_REL_ Motor_MED17_SIMOS8_PlugIn_PAG_PF SG_ 152 EM_IstMoment_ohneAR 500;
BA_REL_ "GenSigTimeoutTime" BU_SG_REL_ Motor_MED17_SIMOS8_PlugIn_PAG_PF SG_ 152 EM_IstDrehzahl 500;
BA_REL_ "GenSigTimeoutTime" BU_SG_REL_ Motor_MED17_SIMOS8_PlugIn_PAG_PF SG_ 152 EM_AR_aktiv 500;
BA_REL_ "GenSigTimeoutTime" BU_SG_REL_ BMS_PlugIn SG_ 939 EM_HYB_03_CHK 1000;
BA_REL_ "GenSigTimeoutTime" BU_SG_REL_ BMS_PlugIn SG_ 939 EM_HYB_03_CHK 1000;
BA_REL_ "GenSigTimeoutTime" BU_SG_REL_ Motor_MED17_SIMOS8_PlugIn_PAG_PF SG_ 939 EM_HYB_03_CHK 1000;
BA_REL_ "GenSigTimeoutTime" BU_SG_REL_ BMS_PlugIn SG_ 939 EM_HYB_03_BZ 1000;
BA_REL_ "GenSigTimeoutTime" BU_SG_REL_ BMS_PlugIn SG_ 939 EM_HYB_03_BZ 1000;
BA_REL_ "GenSigTimeoutTime" BU_SG_REL_ Motor_MED17_SIMOS8_PlugIn_PAG_PF SG_ 939 EM_HYB_03_BZ 1000;
BA_REL_ "GenSigTimeoutTime" BU_SG_REL_ BMS_PlugIn SG_ 939 EM_IstSpannung 1000;
BA_REL_ "GenSigTimeoutTime" BU_SG_REL_ Motor_MED17_SIMOS8_PlugIn_PAG_PF SG_ 939 EM_IstSpannung 1000;
BA_REL_ "GenSigTimeoutTime" BU_SG_REL_ Motor_MED17_SIMOS8_PlugIn_PAG_PF SG_ 939 EM_IstStrom 1000;
BA_REL_ "GenSigTimeoutTime" BU_SG_REL_ Motor_MED17_SIMOS8_PlugIn_PAG_PF SG_ 939 EM_Abregelung_Temperatur 1000;
BA_REL_ "GenSigTimeoutTime" BU_SG_REL_ Motor_MED17_SIMOS8_PlugIn_PAG_PF SG_ 939 EM_Abregelung_MaxSpannung 1000;
BA_REL_ "GenSigTimeoutTime" BU_SG_REL_ Motor_MED17_SIMOS8_PlugIn_PAG_PF SG_ 939 EM_Abregelung_MinSpannung 1000;
BA_REL_ "GenSigTimeoutTime" BU_SG_REL_ Motor_MED17_SIMOS8_PlugIn_PAG_PF SG_ 939 EM_Abregelung_MaxStrom 1000;
BA_REL_ "GenSigTimeoutTime" BU_SG_REL_ Motor_MED17_SIMOS8_PlugIn_PAG_PF SG_ 939 EM_Abregelung_MinStrom 1000;
BA_REL_ "GenSigTimeoutTime" BU_SG_REL_ Motor_MED17_SIMOS8_PlugIn_PAG_PF SG_ 939 EM_Abregelung_MaxMoment 1000;
BA_REL_ "GenSigTimeoutTime" BU_SG_REL_ Motor_MED17_SIMOS8_PlugIn_PAG_PF SG_ 939 EM_Abregelung_MinMoment 1000;
BA_REL_ "GenSigTimeoutTime" BU_SG_REL_ Motor_MED17_SIMOS8_PlugIn_PAG_PF SG_ 939 EM_AnlernenElMotor_Anf 1000;
BA_REL_ "GenSigTimeoutTime" BU_SG_REL_ BMS_PlugIn SG_ 939 EM_Status_Spgfreiheit 1000;
BA_REL_ "GenSigTimeoutTime" BU_SG_REL_ Motor_MED17_SIMOS8_PlugIn_PAG_PF SG_ 940 EM_HYB_04_CHK 1000;
BA_REL_ "GenSigTimeoutTime" BU_SG_REL_ Motor_MED17_SIMOS8_PlugIn_PAG_PF SG_ 940 EM_HYB_04_BZ 1000;
BA_REL_ "GenSigTimeoutTime" BU_SG_REL_ Motor_MED17_SIMOS8_PlugIn_PAG_PF SG_ 940 EM_MaxPred_Moment 1000;
BA_REL_ "GenSigTimeoutTime" BU_SG_REL_ Motor_MED17_SIMOS8_PlugIn_PAG_PF SG_ 940 EM_MinPred_Moment 1000;
BA_REL_ "GenSigTimeoutTime" BU_SG_REL_ Motor_MED17_SIMOS8_PlugIn_PAG_PF SG_ 940 EM_MaxPred_Abknickdrehzahl 1000;
BA_REL_ "GenSigTimeoutTime" BU_SG_REL_ Motor_MED17_SIMOS8_PlugIn_PAG_PF SG_ 940 EM_MinPred_Abknickdrehzahl 1000;
BA_REL_ "GenSigTimeoutTime" BU_SG_REL_ Motor_MED17_SIMOS8_PlugIn_PAG_PF SG_ 940 EM_Moment_HVVerbraucher 1000;
BA_REL_ "GenSigTimeoutTime" BU_SG_REL_ Motor_MED17_SIMOS8_PlugIn_PAG_PF SG_ 1700 EM_HYB_05_CHK 5000;
BA_REL_ "GenSigTimeoutTime" BU_SG_REL_ Motor_MED17_SIMOS8_PlugIn_PAG_PF SG_ 1700 EM_HYB_05_BZ 5000;
BA_REL_ "GenSigTimeoutTime" BU_SG_REL_ Motor_MED17_SIMOS8_PlugIn_PAG_PF SG_ 1700 EM_OBD_Lampe_Anf 5000;
BA_REL_ "GenSigTimeoutTime" BU_SG_REL_ Motor_MED17_SIMOS8_PlugIn_PAG_PF SG_ 1700 EM_Warnlampe_Anf 5000;
BA_REL_ "GenSigTimeoutTime" BU_SG_REL_ Motor_MED17_SIMOS8_PlugIn_PAG_PF SG_ 1700 EM_Fehlerlampe_Anf 5000;
BA_REL_ "GenSigTimeoutTime" BU_SG_REL_ Motor_MED17_SIMOS8_PlugIn_PAG_PF SG_ 1700 EM_Temperatur_ElMotor 5000;
BA_REL_ "GenSigTimeoutTime" BU_SG_REL_ Motor_MED17_SIMOS8_PlugIn_PAG_PF SG_ 1700 EM_Temperatur_PWR 5000;
BA_REL_ "GenSigTimeoutTime" BU_SG_REL_ Motor_MED17_SIMOS8_PlugIn_PAG_PF SG_ 1700 EM_Temperatur_Rotor 5000;
BA_REL_ "GenSigTimeoutTime" BU_SG_REL_ Motor_MED17_SIMOS8_PlugIn_PAG_PF SG_ 1700 EM_HTKreis_Umgehung_Freigabe 5000;
BA_REL_ "GenSigTimeoutTime" BU_SG_REL_ Motor_MED17_SIMOS8_PlugIn_PAG_PF SG_ 153 EM_HYB_06_CHK 500;
BA_REL_ "GenSigTimeoutTime" BU_SG_REL_ Motor_MED17_SIMOS8_PlugIn_PAG_PF SG_ 153 EM_HYB_06_BZ 500;
BA_REL_ "GenSigTimeoutTime" BU_SG_REL_ Motor_MED17_SIMOS8_PlugIn_PAG_PF SG_ 153 EM_Istmodus 500;
BA_REL_ "GenSigTimeoutTime" BU_SG_REL_ Motor_MED17_SIMOS8_PlugIn_PAG_PF SG_ 153 EM_HV_betriebsbereit 500;
BA_REL_ "GenSigTimeoutTime" BU_SG_REL_ Motor_MED17_SIMOS8_PlugIn_PAG_PF SG_ 153 EM_SleepInd 500;
BA_REL_ "GenSigTimeoutTime" BU_SG_REL_ Motor_MED17_SIMOS8_PlugIn_PAG_PF SG_ 153 EM_ErwGrenzen_aktiv 500;
BA_REL_ "GenSigTimeoutTime" BU_SG_REL_ Motor_MED17_SIMOS8_PlugIn_PAG_PF SG_ 153 EM_Init_abgeschlossen 500;
BA_REL_ "GenSigTimeoutTime" BU_SG_REL_ Motor_MED17_SIMOS8_PlugIn_PAG_PF SG_ 153 EM_Fehler_ElAntriebAbschaltung 500;
BA_REL_ "GenSigTimeoutTime" BU_SG_REL_ Motor_MED17_SIMOS8_PlugIn_PAG_PF SG_ 153 EM_Fehler_Notabschaltung 500;
BA_REL_ "GenSigTimeoutTime" BU_SG_REL_ Motor_MED17_SIMOS8_PlugIn_PAG_PF SG_ 153 EM_Fehler_Leistungsred 500;
BA_REL_ "GenSigTimeoutTime" BU_SG_REL_ Motor_MED17_SIMOS8_PlugIn_PAG_PF SG_ 153 EM_Fehler_ElAntriebFreilauf 500;
BA_REL_ "GenSigTimeoutTime" BU_SG_REL_ Motor_MED17_SIMOS8_PlugIn_PAG_PF SG_ 153 EM_Max_Moment 500;
BA_REL_ "GenSigTimeoutTime" BU_SG_REL_ Motor_MED17_SIMOS8_PlugIn_PAG_PF SG_ 153 EM_Min_Moment 500;
BA_REL_ "GenSigTimeoutTime" BU_SG_REL_ Motor_MED17_SIMOS8_PlugIn_PAG_PF SG_ 153 EM_MaxDyn_Moment 500;
BA_REL_ "GenSigTimeoutTime" BU_SG_REL_ Motor_MED17_SIMOS8_PlugIn_PAG_PF SG_ 153 EM_MinDyn_Moment 500;
BA_REL_ "GenSigTimeoutTime" BU_SG_REL_ Motor_MED17_SIMOS8_PlugIn_PAG_PF SG_ 81 EM_IstDrehzahl 500;
BA_REL_ "GenSigTimeoutTime" BU_SG_REL_ Motor_MED17_SIMOS8_PlugIn_PAG_PF SG_ 195 GPM_01_CHK 500;
BA_REL_ "GenSigTimeoutTime" BU_SG_REL_ Motor_MED17_SIMOS8_PlugIn_PAG_PF SG_ 195 GPM_01_BZ 500;
BA_REL_ "GenSigTimeoutTime" BU_SG_REL_ Motor_MED17_SIMOS8_PlugIn_PAG_PF SG_ 195 GPM_State 500;
BA_REL_ "GenSigTimeoutTime" BU_SG_REL_ Motor_MED17_SIMOS8_PlugIn_PAG_PF SG_ 195 GPM_AspAktuatorweg 500;
BA_REL_ "GenSigTimeoutTime" BU_SG_REL_ Motor_MED17_SIMOS8_PlugIn_PAG_PF SG_ 195 GPM_AspPedalweg 500;
BA_REL_ "GenSigTimeoutTime" BU_SG_REL_ Motor_MED17_SIMOS8_PlugIn_PAG_PF SG_ 195 GPM_AktuatorUebertreten 500;
BA_REL_ "GenSigTimeoutTime" BU_SG_REL_ Motor_MED17_SIMOS8_PlugIn_PAG_PF SG_ 195 GPM_Fehler_mechanisch 500;
BA_REL_ "GenSigTimeoutTime" BU_SG_REL_ Motor_MED17_SIMOS8_PlugIn_PAG_PF SG_ 195 GPM_Fehler_CAN 500;
BA_REL_ "GenSigTimeoutTime" BU_SG_REL_ Motor_MED17_SIMOS8_PlugIn_PAG_PF SG_ 195 GPM_SleepInd 500;
BA_REL_ "GenSigTimeoutTime" BU_SG_REL_ Motor_MED17_SIMOS8_PlugIn_PAG_PF SG_ 195 GPM_Fehler_Unterspannung 500;
BA_REL_ "GenSigTimeoutTime" BU_SG_REL_ Motor_MED17_SIMOS8_PlugIn_PAG_PF SG_ 195 GPM_Fehler_Temperatur 500;
BA_REL_ "GenSigTimeoutTime" BU_SG_REL_ Motor_MED17_SIMOS8_PlugIn_PAG_PF SG_ 195 GPM_Fehler_HW 500;
BA_REL_ "GenSigTimeoutTime" BU_SG_REL_ Motor_MED17_SIMOS8_PlugIn_PAG_PF SG_ 195 GPM_Warnung_Temperatur 500;
BA_REL_ "GenSigTimeoutTime" BU_SG_REL_ Motor_MED17_SIMOS8_PlugIn_PAG_PF SG_ 1705 GPM_TeileNr_Mux 5000;
BA_REL_ "GenSigTimeoutTime" BU_SG_REL_ Motor_MED17_SIMOS8_PlugIn_PAG_PF SG_ 1705 GPM_TeileNr_Word_01 5000;
BA_REL_ "GenSigTimeoutTime" BU_SG_REL_ Motor_MED17_SIMOS8_PlugIn_PAG_PF SG_ 1705 GPM_TeileNr_Word_02 5000;
BA_REL_ "GenSigTimeoutTime" BU_SG_REL_ Motor_MED17_SIMOS8_PlugIn_PAG_PF SG_ 1705 GPM_TeileNr_Word_03 5000;
BA_REL_ "GenSigTimeoutTime" BU_SG_REL_ Motor_MED17_SIMOS8_PlugIn_PAG_PF SG_ 1705 GPM_TeileNr_Word_04 5000;
BA_REL_ "GenSigTimeoutTime" BU_SG_REL_ Motor_MED17_SIMOS8_PlugIn_PAG_PF SG_ 1705 GPM_TeileNr_Word_05 5000;
BA_REL_ "GenSigTimeoutTime" BU_SG_REL_ Motor_MED17_SIMOS8_PlugIn_PAG_PF SG_ 1705 GPM_TeileNr_Word_06 5000;
BA_REL_ "GenSigTimeoutTime" BU_SG_REL_ Motor_MED17_SIMOS8_PlugIn_PAG_PF SG_ 1705 GPM_TeileNr_Word_07 5000;
BA_REL_ "GenSigTimeoutTime" BU_SG_REL_ Motor_MED17_SIMOS8_PlugIn_PAG_PF SG_ 1705 GPM_TeileNr_Word_08 5000;
BA_REL_ "GenSigTimeoutTime" BU_SG_REL_ Motor_MED17_SIMOS8_PlugIn_PAG_PF SG_ 1705 GPM_TeileNr_Word_09 5000;
BA_REL_ "GenSigTimeoutTime" BU_SG_REL_ Motor_MED17_SIMOS8_PlugIn_PAG_PF SG_ 1705 GPM_TeileNr_Word_10 5000;
BA_REL_ "GenSigTimeoutTime" BU_SG_REL_ Motor_MED17_SIMOS8_PlugIn_PAG_PF SG_ 1705 GPM_TeileNr_Word_11 5000;
BA_REL_ "GenSigTimeoutTime" BU_SG_REL_ Motor_MED17_SIMOS8_PlugIn_PAG_PF SG_ 1705 GPM_TeileNr_Word_12 5000;
BA_REL_ "GenSigTimeoutTime" BU_SG_REL_ Motor_MED17_SIMOS8_PlugIn_PAG_PF SG_ 1705 GPM_TeileNr_Word_13 5000;
BA_REL_ "GenSigTimeoutTime" BU_SG_REL_ Motor_MED17_SIMOS8_PlugIn_PAG_PF SG_ 1705 GPM_TeileNr_Word_14 5000;
BA_REL_ "GenSigTimeoutTime" BU_SG_REL_ Motor_MED17_SIMOS8_PlugIn_PAG_PF SG_ 1705 GPM_TeileNr_Word_15 5000;
BA_REL_ "GenSigTimeoutTime" BU_SG_REL_ Motor_MED17_SIMOS8_PlugIn_PAG_PF SG_ 1705 GPM_TeileNr_Word_16 5000;
BA_REL_ "GenSigTimeoutTime" BU_SG_REL_ Motor_MED17_SIMOS8_PlugIn_PAG_PF SG_ 1705 GPM_Seriennummer 5000;
BA_REL_ "GenSigTimeoutTime" BU_SG_REL_ Motor_MED17_SIMOS8_PlugIn_PAG_PF SG_ 1705 GPM_HW_Version 5000;
BA_REL_ "GenSigTimeoutTime" BU_SG_REL_ Motor_MED17_SIMOS8_PlugIn_PAG_PF SG_ 1705 GPM_SW_Version 5000;
BA_REL_ "GenSigTimeoutTime" BU_SG_REL_ BMS_PlugIn SG_ 1382 HVLM_01_CHK 1000;
BA_REL_ "GenSigTimeoutTime" BU_SG_REL_ Motor_MED17_SIMOS8_PlugIn_PAG_PF SG_ 1382 HVLM_01_CHK 1000;
BA_REL_ "GenSigTimeoutTime" BU_SG_REL_ BMS_PlugIn SG_ 1382 HVLM_01_BZ 1000;
BA_REL_ "GenSigTimeoutTime" BU_SG_REL_ Motor_MED17_SIMOS8_PlugIn_PAG_PF SG_ 1382 HVLM_01_BZ 1000;
BA_REL_ "GenSigTimeoutTime" BU_SG_REL_ Motor_MED17_SIMOS8_PlugIn_PAG_PF SG_ 1382 HVLM_IstStrom 1000;
BA_REL_ "GenSigTimeoutTime" BU_SG_REL_ Motor_MED17_SIMOS8_PlugIn_PAG_PF SG_ 1382 HVLM_IstModus_02 1000;
BA_REL_ "GenSigTimeoutTime" BU_SG_REL_ Motor_MED17_SIMOS8_PlugIn_PAG_PF SG_ 1382 HVLM_Konditionierung_Anf 1000;
BA_REL_ "GenSigTimeoutTime" BU_SG_REL_ Motor_MED17_SIMOS8_PlugIn_PAG_PF SG_ 1382 HVLM_LadeAnforderung 1000;
BA_REL_ "GenSigTimeoutTime" BU_SG_REL_ BMS_PlugIn SG_ 1382 HVLM_Stecker_Status 1000;
BA_REL_ "GenSigTimeoutTime" BU_SG_REL_ Motor_MED17_SIMOS8_PlugIn_PAG_PF SG_ 1382 HVLM_Stecker_Status 1000;
BA_REL_ "GenSigTimeoutTime" BU_SG_REL_ BMS_PlugIn SG_ 1381 HVLM_Start_Spannungsmessung_DCLS 5000;
BA_REL_ "GenSigTimeoutTime" BU_SG_REL_ BMS_PlugIn SG_ 1380 LAD_01_CHK 5000;
BA_REL_ "GenSigTimeoutTime" BU_SG_REL_ BMS_PlugIn SG_ 1380 LAD_01_BZ 5000;
BA_REL_ "GenSigTimeoutTime" BU_SG_REL_ BMS_PlugIn SG_ 1380 LAD_IstSpannung_HV 5000;
BA_REL_ "GenSigTimeoutTime" BU_SG_REL_ BMS_PlugIn SG_ 1380 LAD_Status_Spgfreiheit 5000;
BA_REL_ "GenSigTimeoutTime" BU_SG_REL_ BMS_PlugIn SG_ 1662 LAD_Kuehlbedarf 5000;
BA_REL_ "GenSigTimeoutTime" BU_SG_REL_ BMS_PlugIn SG_ 934 MSG_HYB_01_CHK 1000;
BA_REL_ "GenSigTimeoutTime" BU_SG_REL_ CCU_VW526 SG_ 934 MSG_HYB_01_CHK 1000;
BA_REL_ "GenSigTimeoutTime" BU_SG_REL_ Ladegeraet_PAG_PF SG_ 934 MSG_HYB_01_CHK 1000;
BA_REL_ "GenSigTimeoutTime" BU_SG_REL_ LEH_PlugIn SG_ 934 MSG_HYB_01_CHK 1000;
BA_REL_ "GenSigTimeoutTime" BU_SG_REL_ BMS_PlugIn SG_ 934 MSG_HYB_01_BZ 1000;
BA_REL_ "GenSigTimeoutTime" BU_SG_REL_ CCU_VW526 SG_ 934 MSG_HYB_01_BZ 1000;
BA_REL_ "GenSigTimeoutTime" BU_SG_REL_ Ladegeraet_PAG_PF SG_ 934 MSG_HYB_01_BZ 1000;
BA_REL_ "GenSigTimeoutTime" BU_SG_REL_ LEH_PlugIn SG_ 934 MSG_HYB_01_BZ 1000;
BA_REL_ "GenSigTimeoutTime" BU_SG_REL_ CCU_VW526 SG_ 934 MO_SleepAckn 1000;
BA_REL_ "GenSigTimeoutTime" BU_SG_REL_ LEH_PlugIn SG_ 934 MO_SleepAckn 1000;
BA_REL_ "GenSigTimeoutTime" BU_SG_REL_ BMS_PlugIn SG_ 934 MO_ErwGrenzen_Anf 1000;
BA_REL_ "GenSigTimeoutTime" BU_SG_REL_ LEH_PlugIn SG_ 934 MO_ErwGrenzen_Anf 1000;
BA_REL_ "GenSigTimeoutTime" BU_SG_REL_ BMS_PlugIn SG_ 934 MO_Fehler_Notentladung_Anf 1000;
BA_REL_ "GenSigTimeoutTime" BU_SG_REL_ Ladegeraet_PAG_PF SG_ 934 MO_Fehler_Notentladung_Anf 1000;
BA_REL_ "GenSigTimeoutTime" BU_SG_REL_ LEH_PlugIn SG_ 934 MO_Fehler_Notentladung_Anf 1000;
BA_REL_ "GenSigTimeoutTime" BU_SG_REL_ LEH_PlugIn SG_ 934 MO_DC_Sollmodus 1000;
BA_REL_ "GenSigTimeoutTime" BU_SG_REL_ LEH_PlugIn SG_ 934 MO_DC_LangsRegelung_Anf 1000;
BA_REL_ "GenSigTimeoutTime" BU_SG_REL_ BMS_PlugIn SG_ 934 MO_BMS_Sollmodus 1000;
BA_REL_ "GenSigTimeoutTime" BU_SG_REL_ BMS_PlugIn SG_ 934 MO_BMS_IsoMessung_Anf 1000;
BA_REL_ "GenSigTimeoutTime" BU_SG_REL_ Ladegeraet_PAG_PF SG_ 934 MO_LG_Sollmodus 1000;
BA_REL_ "GenSigTimeoutTime" BU_SG_REL_ Ladegeraet_PAG_PF SG_ 934 MO_Ladebereit 1000;
BA_REL_ "GenSigTimeoutTime" BU_SG_REL_ LEH_PlugIn SG_ 935 MSG_HYB_02_CHK 1000;
BA_REL_ "GenSigTimeoutTime" BU_SG_REL_ LEH_PlugIn SG_ 935 MSG_HYB_02_BZ 1000;
BA_REL_ "GenSigTimeoutTime" BU_SG_REL_ LEH_PlugIn SG_ 935 MO_DC_SollSpannung_NV 1000;
BA_REL_ "GenSigTimeoutTime" BU_SG_REL_ LEH_PlugIn SG_ 935 MO_DC_Max_Strom_HV 1000;
BA_REL_ "GenSigTimeoutTime" BU_SG_REL_ LEH_PlugIn SG_ 935 MO_DC_Min_Spannung_HV 1000;
BA_REL_ "GenSigTimeoutTime" BU_SG_REL_ LEH_PlugIn SG_ 935 MO_DC_SollSpannung_HV 1000;
BA_REL_ "GenSigTimeoutTime" BU_SG_REL_ LEH_PlugIn SG_ 935 MO_DC_Max_Strom_NV 1000;
BA_REL_ "GenSigTimeoutTime" BU_SG_REL_ LEH_PlugIn SG_ 935 MO_DC_Min_Spannung_NV 1000;
BA_REL_ "GenSigTimeoutTime" BU_SG_REL_ LEH_PlugIn SG_ 144 MSG_HYB_03_CHK 500;
BA_REL_ "GenSigTimeoutTime" BU_SG_REL_ LEH_PlugIn SG_ 144 MSG_HYB_03_BZ 500;
BA_REL_ "GenSigTimeoutTime" BU_SG_REL_ LEH_PlugIn SG_ 144 MO_EM_Sollmodus 500;
BA_REL_ "GenSigTimeoutTime" BU_SG_REL_ LEH_PlugIn SG_ 144 MO_EM_SollMoment 500;
BA_REL_ "GenSigTimeoutTime" BU_SG_REL_ LEH_PlugIn SG_ 144 MO_EM_SollDrehzahl 500;
BA_REL_ "GenSigTimeoutTime" BU_SG_REL_ LEH_PlugIn SG_ 144 MO_EM_SollSpannung 500;
BA_REL_ "GenSigTimeoutTime" BU_SG_REL_ LEH_PlugIn SG_ 145 MSG_HYB_07_CHK 500;
BA_REL_ "GenSigTimeoutTime" BU_SG_REL_ LEH_PlugIn SG_ 145 MSG_HYB_07_BZ 500;
BA_REL_ "GenSigTimeoutTime" BU_SG_REL_ LEH_PlugIn SG_ 145 MO_EM_AR_Anf 500;
BA_REL_ "GenSigTimeoutTime" BU_SG_REL_ LEH_PlugIn SG_ 145 MO_EM_Dyn_Kp_AR 500;
BA_REL_ "GenSigTimeoutTime" BU_SG_REL_ LEH_PlugIn SG_ 145 MO_EM_Stat_Kp_AR 500;
BA_REL_ "GenSigTimeoutTime" BU_SG_REL_ LEH_PlugIn SG_ 145 MO_EM_DynLimit_AR 500;
BA_REL_ "GenSigTimeoutTime" BU_SG_REL_ LEH_PlugIn SG_ 145 MO_EM_StatLimit_AR 500;
BA_REL_ "GenSigTimeoutTime" BU_SG_REL_ LEH_PlugIn SG_ 145 MO_EM_Periode_AR 500;
BA_REL_ "GenSigTimeoutTime" BU_SG_REL_ LEH_PlugIn SG_ 145 MO_EM_Strom_HVVerbraucher 500;
BA_REL_ "GenSigTimeoutTime" BU_SG_REL_ LEH_PlugIn SG_ 146 MSG_HYB_08_CHK 500;
BA_REL_ "GenSigTimeoutTime" BU_SG_REL_ LEH_PlugIn SG_ 146 MSG_HYB_08_BZ 500;
BA_REL_ "GenSigTimeoutTime" BU_SG_REL_ LEH_PlugIn SG_ 146 MO_EM_MinMoment_DrzRegler 500;
BA_REL_ "GenSigTimeoutTime" BU_SG_REL_ LEH_PlugIn SG_ 146 MO_EM_MaxMoment_DrzRegler 500;
BA_REL_ "GenSigTimeoutTime" BU_SG_REL_ LEH_PlugIn SG_ 146 MO_EM_Band_KpKlein_DrzRegler 500;
BA_REL_ "GenSigTimeoutTime" BU_SG_REL_ LEH_PlugIn SG_ 146 MO_EM_KpKlein_DrzRegler 500;
BA_REL_ "GenSigTimeoutTime" BU_SG_REL_ LEH_PlugIn SG_ 146 MO_EM_KpGross_DrzRegler 500;
BA_REL_ "GenSigTimeoutTime" BU_SG_REL_ LEH_PlugIn SG_ 936 MSG_HYB_09_CHK 1000;
BA_REL_ "GenSigTimeoutTime" BU_SG_REL_ LEH_PlugIn SG_ 936 MSG_HYB_09_BZ 1000;
BA_REL_ "GenSigTimeoutTime" BU_SG_REL_ LEH_PlugIn SG_ 936 MO_EM_Max_Moment 1000;
BA_REL_ "GenSigTimeoutTime" BU_SG_REL_ LEH_PlugIn SG_ 936 MO_EM_Min_Moment 1000;
BA_REL_ "GenSigTimeoutTime" BU_SG_REL_ LEH_PlugIn SG_ 936 MO_EM_Max_Momentengradient 1000;
BA_REL_ "GenSigTimeoutTime" BU_SG_REL_ LEH_PlugIn SG_ 936 MO_EM_Max_Moment_AR 1000;
BA_REL_ "GenSigTimeoutTime" BU_SG_REL_ BMS_PlugIn SG_ 1698 MSG_HYB_10_CHK 5000;
BA_REL_ "GenSigTimeoutTime" BU_SG_REL_ LEH_PlugIn SG_ 1698 MSG_HYB_10_CHK 5000;
BA_REL_ "GenSigTimeoutTime" BU_SG_REL_ BMS_PlugIn SG_ 1698 MSG_HYB_10_BZ 5000;
BA_REL_ "GenSigTimeoutTime" BU_SG_REL_ LEH_PlugIn SG_ 1698 MSG_HYB_10_BZ 5000;
BA_REL_ "GenSigTimeoutTime" BU_SG_REL_ BMS_PlugIn SG_ 1698 MO_Abstellzeit 5000;
BA_REL_ "GenSigTimeoutTime" BU_SG_REL_ LEH_PlugIn SG_ 1698 MO_Abstellzeit 5000;
BA_REL_ "GenSigTimeoutTime" BU_SG_REL_ BMS_PlugIn SG_ 1698 MO_Abstellzeit_Status 5000;
BA_REL_ "GenSigTimeoutTime" BU_SG_REL_ LEH_PlugIn SG_ 1698 MO_Abstellzeit_Status 5000;
BA_REL_ "GenSigTimeoutTime" BU_SG_REL_ LEH_PlugIn SG_ 1698 MO_EM_NTKreisPumpe1_Status 5000;
BA_REL_ "GenSigTimeoutTime" BU_SG_REL_ LEH_PlugIn SG_ 1698 MO_EM_NTKreisPumpe2_Status 5000;
BA_REL_ "GenSigTimeoutTime" BU_SG_REL_ LEH_PlugIn SG_ 1698 MO_EM_NTKreis_Status 5000;
BA_REL_ "GenSigTimeoutTime" BU_SG_REL_ LEH_PlugIn SG_ 1698 MO_EM_HTKreisPumpe1_Status 5000;
BA_REL_ "GenSigTimeoutTime" BU_SG_REL_ LEH_PlugIn SG_ 1698 MO_EM_HTKreisPumpe2_Status 5000;
BA_REL_ "GenSigTimeoutTime" BU_SG_REL_ LEH_PlugIn SG_ 1698 MO_EM_HTKreis_Status 5000;
BA_REL_ "GenSigTimeoutTime" BU_SG_REL_ LEH_PlugIn SG_ 1698 MO_LuefterGeschw_rel 5000;
BA_REL_ "GenSigTimeoutTime" BU_SG_REL_ LEH_PlugIn SG_ 1698 MO_Temp_Kuehleraustritt 5000;
BA_REL_ "GenSigTimeoutTime" BU_SG_REL_ CCU_VW526 SG_ 150 MSG_HYB_15_CHK 500;
BA_REL_ "GenSigTimeoutTime" BU_SG_REL_ CCU_VW526 SG_ 150 MSG_HYB_15_BZ 500;
BA_REL_ "GenSigTimeoutTime" BU_SG_REL_ CCU_VW526 SG_ 150 MO_CCU_Sollmodus 500;
BA_REL_ "GenSigTimeoutTime" BU_SG_REL_ CCU_VW526 SG_ 150 MO_CCU_DruckLim_Anf 500;
BA_REL_ "GenSigTimeoutTime" BU_SG_REL_ CCU_VW526 SG_ 150 MO_CCU_PHEV_Mode 500;
BA_REL_ "GenSigTimeoutTime" BU_SG_REL_ CCU_VW526 SG_ 150 MO_CCU_HSR_Hyst 500;
BA_REL_ "GenSigTimeoutTime" BU_SG_REL_ CCU_VW526 SG_ 150 MO_CCU_Sollposition 500;
BA_REL_ "GenSigTimeoutTime" BU_SG_REL_ GPM_PAG_PF SG_ 196 MSG_HYB_22_CHK 500;
BA_REL_ "GenSigTimeoutTime" BU_SG_REL_ GPM_PAG_PF SG_ 196 MSG_HYB_22_BZ 500;
BA_REL_ "GenSigTimeoutTime" BU_SG_REL_ GPM_PAG_PF SG_ 196 MO_GPM_act_swt 500;
BA_REL_ "GenSigTimeoutTime" BU_SG_REL_ GPM_PAG_PF SG_ 196 MO_GPM_self_test 500;
BA_REL_ "GenSigTimeoutTime" BU_SG_REL_ GPM_PAG_PF SG_ 196 MO_QBit_GPM_Fahrpedalwerte_01 500;
BA_REL_ "GenSigTimeoutTime" BU_SG_REL_ GPM_PAG_PF SG_ 196 MO_GPM_sollact_pos 500;
BA_REL_ "GenSigTimeoutTime" BU_SG_REL_ GPM_PAG_PF SG_ 196 MO_GPM_sollactpv_pos 500;
BA_REL_ "GenSigTimeoutTime" BU_SG_REL_ GPM_PAG_PF SG_ 196 MO_GPM_Fahrpedalrohwert 500;
VAL_ 151 BMS_IstStrom 4094 "Init" 4095 "Fehler" ;
VAL_ 151 BMS_IstSpannung 4094 "Init" 4095 "Fehler" ;
VAL_ 151 BMS_IstModus 0 "stStdBy" 1 "stHV" 2 "stBalancing" 3 "stExternalCharging" 4 "stExternalChargingHV" 5 "Error_Batt" 6 "stExternalDCChargingHV" 7 "stInit" ;
VAL_ 151 BMS_SleepInd 0 "CAN_wird_benoetigt" 1 "Sleep_Indikation" ;
VAL_ 151 BMS_IsoMessungAktiv 1 "InsulationTest" ;
VAL_ 151 BMS_Init_abgeschlossen 1 "Ready_Init" ;
VAL_ 151 BMS_Status_Spgfreiheit 0 "Init" 1 "HV_Komponente_spannungsfrei" 2 "HV_Komp_nicht_spannungsfrei" 3 "Fehler_nicht_spannungsfrei" ;
VAL_ 151 BMS_Fehler_Notabschaltung_Crash 1 "Err_EmergcyShtOffCrash" ;
VAL_ 151 BMS_Fehler_Notabschaltung_Pilot 1 "Err_EmergcyShtOffPilotLine" ;
VAL_ 151 BMS_Fehler_HVBattAbschaltung_Anf 1 "Err_ShutOffRequest" ;
VAL_ 151 BMS_Fehler_HVBattAbschaltung 1 "Err_ShutOff" ;
VAL_ 151 BMS_Fehler_HS_verschweisst 1 "Err_ContactorWelding" ;
VAL_ 151 BMS_Fehler_HS_offen 1 "Err_ContactorOpen" ;
VAL_ 151 BMS_Fehler_Leistungsred 0 "keine_Leistungseinschraenkung" 1 "Leistungseinschraenkung" ;
VAL_ 151 BMS_Fehler_Isolation 1 "Err_Insulation" ;
VAL_ 151 BMS_Fehler_Kaltstartleistung 0 "kein_Fehler" 1 "Kaltstartleistung_zu_gering" ;
VAL_ 151 BMS_Fehler_Pilot 0 "geschlossen" 1 "Unterbrechung" ;
VAL_ 151 BMS_Fehler_Sicherung 0 "keine_Unterbrechung" 1 "Unterbrechung" ;
VAL_ 151 BMS_Status_ServiceDisconnect 0 "gesteckt" 1 "gezogen" ;
VAL_ 151 BMS_Status_Spannungsfreiheit 0 "BMS_HV_nicht_spannungsf" 1 "Fehler" 3 "BMS_HV_spannungsfrei" ;
VAL_ 151 BMS_Notfallkuehlung 0 "keine_Anforderung" 1 "Anforderung" ;
VAL_ 938 BMS_MaxPred_LadeStrom 1023 "Init" ;
VAL_ 938 BMS_MaxPred_EntladeStrom 1023 "Init" ;
VAL_ 938 BMS_MinPred_LadeSpannung 1023 "Init" ;
VAL_ 938 BMS_MinPred_EntladeSpannung 1023 "Init" ;
VAL_ 938 BMS_BattLuefterGeschw_rel 14 "Init" 15 "Fehler" ;
VAL_ 938 BMS_SOC 254 "Init" 255 "Fehler" ;
VAL_ 292 BMS_MinDyn_LadeSpannung 1023 "Init" ;
VAL_ 292 BMS_MinDyn_EntladeSpannung 1023 "Init" ;
VAL_ 292 BMS_MaxDyn_EntladeStrom 1023 "Init" ;
VAL_ 292 BMS_MaxDyn_LadeStrom 1023 "Init" ;
VAL_ 292 BMS_ErwGrenzen_aktiv 0 "Init" 1 "extended_Range" ;
VAL_ 292 BMS_Spannung_ZwKr 2046 "Init" 2047 "Fehler" ;
VAL_ 1699 BMS_Max_LadeSpannung 1022 "Init" 1023 "Fehler" ;
VAL_ 1699 BMS_Min_EntladeSpannung 1022 "Init" 1023 "Fehler" ;
VAL_ 1699 BMS_Temperatur 254 "Init" 255 "Fehler" ;
VAL_ 1699 BMS_Temperatur_Ansaugluft 254 "Init" 255 "Fehler" ;
VAL_ 1699 BMS_Ausgleichsladung_Anf 1 "Balancing_Request" ;
VAL_ 1699 BMS_Umluftklappe_Anf 1 "Ventilation_Request" ;
VAL_ 1699 BMS_OBD_Lampe_Anf 1 "MIL_Request" ;
VAL_ 1699 BMS_Warnlampe_Anf 1 "YellowLED_Request" ;
VAL_ 1699 BMS_Fehlerlampe_Anf 1 "RedLED_Request" ;
VAL_ 1699 BMS_Balancing_Anf 0 "keine_Anforderung" 1 "Regenerierung" 2 "Balancing" 3 "Nachladen" ;
VAL_ 1723 BMS_Energieinhalt 2046 "Init" 2047 "Fehler" ;
VAL_ 1723 BMS_Kapazitaet 2047 "Init" ;
VAL_ 1723 BMS_Temperierung_Anf 0 "hoher_Kuehlbedarf" 1 "mittlerer_Kuehlbedarf" 2 "niedriger_Kuehlbedarf" 3 "kein_Temperierungsbedarf_Init" 4 "niedriger_Heizbedarf" 5 "mittlerer_Heizbedarf" 6 "hoher_Heizbedarf" 7 "Umwaelzungsbedarf" ;
VAL_ 1723 BMS_min_Grenz_SOC 31 "Init" ;
VAL_ 1723 BMS_max_Grenz_SOC 31 "Init" ;
VAL_ 1723 BMS_MaxEnergieinhalt 2046 "Init" 2047 "Fehler" ;
VAL_ 1723 BMS_Zeitbedarf_Balancing 251 "Zeit_groesser_250_Minuten" 252 "reserviert" 253 "reserviert" 254 "Init" 255 "Zeit_nicht_verfuegbar" ;
VAL_ 1161 BMS_Status_DCLS 0 "inaktiv" 1 "i_O" 2 "n_i_O" 3 "aktiv" ;
VAL_ 1161 BMS_DCLS_Spannung 1022 "Init" 1023 "Fehler" ;
VAL_ 1161 BMS_HVBatt_Perf_Ind 254 "Init" 255 "Fehler" ;
VAL_ 1161 BMS_SOC_HiRes 2046 "Init" 2047 "Fehler" ;
VAL_ 1161 BMS_HV_Deaktivierungsmodus 0 "Init" 1 "HV_System_aktiv" 2 "HV_System_deaktiviert" 3 "Fehler" ;
VAL_ 1161 BMS_Anf_Mo_Luefter 254 "Init" 255 "Fehler" ;
VAL_ 127 CCU_Strom_momentbildend 4094 "Init" 4095 "Fehler" ;
VAL_ 127 CCU_IstWinkelGeschw 510 "Init" 511 "Fehler" ;
VAL_ 127 CCU_Fehler_HW 1 "Err_HW" ;
VAL_ 127 CCU_Fehler_mechanisch 1 "Err_Mech" ;
VAL_ 127 CCU_Fehler_CAN 1 "Err_CAN" ;
VAL_ 127 CCU_Fehler_Unterspannung 1 "Err_UBattLow" ;
VAL_ 127 CCU_Warnung_Temperatur 1 "Err_TempWarn" ;
VAL_ 127 CCU_Fehler_Temperatur 1 "Err_TempHigh" ;
VAL_ 127 CCU_SleepInd 0 "CAN_wird_benoetigt" 1 "Sleep_Indikation" ;
VAL_ 127 CCU_IstPosition 8190 "Init" 8191 "Fehler" ;
VAL_ 127 CCU_Istmodus 0 "Init_Mode" 1 "Secure_Mode" 2 "Operation_Mode" 3 "RemovingAir_Mode" 4 "Filling_Mode" 7 "Initialisierung" ;
VAL_ 127 CCU_IstDruck 254 "Init" 255 "Fehler" ;
VAL_ 1715 CCU_Medium 4 "Mineraloel_Pentosin" 7 "Bremsfluessigkeit" ;
VAL_ 1715 CCU_HW_Version 0 "A0_Muster" 1 "A1_Muster" 2 "A2_Muster" 3 "B0_Muster" 4 "B1_Muster" 5 "B2_Muster" 6 "B3_Muster" 7 "C0_Muster" 8 "C1_Muster" 9 "C2_Muster" 10 "Nullserie" 255 "Zwischenstand" ;
VAL_ 1715 CCU_SW_Version 105 "v105" 106 "v106" 107 "v107" 108 "v108" 109 "v109" ;
VAL_ 156 DC_IstSpannung_HV 4094 "Init" 4095 "Fehler" ;
VAL_ 156 DC_IstStrom_HV 1022 "Init" 1023 "Fehler" ;
VAL_ 156 DC_IstModus 0 "Standby" 1 "Tiefsetzen" 2 "Hochsetzen" 4 "Notstart" 5 "int_Fehler" 7 "Initialisierung" ;
VAL_ 156 DC_LangsRegelung_aktiv 0 "Reg_normal" 1 "Reg_langsam" ;
VAL_ 156 DC_SleepInd 0 "CAN_wird_benoetigt" 1 "Sleep_Indikation" ;
VAL_ 156 DC_Fehler_intern 0 "Init" ;
VAL_ 156 DC_Fehler_Leistungsred 0 "keine_Leistungseinschraenkung" 1 "Leistungseinschraenkung" ;
VAL_ 156 DC_Fehler_Spannung 0 "kein_Fehler" 1 "Fehler_Unterspannung" ;
VAL_ 156 DC_Verbrauch_Ueberlauf 0 "kein_Ueberlauf" 1 "Ueberlauf" ;
VAL_ 943 DC_IstSpannung_NV 254 "Init" 255 "Fehler" ;
VAL_ 943 DC_IstStrom_NV 1022 "Init" 1023 "Fehler" ;
VAL_ 943 DC_Temperatur 254 "Init" 255 "Fehler" ;
VAL_ 943 DC_Abregelung_StromLim_HV 0 "keine_Begrenzung" 1 "Abregelung_CrntPri" ;
VAL_ 943 DC_Abregelung_StromLim_NV 0 "keine_Begrenzung" 1 "Abregelung_CrntSec" ;
VAL_ 943 DC_Abregelung_SpannungLim_HV 0 "keine_Begrenzung" 1 "Abregelung_VltgPri" ;
VAL_ 943 DC_Abregelung_SpannungLim_NV 0 "keine_Begrenzung" 1 "Abregelung_VltgSec" ;
VAL_ 943 DC_Abregelung_Temperatur 0 "keine_Abregelung" 1 "Abregelung_Temp" ;
VAL_ 152 EM_IstMoment 4094 "Init" 4095 "Fehler" ;
VAL_ 152 EM_IstMoment_ohneAR 4094 "Init" 4095 "Fehler" ;
VAL_ 152 EM_IstDrehzahl 65534 "Init" 65535 "Fehler" ;
VAL_ 152 EM_Status_Spannungsfreiheit 0 "EM_HV_nicht_spannungsfrei" 1 "Fehler" 3 "EM_HV_spannungsfrei" ;
VAL_ 152 EM_AR_aktiv 0 "Init" ;
VAL_ 152 EM_Fehler_Notabschaltung_HVIL 0 "Init" 1 "HVIL_ist_OK" 2 "HVIL_Fehler" 3 "keine_Funktion" ;
VAL_ 939 EM_IstSpannung 4094 "Init" 4095 "Fehler" ;
VAL_ 939 EM_IstStrom 4094 "Init" 4095 "Fehler" ;
VAL_ 939 EM_Abregelung_Temperatur 0 "keine_Abregelung" 1 "Abregelung_Temperatur" ;
VAL_ 939 EM_Abregelung_MaxSpannung 0 "keine_Abregelung" 1 "Abregelung_Ueberspannung" ;
VAL_ 939 EM_Abregelung_MinSpannung 0 "keine_Abregelung" 1 "Abregelung_Unterspannung" ;
VAL_ 939 EM_Abregelung_MaxStrom 0 "keine_Abregelung" 1 "Abregelung_Ueberstrom_motorisch" ;
VAL_ 939 EM_Abregelung_MinStrom 0 "keine_Abregelung" 1 "Abregelung_Ueberstrom_generatorisch" ;
VAL_ 939 EM_Abregelung_MaxMoment 1 "Momentengrenzwert_M_Max" ;
VAL_ 939 EM_Abregelung_MinMoment 1 "Momentengrenzwert_M_Min" ;
VAL_ 939 EM_AnlernenElMotor_Anf 0 "Init" 1 "Diagnose_Request" ;
VAL_ 939 EM_Kuehlpumpe_Status 0 "kein_Fehler" 1 "Trockenlauf" 2 "blockiert" 3 "Drehz_Vorgabe_nicht_erreicht" 4 "Ueberhitzung_Pumpe" 5 "Hardware_Fehler" 7 "Init" ;
VAL_ 939 EM_Verlustleistung 254 "Init" 255 "Fehler" ;
VAL_ 939 EM_Freigabe_Verfallsinfo_WFS 0 "Aus" 1 "Ein" ;
VAL_ 939 EM_Status_Spgfreiheit 0 "Init" 1 "HV_Komponente_spannungsfrei" 2 "HV_Komp_nicht_spannungsfrei" 3 "Fehler_nicht_spannungsfrei" ;
VAL_ 940 EM_MaxPred_Moment 1023 "Init" ;
VAL_ 940 EM_MinPred_Moment 1023 "Init" ;
VAL_ 940 EM_MaxPred_Abknickdrehzahl 255 "Init" ;
VAL_ 940 EM_MinPred_Abknickdrehzahl 255 "Init" ;
VAL_ 940 EM_Moment_HVVerbraucher 1023 "Init" ;
VAL_ 1700 EM_OBD_Lampe_Anf 1 "MIL_Request" ;
VAL_ 1700 EM_Warnlampe_Anf 1 "YellowLED_Request" ;
VAL_ 1700 EM_Fehlerlampe_Anf 1 "RedLED_Request" ;
VAL_ 1700 EM_Fehler_Pilot 0 "geschlossen" 1 "Unterbrechung" ;
VAL_ 1700 EM_Temperatur_ElMotor 254 "Init" 255 "Fehler" ;
VAL_ 1700 EM_Temperatur_PWR 254 "Init" 255 "Fehler" ;
VAL_ 1700 EM_Temperatur_Rotor 254 "Init" 255 "Fehler" ;
VAL_ 1700 EM_HTKreis_Umgehung_Freigabe 0 "keine_Freigabe" 1 "Freigabe_Umgehung" 3 "Funktion_nicht_vorhanden" ;
VAL_ 153 EM_Istmodus 0 "Standby" 1 "Momentenreg" 2 "Int_Drehzahlreg" 3 "Spannungsreg" 4 "Ext_Drehzahlreg" 5 "Inverter_Fehler" 6 "Kalibrierung" 8 "Freilauf" 15 "Initialisierung" ;
VAL_ 153 EM_HV_betriebsbereit 0 "Init" 1 "Ready_HV" ;
VAL_ 153 EM_SleepInd 0 "CAN_wird_benoetigt" 1 "Sleep_Indikation" ;
VAL_ 153 EM_ErwGrenzen_aktiv 0 "Init" 1 "extended_Range" ;
VAL_ 153 EM_Init_abgeschlossen 0 "Init" 1 "Ready_Init" ;
VAL_ 153 EM_Fehler_ElAntriebAbschaltung 0 "Init" 1 "Fehler" ;
VAL_ 153 EM_Fehler_Notabschaltung 0 "Init" 1 "Fehler" ;
VAL_ 153 EM_Fehler_Leistungsred 0 "keine_Leistungseinschraenkung" 1 "Leistungseinschraenkung" ;
VAL_ 153 EM_Fehler_ElAntriebFreilauf 0 "Init" 1 "Fehler" ;
VAL_ 153 EM_Max_Moment 1023 "Init" ;
VAL_ 153 EM_Min_Moment 1023 "Init" ;
VAL_ 153 EM_MaxDyn_Moment 1023 "Init" ;
VAL_ 153 EM_MinDyn_Moment 1023 "Init" ;
VAL_ 81 EM_IstDrehzahl 65534 "Init" 65535 "Fehler" ;
VAL_ 195 GPM_State 0 "Kein Fehler erkannt" 1 "Selbstest wird durchgeführt" 2 "Selbsttest durchgeführt und i. O." 3 "Positionssensor nicht plausibel" 4 "Verklemmschutz aktiv" 5 "Strombegrenzung aktiv" 6 "Aktuator temporär verklemmt" 7 "Aktuator temporär nicht verfuegbar" 8 "Aktuator nicht verfuegbar" ;
VAL_ 195 GPM_AktuatorUebertreten 0 "Aktuator_nicht_uebertreten" 1 "Aktuator_uebertreten" ;
VAL_ 195 GPM_Fehler_mechanisch 0 "Kein Fehler" 1 "Fehler" ;
VAL_ 195 GPM_Fehler_CAN 0 "Kein Fehler" 1 "Fehler" ;
VAL_ 195 GPM_SleepInd 0 "CAN_wird_benoetigt" 1 "Sleep_Indikation" ;
VAL_ 195 GPM_Fehler_Unterspannung 0 "Kein Fehler" 1 "Fehler" ;
VAL_ 195 GPM_Fehler_Temperatur 0 "Kein Fehler" 1 "Fehler" ;
VAL_ 195 GPM_Fehler_HW 0 "Kein Fehler" 1 "Fehler" ;
VAL_ 195 GPM_Warnung_Temperatur 0 "Kein Fehler" 1 "Fehler" ;
VAL_ 1705 GPM_TeileNr_Mux 0 "ASCII-Word_1" 1 "ASCII-Word_2" 2 "ASCII-Word_3" 3 "ASCII-Word_4" 4 "ASCII-Word_5" 5 "ASCII-Word_6" 6 " ASCII-Word_7" 7 "ASCII-Word_8" 8 "ASCII-Word_9" 9 "ASCII-Word_10" 10 "ASCII-Word_11" 11 "ASCII-Word_12" 12 "ASCII-Word_13" 13 "ASCII-Word_14" 14 "ASCII-Word_15" 15 "ASCII-Word_16" ;
VAL_ 1705 GPM_HW_Version 0 "A0_Muster" 1 "A1_Muster" 2 "A2_Muster" 3 "B0_Muster" 4 "B1_Muster" 5 "B2_Muster" 6 "B3_Muster" 7 "C0_Muster" 8 "C1_Muster" 9 "C2_Muster" 10 "Nullserie" 254 "Zwischenstand" ;
VAL_ 1705 GPM_SW_Version 0 "0022" 1 "0023" 2 "0030" 3 "0040" 4 "0050" 5 "0051" ;
VAL_ 1382 HVLM_Fehler_Ladestecker 0 "kein_Fehler" 1 "Fehler" ;
VAL_ 1382 HVLM_Fehler_Verriegelung 0 "kein_Fehler" 1 "Fehler" ;
VAL_ 1382 HVLM_SollStrom_HV_Offset 0 "HVLM_SollStrom_HV +0A" 1 "HVLM_SollStrom_HV +0,1A" ;
VAL_ 1382 HVLM_IstStrom 510 "Init" 511 "Fehler" ;
VAL_ 1382 HVLM_IstModus_02 0 "inaktiv" 1 "aktiv" 2 "Init" 3 "Fehler" ;
VAL_ 1382 HVLM_Konditionierung_Anf 0 "keine_Anf" 1 "Bat_Kond_Anf" ;
VAL_ 1382 HVLM_LadeAnforderung 0 "keine_Anforderung" 1 "AC_Laden" 2 "DC_Laden" 3 "Nachladen_12V" 4 "Reserve" 5 "Reserve" 6 "Init" 7 "Fehler" ;
VAL_ 1382 HVLM_Stecker_Status 0 "Init" 1 "kein_Stecker_gesteckt" 2 "Stecker_erkannt_nicht_verriegelt" 3 "Stecker_erkannt_und_verriegelt" ;
VAL_ 1382 HVLM_SollStrom_HV 1022 "Init" 1023 "Fehler" ;
VAL_ 1382 HVLM_MaxSpannung_HV 1022 "Init" 1023 "Fehler" ;
VAL_ 1381 HVLM_HV_Abstellzeit 254 "Init" 255 "Fehler" ;
VAL_ 1381 HVLM_Zustand_LED 0 "Farbe_1__aus" 1 "Farbe_2__weiss" 2 "Farbe_3__gelb" 3 "Farbe_4__gruen" 4 "Farbe_5__rot" 5 "Farbe_3_pulsierend" 6 "Farbe_4_pulsierend" 7 "Farbe_5_pulsierend" 8 "Farbe_4_5_pulsierend" 14 "Init" 15 "Fehler" ;
VAL_ 1381 HVLM_MaxLadezeitDCHV 254 "Init" 255 "Fehler" ;
VAL_ 1381 HVLM_MaxStrom_Netz 126 "Init" 127 "Fehler" ;
VAL_ 1381 HVLM_LG_Sollmodus 0 "Standby" 1 "Netzladung" ;
VAL_ 1381 HVLM_FreigabeTankdeckel 0 "keine_Freigabe" 1 "Freigabe" 2 "Init" 3 "Fehler" ;
VAL_ 1381 HVLM_Stecker_Verriegeln 0 "Stecker_entriegeln" 1 "Stecker_verriegeln" 2 "Init" 3 "keine_Anforderung" ;
VAL_ 1381 HVLM_Start_Spannungsmessung_DCLS 0 "inaktiv" 1 "DCLS_mit_Diode_Start_Messung" 2 "DCLS_ohne_Diode_Start_Messung" 3 "reserve" ;
VAL_ 1381 HVLM_Taster_Profil_Laden_Anf 0 "nicht_aktiv" 1 "aktiv" 2 "Init" 3 "Fehler" ;
VAL_ 1381 HVLM_Taster_Sofort_Laden_Anf 0 "nicht_aktiv" 1 "aktiv" 2 "Init" 3 "Fehler" ;
VAL_ 1381 HVLM_FreigabeKlimatisierung 0 "keine_Freigabe" 1 "Freigabe" 2 "Init" 3 "Fehler" ;
VAL_ 1381 HVLM_Ladetexte 0 "Keine_Anzeige" 1 "AC_Laden_nicht_moeglich" 2 "DC_Laden_nicht_moeglich" 3 "AC_und_DC_Laden_nicht_moeglich" ;
VAL_ 1381 HVLM_IstSpannung_HV 1022 "Init" 1023 "Fehler" ;
VAL_ 1380 LAD_IstModus 0 "Standby" 1 "AC_Netzladung" 3 "DC_Netzladung" 4 "Reserve" 5 "Fehler" 7 "Init" ;
VAL_ 1380 LAD_AC_Istspannung 510 "Init" 511 "Fehler" ;
VAL_ 1380 LAD_IstSpannung_HV 1022 "Init" 1023 "Fehler" ;
VAL_ 1380 LAD_IstStrom_HV 1022 "Init" 1023 "Fehler" ;
VAL_ 1380 LAD_Status_Spgfreiheit 0 "Init" 1 "HV_Komponente_spannungsfrei" 2 "HV_Komp_nicht_spannungsfrei" 3 "Fehler_nicht_spannungsfrei" ;
VAL_ 1380 LAD_Temperatur 254 "Init" 255 "Fehler" ;
VAL_ 1380 LAD_Verlustleistung 254 "Init" 255 "Fehler" ;
VAL_ 1662 LAD_Abregelung_Temperatur 0 "keine_Begrenzung" 1 "Abregelung_Temp" ;
VAL_ 1662 LAD_Abregelung_IU_Ein_Aus 0 "keine_Abregelung" 1 "Abregelung_UI" ;
VAL_ 1662 LAD_Abregelung_BuchseTemp 0 "keine_Abregelung" 1 "Abregelung_Buchsentemp" ;
VAL_ 1662 LAD_Warnlampe_Anf 0 "Init" 1 "Fehlerlampe_gelb" ;
VAL_ 1662 LAD_MaxLadLeistung_HV 510 "Init" 511 "Fehler" ;
VAL_ 1662 LAD_CP_Stromlimit 126 "Init" 127 "Fehler" ;
VAL_ 1662 LAD_PRX_Stromlimit 0 "13_Ampere" 1 "20_Ampere" 2 "32_Ampere" 3 "63_Ampere" 6 "Init" 7 "Fehler" ;
VAL_ 1662 LAD_CP_Erkennung 0 "CP_nicht_erkannt" 1 "CP_erkannt" ;
VAL_ 1662 LAD_Stecker_Verriegelt 0 "nicht_verriegelt" 1 "verriegelt" ;
VAL_ 1662 LAD_Stecker_Gesteckt 0 "kein_Stecker_erkannt" 1 "Stecker_erkannt" ;
VAL_ 1662 LAD_Kuehlbedarf 0 "kein_Kuehlbedarf" 1 "geringer_Kuehlbedarf" 2 "mittlerer_Kuehlbedarf" 3 "hoher_Kuehlbedarf" ;
VAL_ 1662 LAD_MaxLadLeistung_HV_Offset 0 "LAD_MaxLadLeistung_HV +0W" 1 "LAD_MaxLadLeistung_HV +25W" 2 "LAD_MaxLadLeistung_HV +50W" 3 "LAD_MaxLadLeistung_HV +75W" ;
VAL_ 1662 LAD_Fehlerstatus 0 "Komponente_IO" 1 "Eingeschr_KompFkt_DC_Lad_NIO" 2 "Eingeschr_KompFkt_AC_Lad_NIO" 3 "Eingeschr_KompFkt_Interlock" 4 "Eingeschr_KompFkt_reserve" 5 "Eingeschr_KompFkt_reserve" 6 "Keine_Komponentenfunktion" 7 "Init" ;
VAL_ 1662 LAD_Warnzustand 0 "keine_Warnung" 1 "Warnung_aktiv" ;
VAL_ 1662 LAD_Fehlerzustand 0 "kein_Fehler_aktiv" 1 "Fehler_aktiv_Laden_beendet" ;
VAL_ 934 MO_SleepAckn 0 "CAN_wird_benoetigt" 1 "Sleep_Mode_Befehl" ;
VAL_ 934 MO_ErwGrenzen_Anf 0 "normal" 1 "erweitert" ;
VAL_ 934 MO_Fehler_Notentladung_Anf 0 "Init" ;
VAL_ 934 MO_DC_Sollmodus 0 "Standby" 1 "Tiefsetzen" 2 "Hochsetzen" 7 "Initialisierung" ;
VAL_ 934 MO_DC_LangsRegelung_Anf 0 "normale_Regelung" 1 "langsame_Regelung" ;
VAL_ 934 MO_BMS_Sollmodus 0 "Standby" 1 "HV_Netz_aktivieren" 2 "Balancing_Modus" 3 "externes_Laden_Fremdstart" 4 "externes_Laden_EV_PlugIn" 5 "nicht_verfuegbar" 6 "externes_DC_Laden_EV_PlugIn" 7 "Init" ;
VAL_ 934 MO_BMS_IsoMessung_Anf 0 "Init" 1 "Anforderung" ;
VAL_ 934 MO_HV_Deaktivierungsmodus 0 "Init" 1 "HV_System_Aktiv" 2 "HV_Sytem_Deaktiv" 3 "Fehler" ;
VAL_ 934 MO_LG_Sollmodus 0 "Standby" 1 "AC_Netzladung" 3 "DC_Netzladung" 7 "Init" ;
VAL_ 934 MO_Ladebereit 0 "Fahrzeug_nicht_ladebereit" 1 "Fahrzeug_ladebereit" ;
VAL_ 935 MO_DC_SollSpannung_NV 255 "Init" ;
VAL_ 935 MO_DC_Max_Strom_HV 255 "Init" ;
VAL_ 935 MO_DC_Min_Spannung_HV 255 "Init" ;
VAL_ 935 MO_DC_SollSpannung_HV 255 "Init" ;
VAL_ 935 MO_DC_Max_Strom_NV 255 "Init" ;
VAL_ 935 MO_DC_Min_Spannung_NV 255 "Init" ;
VAL_ 144 MO_EM_Sollmodus 0 "Standby" 1 "Momentenreg" 2 "Int_Drehzahlreg" 3 "Spannungsreg" 4 "Ext_Drehzahlreg" 6 "Kalibrierung" 8 "Freilauf" 15 "Initialisierung" ;
VAL_ 144 MO_EM_SollMoment 16383 "Init" ;
VAL_ 144 MO_EM_SollDrehzahl 32767 "Init" ;
VAL_ 144 MO_EM_SollSpannung 16383 "Init" ;
VAL_ 144 MO_Waehlpos 0 "Init_nicht_unterstuetzt" 1 "reserviert" 2 "P" 3 "R" 4 "N" 5 "D" 6 "B" 7 "Fehler" ;
VAL_ 145 MO_EM_AR_Anf 0 "DstC_aus" 1 "DstC_ext" 2 "DstC_int_ext" ;
VAL_ 145 MO_EM_Dyn_Kp_AR 255 "Init" ;
VAL_ 145 MO_EM_Stat_Kp_AR 255 "Init" ;
VAL_ 145 MO_EM_DynLimit_AR 255 "Init" ;
VAL_ 145 MO_EM_StatLimit_AR 255 "Init" ;
VAL_ 145 MO_EM_Periode_AR 255 "Init" ;
VAL_ 145 MO_EM_Strom_HVVerbraucher 255 "Init" ;
VAL_ 146 MO_EM_MinMoment_DrzRegler 8190 "Init" 8191 "Fehler" ;
VAL_ 146 MO_EM_MaxMoment_DrzRegler 8190 "Init" 8191 "Fehler" ;
VAL_ 146 MO_EM_Band_KpKlein_DrzRegler 1023 "Init" ;
VAL_ 146 MO_EM_KpKlein_DrzRegler 255 "Init" ;
VAL_ 146 MO_EM_KpGross_DrzRegler 255 "Init" ;
VAL_ 936 MO_EM_Max_Moment 1023 "Init" ;
VAL_ 936 MO_EM_Min_Moment 1023 "Init" ;
VAL_ 936 MO_EM_Max_Momentengradient 255 "Keine_Begrenzung" ;
VAL_ 936 MO_EM_Max_Moment_AR 0 "EM_Daempfung_Aus" ;
VAL_ 936 MO_EM_MaxPred_Strom 1023 "Init" ;
VAL_ 936 MO_EM_MinPred_Strom 1023 "Init" ;
VAL_ 1698 MO_EM_Kuehlpumpe_Soll 15 "Init" ;
VAL_ 1698 MO_Abstellzeit 254 "Init" 255 "Fehler" ;
VAL_ 1698 MO_Abstellzeit_Status 0 "Abstellzeit_nicht_berechnet" 1 "Abstellzeit_berechnet" 2 "Abstellzeit_Minimalwert" 3 "Abstellzeit_ungueltig" ;
VAL_ 1698 MO_EM_NTKreisPumpe1_Status 0 "Pumpe_aus" 1 "Pumpe_Teillast" 2 "Pumpe_Vollast" 3 "Pumpe_defekt" ;
VAL_ 1698 MO_EM_NTKreisPumpe2_Status 0 "Pumpe_aus" 1 "Pumpe_Teillast" 2 "Pumpe_Vollast" 3 "Pumpe_defekt" ;
VAL_ 1698 MO_EM_NTKreis_Status 0 "kein_Kuehlmittelfluss" 1 "norm_Kuehlmittelfluss" 2 "Fehler_red_Kuehlmittelfluss" 3 "Fehler_kein_Kuehlmittelfluss" ;
VAL_ 1698 MO_EM_HTKreisPumpe1_Status 0 "Pumpe_aus" 1 "Pumpe_Teillast" 2 "Pumpe_Vollast" 3 "Pumpe_defekt" ;
VAL_ 1698 MO_EM_HTKreisPumpe2_Status 0 "Pumpe_aus" 1 "Pumpe_Teillast" 2 "Pumpe_Vollast" 3 "Pumpe_defekt" ;
VAL_ 1698 MO_EM_HTKreis_Status 0 "kein_Kuehlmittelfluss" 1 "norm_Kuehlmittelfluss" 2 "Fehler_red_Kuehlmittelfluss" 3 "Fehler_kein_Kuehlmittelfluss" ;
VAL_ 1698 MO_LuefterGeschw_rel 14 "Init" 15 "Fehler" ;
VAL_ 1698 MO_Temp_Kuehleraustritt 0 "Sensor_nicht_verbaut_bzw_Signal_nicht_unterstuetzt" 254 "Init" 255 "Fehler" ;
VAL_ 150 MO_CCU_Sollmodus 1 "Secure_Mode" 2 "Operation_Mode" 3 "RemovingAir_Mode" 4 "Filling_Mode" 5 "Info_Mode" 7 "Initialisierung" ;
VAL_ 150 MO_CCU_DruckLim_Anf 0 "pLimReq_Off" 1 "pLimReq_On" ;
VAL_ 150 MO_CCU_PHEV_Mode 0 "keine_Sonderfunktion" 1 "Untertauchen" 2 "Haltestromreduktion" ;
VAL_ 150 MO_CCU_Sollposition 8191 "Init" ;
VAL_ 196 MO_GPM_act_swt 0 "Aktuatorposition beibehalten" 1 "Aktuator auf Nullposition fahren (abschalten)" ;
VAL_ 196 MO_GPM_self_test 0 "Aktuator-Selbstest angefordert" 1 "Aktuator-Selbstest nicht angefordert" ;
VAL_ 196 MO_QBit_GPM_Fahrpedalwerte_01 0 "Kein Fehler" 1 "Fehler" ;
VAL_ 196 MO_GPM_Fahrpedalrohwert 255 "Fehler" ;
